VERSION "BodyCANhs"

NS_ :

BS_:

BU_: CCM CEM DDM ETC PAM PDM POT PSMD PSMP TRM VCM Y20CCMV526M1 Vector_XXX

BO_ 528 CEMBodyFr19: 8 CEM
 SG_ ActvnOfDoorLiGroup_UB : 6|1@0+ (1,0) [0|1] ""  DDM,PDM
 SG_ ActvnOfDoorLiGroupActvnOfDoorAmb : 1|2@0+ (1,0) [0|3] ""  DDM,PDM
 SG_ ActvnOfDoorLiGroupActvnOfHndlAnd : 4|1@0+ (1,0) [0|1] ""  DDM,PDM
 SG_ ActvnOfDoorLiGroupAmbLiInten : 3|2@0+ (1,0) [0|3] ""  DDM,PDM
 SG_ ActvnOfDoorLiGroupAmbLiRedn : 5|1@0+ (1,0) [0|1] ""  DDM,PDM
 SG_ ChrgrSt : 14|3@0+ (1,0) [0|7] ""  VCM
 SG_ ChrgrSt_UB : 15|1@0+ (1,0) [0|1] ""  VCM
 SG_ DrvrSeatDispSpplFct : 50|3@0+ (1,0) [0|7] ""  PSMD
 SG_ DrvrSeatDispSpplFct_UB : 51|1@0+ (1,0) [0|1] ""  PSMD
 SG_ DstToEmpty : 26|11@0+ (1,0) [0|2000] ""  Vector_XXX
 SG_ DstToEmptyIndcd_UB : 28|1@0+ (1,0) [0|1] ""  Vector_XXX
 SG_ DstUnit : 27|1@0+ (1,0) [0|1] ""  Vector_XXX
 SG_ EngCooltInhbFlow : 10|1@0+ (1,0) [0|1] ""  CCM
 SG_ EngCooltInhbFlow_UB : 11|1@0+ (1,0) [0|1] ""  CCM
 SG_ EngOilPWarn : 29|1@0+ (1,0) [0|1] ""  VCM
 SG_ EngOilPWarn_UB : 30|1@0+ (1,0) [0|1] ""  VCM
 SG_ EngT : 23|8@0+ (1,-50) [-50|200] "degC"  CCM,VCM
 SG_ EngTGrp_UB : 7|1@0+ (1,0) [0|1] ""  CCM,VCM
 SG_ EngTQf : 9|2@0+ (1,0) [0|3] ""  CCM,VCM
 SG_ HvBattHeatgReq : 57|2@0+ (1,0) [0|3] ""  CCM
 SG_ HvBattHeatgReq_UB : 31|1@0+ (1,0) [0|1] ""  CCM
 SG_ HvBattHeatrVlvPosn : 53|1@0+ (1,0) [0|1] ""  CCM
 SG_ HvBattHeatrVlvPosn_UB : 52|1@0+ (1,0) [0|1] ""  CCM
 SG_ HvPwrEgyPrio : 42|3@0+ (1,0) [0|7] ""  CCM
 SG_ HvPwrEgyPrio_UB : 43|1@0+ (1,0) [0|1] ""  CCM
 SG_ OnBdChrgrHndlSts : 46|3@0+ (1,0) [0|7] ""  CCM,VCM
 SG_ OnBdChrgrHndlSts_UB : 47|1@0+ (1,0) [0|1] ""  CCM,VCM
 SG_ PassSeatSts : 55|2@0+ (1,0) [0|3] ""  CCM,PSMP
 SG_ PassSeatSts_UB : 63|1@0+ (1,0) [0|1] ""  CCM,PSMP
 SG_ SeatDispBtnPsd_UB : 62|1@0+ (1,0) [0|1] ""  PSMD,PSMP
 SG_ SeatDispBtnPsdDrvrSeatDispBtnPsd : 61|1@0+ (1,0) [0|1] ""  PSMD,PSMP
 SG_ SeatDispBtnPsdPassSeatDispBtnPsd : 60|1@0+ (1,0) [0|1] ""  PSMD,PSMP
 SG_ SteerWhlHeatgDurgClimaEnad : 58|1@0+ (1,0) [0|1] ""  CCM
 SG_ SteerWhlHeatgDurgClimaEnad_UB : 59|1@0+ (1,0) [0|1] ""  CCM

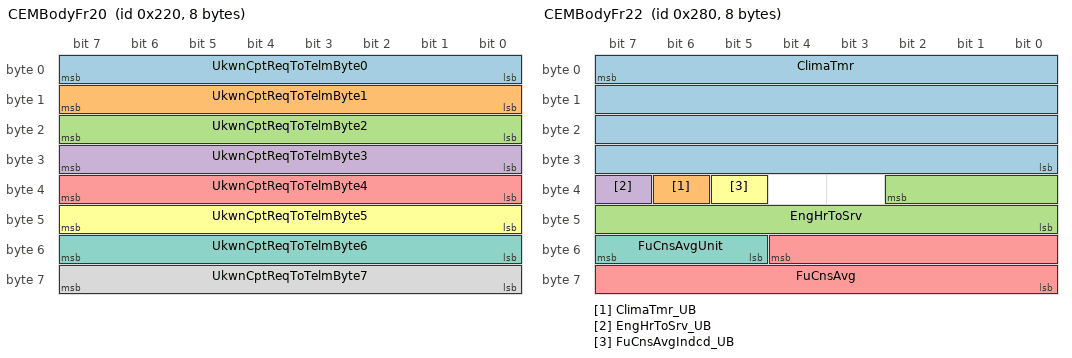
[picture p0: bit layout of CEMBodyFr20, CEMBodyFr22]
BO_ 544 CEMBodyFr20: 8 CEM
 SG_ UkwnCptReqToTelmByte0 : 7|8@0+ (1,0) [0|255] ""  VCM
 SG_ UkwnCptReqToTelmByte1 : 15|8@0+ (1,0) [0|255] ""  VCM
 SG_ UkwnCptReqToTelmByte2 : 23|8@0+ (1,0) [0|255] ""  VCM
 SG_ UkwnCptReqToTelmByte3 : 31|8@0+ (1,0) [0|255] ""  VCM
 SG_ UkwnCptReqToTelmByte4 : 39|8@0+ (1,0) [0|255] ""  VCM
 SG_ UkwnCptReqToTelmByte5 : 47|8@0+ (1,0) [0|255] ""  VCM
 SG_ UkwnCptReqToTelmByte6 : 55|8@0+ (1,0) [0|255] ""  VCM
 SG_ UkwnCptReqToTelmByte7 : 63|8@0+ (1,0) [0|255] ""  VCM

BO_ 608 CEMBodyFr21: 8 CEM
 SG_ ClimaTmrStsRqrd : 56|1@0+ (1,0) [0|1] ""  CCM
 SG_ ClimaTmrStsRqrd_UB : 57|1@0+ (1,0) [0|1] ""  CCM
 SG_ DayToSrv : 41|10@0+ (1,0) [0|750] "Days"  Vector_XXX
 SG_ DayToSrv_UB : 30|1@0+ (1,0) [0|1] ""  Vector_XXX
 SG_ DstTrvld1 : 0|17@0+ (0.1,0) [0|9999.9] "km"  VCM
 SG_ DstTrvld1_UB : 1|1@0+ (1,0) [0|1] ""  VCM
 SG_ EgySave : 31|1@0+ (1,0) [0|1] ""  CCM
 SG_ EgySave_UB : 44|1@0+ (1,0) [0|1] ""  CCM
 SG_ FuCnsIndcd_UB : 29|1@0+ (1,0) [0|1] ""  VCM
 SG_ FuCnsIndcdUnit : 28|3@0+ (1,0) [0|7] ""  VCM
 SG_ FuCnsIndcdVal : 25|13@0+ (0.1,0) [0|819.1] ""  VCM
 SG_ FuLvlLoIndcn : 42|1@0+ (1,0) [0|1] ""  VCM
 SG_ FuLvlLoIndcn_UB : 43|1@0+ (1,0) [0|1] ""  VCM
 SG_ MassgFctActv_UB : 4|1@0+ (1,0) [0|1] ""  PSMD,PSMP
 SG_ MassgFctActvDrvrMassgFctActv : 3|1@0+ (1,0) [0|1] ""  PSMD,PSMP
 SG_ MassgFctActvPassMassgFctActv : 2|1@0+ (1,0) [0|1] ""  PSMD,PSMP
 SG_ SeatHeatDurgClimaEnad : 6|2@0+ (1,0) [0|3] ""  CCM
 SG_ SeatHeatDurgClimaEnad_UB : 7|1@0+ (1,0) [0|1] ""  CCM
 SG_ SrvTrig : 61|4@0+ (1,0) [0|15] ""  Vector_XXX
 SG_ SrvTrig_UB : 62|1@0+ (1,0) [0|1] ""  Vector_XXX

BO_ 640 CEMBodyFr22: 8 CEM
 SG_ ClimaTmr : 7|32@0+ (0.1,0) [0|429496729.5] "s"  CCM
 SG_ ClimaTmr_UB : 38|1@0+ (1,0) [0|1] ""  CCM
 SG_ EngHrToSrv : 34|11@0+ (1,0) [0|2000] "hours"  Vector_XXX
 SG_ EngHrToSrv_UB : 39|1@0+ (1,0) [0|1] ""  Vector_XXX
 SG_ FuCnsAvg : 52|13@0+ (0.1,0) [0|819.1] ""  Vector_XXX
 SG_ FuCnsAvgIndcd_UB : 37|1@0+ (1,0) [0|1] ""  Vector_XXX
 SG_ FuCnsAvgUnit : 55|3@0+ (1,0) [0|7] ""  Vector_XXX

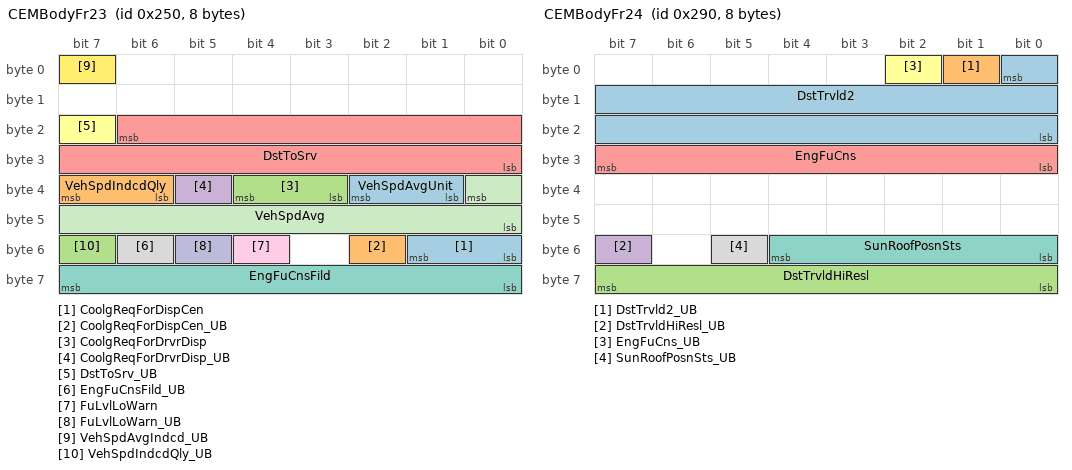
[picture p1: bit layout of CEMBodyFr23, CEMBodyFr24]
BO_ 592 CEMBodyFr23: 8 CEM
 SG_ CoolgReqForDispCen : 49|2@0+ (1,0) [0|3] ""  CCM
 SG_ CoolgReqForDispCen_UB : 50|1@0+ (1,0) [0|1] ""  CCM
 SG_ CoolgReqForDrvrDisp : 36|2@0+ (1,0) [0|3] ""  CCM
 SG_ CoolgReqForDrvrDisp_UB : 37|1@0+ (1,0) [0|1] ""  CCM
 SG_ DstToSrv : 22|15@0+ (1,0) [0|32000] "km"  Vector_XXX
 SG_ DstToSrv_UB : 23|1@0+ (1,0) [0|1] ""  Vector_XXX
 SG_ EngFuCnsFild : 63|8@0+ (200,0) [0|51000] "MicroL"  VCM
 SG_ EngFuCnsFild_UB : 54|1@0+ (1,0) [0|1] ""  VCM
 SG_ FuLvlLoWarn : 52|1@0+ (1,0) [0|1] ""  VCM
 SG_ FuLvlLoWarn_UB : 53|1@0+ (1,0) [0|1] ""  VCM
 SG_ VehSpdAvg : 32|9@0+ (1,0) [0|511] ""  VCM
 SG_ VehSpdAvgIndcd_UB : 7|1@0+ (1,0) [0|1] ""  VCM
 SG_ VehSpdAvgUnit : 34|2@0+ (1,0) [0|3] ""  VCM
 SG_ VehSpdIndcdQly : 39|2@0+ (1,0) [0|3] ""  VCM
 SG_ VehSpdIndcdQly_UB : 55|1@0+ (1,0) [0|1] ""  VCM

BO_ 656 CEMBodyFr24: 8 CEM
 SG_ DstTrvld2 : 0|17@0+ (0.1,0) [0|9999.9] "km"  VCM
 SG_ DstTrvld2_UB : 1|1@0+ (1,0) [0|1] ""  VCM
 SG_ DstTrvldHiResl : 63|8@0+ (1,0) [0|255] "m"  Vector_XXX
 SG_ DstTrvldHiResl_UB : 55|1@0+ (1,0) [0|1] ""  Vector_XXX
 SG_ EngFuCns : 31|8@0+ (200,0) [0|51000] "MicroL"  VCM
 SG_ EngFuCns_UB : 2|1@0+ (1,0) [0|1] ""  VCM
 SG_ SunRoofPosnSts : 52|5@0+ (1,0) [0|31] ""  CCM,VCM
 SG_ SunRoofPosnSts_UB : 53|1@0+ (1,0) [0|1] ""  CCM,VCM

BO_ 624 CEMBodyFr25: 8 CEM
 SG_ AbsWarnIndcnReq : 5|2@0+ (1,0) [0|3] ""  VCM
 SG_ BrkAndAbsWarnIndcnReqChks : 15|8@0+ (1,0) [0|255] ""  VCM
 SG_ BrkAndAbsWarnIndcnReqCntr : 3|4@0+ (1,0) [0|15] ""  VCM
 SG_ BrkAndAbsWarnIndcnReqGroup_UB : 7|1@0+ (1,0) [0|1] ""  VCM
 SG_ BrkWarnIndcnReq : 6|1@0+ (1,0) [0|1] ""  VCM
 SG_ EngSt1WdSts : 47|4@0+ (1,0) [0|15] ""  CCM
 SG_ EngSt1WdSts_UB : 63|1@0+ (1,0) [0|1] ""  CCM
 SG_ FuLvlIndcd_UB : 23|1@0+ (1,0) [0|1] ""  VCM
 SG_ FuLvlIndcdQly : 43|2@0+ (1,0) [0|3] ""  VCM
 SG_ FuLvlIndcdVal : 41|10@0+ (0.2,0) [0|204.6] "Litre"  VCM
 SG_ NetHdActvt_UB : 38|1@0+ (1,0) [0|1] ""  Vector_XXX
 SG_ NetHdActvtPrio : 16|1@0+ (1,0) [0|1] ""  Vector_XXX
 SG_ NetHdActvtResourceGroup : 31|8@0+ (1,0) [0|255] ""  Vector_XXX
 SG_ NotifForEmgyCall : 37|1@0+ (1,0) [0|1] ""  VCM
 SG_ NotifForEmgyCall_UB : 36|1@0+ (1,0) [0|1] ""  VCM
 SG_ PassSeatDispSpplFct : 35|3@0+ (1,0) [0|7] ""  PSMP
 SG_ PassSeatDispSpplFct_UB : 32|1@0+ (1,0) [0|1] ""  PSMP
 SG_ SteerWhlHeatgOnReq : 61|2@0+ (1,0) [0|3] ""  CCM
 SG_ SteerWhlHeatgOnReq_UB : 62|1@0+ (1,0) [0|1] ""  CCM

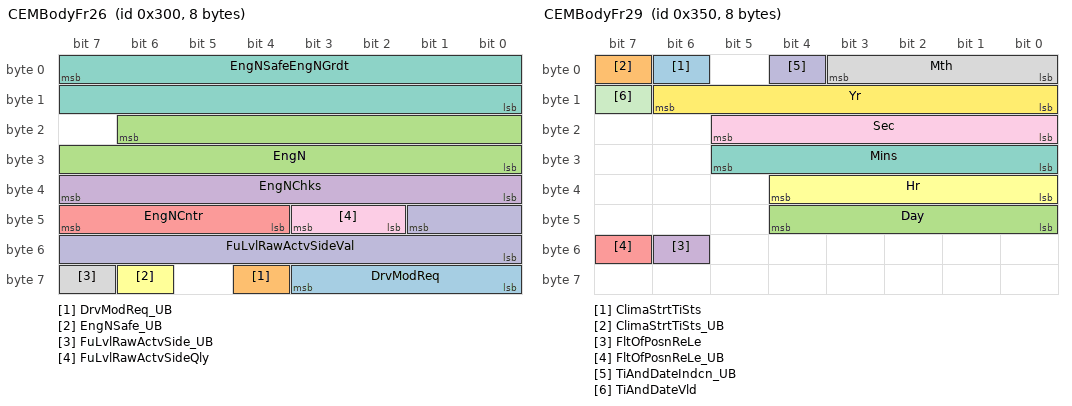
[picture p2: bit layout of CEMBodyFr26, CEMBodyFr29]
BO_ 768 CEMBodyFr26: 8 CEM
 SG_ DrvModReq : 59|4@0+ (1,0) [0|15] ""  CCM
 SG_ DrvModReq_UB : 60|1@0+ (1,0) [0|1] ""  CCM
 SG_ EngN : 22|15@0+ (0.5,0) [0|16383.5] "rpm"  CCM
 SG_ EngNChks : 39|8@0+ (1,0) [0|255] ""  CCM
 SG_ EngNCntr : 47|4@0+ (1,0) [0|15] ""  CCM
 SG_ EngNSafe_UB : 62|1@0+ (1,0) [0|1] ""  CCM
 SG_ EngNSafeEngNGrdt : 7|16@0- (1,0) [-30000|32767] "RpmPerSec"  CCM
 SG_ FuLvlRawActvSide_UB : 63|1@0+ (1,0) [0|1] ""  CCM
 SG_ FuLvlRawActvSideQly : 43|2@0+ (1,0) [0|3] ""  CCM
 SG_ FuLvlRawActvSideVal : 41|10@0+ (0.2,0) [0|204.6] "Litre"  CCM

BO_ 784 CEMBodyFr27: 8 CEM
 SG_ BkpOfDstTrvld : 4|21@0+ (1,0) [0|2000000] "km"  CCM,DDM,PDM,POT,PSMD,PSMP,TRM
 SG_ BkpOfDstTrvld_UB : 5|1@0+ (1,0) [0|1] ""  CCM,DDM,PDM,POT,PSMD,PSMP,TRM
 SG_ ClkFmt : 47|2@0+ (1,0) [0|3] ""  Vector_XXX
 SG_ DstLong : 45|2@0+ (1,0) [0|3] ""  Vector_XXX
 SG_ DstSho : 43|2@0+ (1,0) [0|3] ""  Vector_XXX
 SG_ FltIndcrTurnRiFrnt : 28|1@0+ (1,0) [0|1] ""  VCM
 SG_ FltIndcrTurnRiFrnt_UB : 29|1@0+ (1,0) [0|1] ""  VCM
 SG_ FltIndcrTurnRiRe : 30|1@0+ (1,0) [0|1] ""  VCM
 SG_ FltIndcrTurnRiRe_UB : 31|1@0+ (1,0) [0|1] ""  VCM
 SG_ FuCnsUnit : 55|3@0+ (1,0) [0|7] ""  Vector_XXX
 SG_ IdPenForUnits : 63|4@0+ (1,0) [0|15] ""  Vector_XXX
 SG_ IndcnUnit_UB : 7|1@0+ (1,0) [0|1] ""  Vector_XXX
 SG_ IndcnUnitDateFmt : 41|2@0+ (1,0) [0|3] ""  Vector_XXX
 SG_ PUnit : 52|3@0+ (1,0) [0|7] ""  Vector_XXX
 SG_ SpdUnit : 49|2@0+ (1,0) [0|3] ""  Vector_XXX
 SG_ TUnit : 59|2@0+ (1,0) [0|3] ""  Vector_XXX
 SG_ VolUnit : 57|2@0+ (1,0) [0|3] ""  Vector_XXX

BO_ 464 CEMBodyFr28: 8 CEM
 SG_ AmbTIndcd : 3|12@0+ (0.1,-100) [-100|309.5] ""  Vector_XXX
 SG_ AmbTIndcdQf : 5|2@0+ (1,0) [0|3] ""  Vector_XXX
 SG_ AmbTIndcdUnit : 7|2@0+ (1,0) [0|3] ""  Vector_XXX
 SG_ AmbTIndcdWithUnit_UB : 23|1@0+ (1,0) [0|1] ""  Vector_XXX
 SG_ AmbTRaw_UB : 20|1@0+ (1,0) [0|1] ""  CCM,DDM,PDM
 SG_ AmbTRawQly : 52|2@0+ (1,0) [0|3] ""  CCM,DDM,PDM
 SG_ AmbTRawVal : 50|11@0+ (0.1,-70) [-70|134.7] "degC"  CCM,DDM,PDM
 SG_ FltOfBeamLoLe : 38|1@0+ (1,0) [0|1] ""  VCM
 SG_ FltOfBeamLoLe_UB : 39|1@0+ (1,0) [0|1] ""  VCM
 SG_ FltOfBrkLiHiMntd : 44|1@0+ (1,0) [0|1] ""  VCM
 SG_ FltOfBrkLiHiMntd_UB : 45|1@0+ (1,0) [0|1] ""  VCM
 SG_ FltOfPlateNr : 46|1@0+ (1,0) [0|1] ""  VCM
 SG_ FltOfPlateNr_UB : 47|1@0+ (1,0) [0|1] ""  VCM
 SG_ FltOfPosnReRi : 54|1@0+ (1,0) [0|1] ""  VCM
 SG_ FltOfPosnReRi_UB : 55|1@0+ (1,0) [0|1] ""  VCM
 SG_ RlyPwrDistbnCmd1WdPreBattSaveCmd : 21|1@0+ (1,0) [0|1] ""  PSMD,PSMP
 SG_ RlyPwrDistbnCmd1WdPreBattSa_0000 : 22|1@0+ (1,0) [0|1] ""  PSMD,PSMP
 SG_ VehSpdIndcd_UB : 19|1@0+ (1,0) [0|1] ""  VCM
 SG_ VehSpdIndcdUnit : 18|2@0+ (1,0) [0|3] ""  VCM
 SG_ VehSpdIndcdVal : 16|9@0+ (1,0) [0|511] ""  VCM
 SG_ WipgInfo_UB : 37|1@0+ (1,0) [0|1] ""  CCM
 SG_ WipgInfoWipgSpdInfo : 34|3@0+ (1,0) [0|7] ""  CCM
 SG_ WipgInfoWiprActv : 35|1@0+ (1,0) [0|1] ""  CCM
 SG_ WipgInfoWiprInWipgAr : 36|1@0+ (1,0) [0|1] ""  CCM

BO_ 848 CEMBodyFr29: 8 CEM
 SG_ ClimaStrtTiSts : 6|1@0+ (1,0) [0|1] ""  CCM
 SG_ ClimaStrtTiSts_UB : 7|1@0+ (1,0) [0|1] ""  CCM
 SG_ Day : 44|5@0+ (1,0) [1|31] "Days"  VCM
 SG_ FltOfPosnReLe : 54|1@0+ (1,0) [0|1] ""  VCM
 SG_ FltOfPosnReLe_UB : 55|1@0+ (1,0) [0|1] ""  VCM
 SG_ Hr : 36|5@0+ (1,0) [0|23] "hours"  VCM
 SG_ Mins : 29|6@0+ (1,0) [0|59] "Mins"  VCM
 SG_ Mth : 3|4@0+ (1,0) [1|12] "Month"  VCM
 SG_ Sec : 21|6@0+ (1,0) [0|59] "s"  VCM
 SG_ TiAndDateIndcn_UB : 4|1@0+ (1,0) [0|1] ""  VCM
 SG_ TiAndDateVld : 15|1@0+ (1,0) [0|1] ""  VCM
 SG_ Yr : 14|7@0+ (1,0) [0|99] "Year"  VCM

BO_ 880 CEMBodyFr30: 8 CEM
 SG_ CarTiGlb : 39|32@0+ (0.1,0) [0|429496729.5] "s"  CCM,DDM,PDM,POT,PSMD,PSMP,TRM
 SG_ CarTiGlb_UB : 13|1@0+ (1,0) [0|1] ""  CCM,DDM,PDM,POT,PSMD,PSMP,TRM
 SG_ ClimaCmd : 14|1@0+ (1,0) [0|1] ""  CCM
 SG_ ClimaCmd_UB : 15|1@0+ (1,0) [0|1] ""  CCM
 SG_ EgyCnsAllwdForClima : 6|7@0+ (1,0) [0|127] "Wh"  CCM
 SG_ EgyCnsAllwdForClima_UB : 7|1@0+ (1,0) [0|1] ""  CCM
 SG_ FltFogLiRe : 16|1@0+ (1,0) [0|1] ""  VCM
 SG_ FltFogLiRe_UB : 17|1@0+ (1,0) [0|1] ""  VCM
 SG_ FltIndcrTurnLeFrnt : 18|1@0+ (1,0) [0|1] ""  VCM
 SG_ FltIndcrTurnLeFrnt_UB : 19|1@0+ (1,0) [0|1] ""  VCM
 SG_ FltLiSideMkrFrnt : 20|1@0+ (1,0) [0|1] ""  VCM
 SG_ FltLiSideMkrFrnt_UB : 21|1@0+ (1,0) [0|1] ""  VCM
 SG_ FltOfBeamHiLe : 22|1@0+ (1,0) [0|1] ""  VCM
 SG_ FltOfBeamHiLe_UB : 23|1@0+ (1,0) [0|1] ""  VCM
 SG_ FltOfBeamHiRi : 24|1@0+ (1,0) [0|1] ""  VCM
 SG_ FltOfBeamHiRi_UB : 25|1@0+ (1,0) [0|1] ""  VCM
 SG_ FltOfBeamLoRi : 30|1@0+ (1,0) [0|1] ""  VCM
 SG_ FltOfBeamLoRi_UB : 31|1@0+ (1,0) [0|1] ""  VCM
 SG_ FltOfLiPosnFrntLe : 26|1@0+ (1,0) [0|1] ""  VCM
 SG_ FltOfLiPosnFrntLe_UB : 27|1@0+ (1,0) [0|1] ""  VCM
 SG_ PwrSplyErrSts : 11|4@0+ (1,0) [0|15] ""  VCM
 SG_ PwrSplyErrSts_UB : 12|1@0+ (1,0) [0|1] ""  VCM
 SG_ WshrFldSts : 28|1@0+ (1,0) [0|1] ""  VCM
 SG_ WshrFldSts_UB : 29|1@0+ (1,0) [0|1] ""  VCM

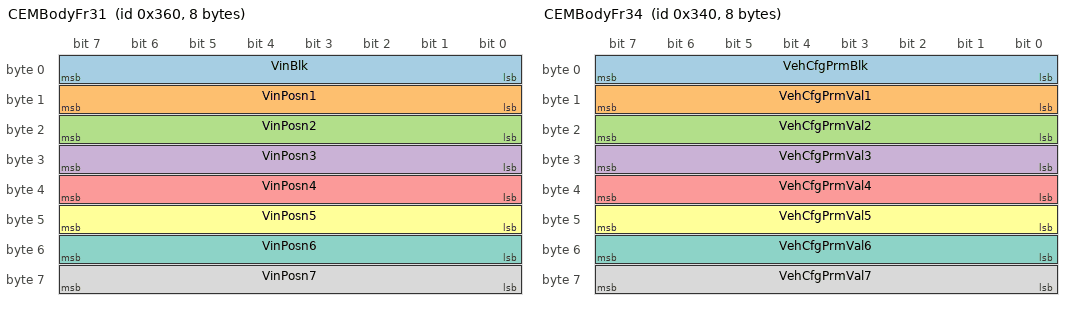
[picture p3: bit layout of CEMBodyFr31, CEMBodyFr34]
BO_ 864 CEMBodyFr31: 8 CEM
 SG_ VinBlk : 7|8@0+ (1,0) [0|255] ""  ETC
 SG_ VinPosn1 : 15|8@0+ (1,0) [0|255] ""  ETC
 SG_ VinPosn2 : 23|8@0+ (1,0) [0|255] ""  ETC
 SG_ VinPosn3 : 31|8@0+ (1,0) [0|255] ""  ETC
 SG_ VinPosn4 : 39|8@0+ (1,0) [0|255] ""  ETC
 SG_ VinPosn5 : 47|8@0+ (1,0) [0|255] ""  ETC
 SG_ VinPosn6 : 55|8@0+ (1,0) [0|255] ""  ETC
 SG_ VinPosn7 : 63|8@0+ (1,0) [0|255] ""  ETC

BO_ 896 CEMBodyFr32: 8 CEM
 SG_ AntithftActvnNotif : 36|1@0+ (1,0) [0|1] ""  VCM
 SG_ AntithftActvnNotif_UB : 37|1@0+ (1,0) [0|1] ""  VCM
 SG_ ClimaPwrAllwd : 34|11@0+ (1,0) [0|2047] "W"  CCM
 SG_ ClimaPwrAllwd_UB : 35|1@0+ (1,0) [0|1] ""  CCM
 SG_ CurtReDirCmd : 51|2@0+ (1,0) [0|3] ""  POT
 SG_ CurtReDirCmd_UB : 38|1@0+ (1,0) [0|1] ""  POT
 SG_ FltLiDaytiRunngLe : 48|1@0+ (1,0) [0|1] ""  VCM
 SG_ FltLiDaytiRunngLe_UB : 49|1@0+ (1,0) [0|1] ""  VCM
 SG_ FltOfBrkLiLe : 52|1@0+ (1,0) [0|1] ""  VCM
 SG_ FltOfBrkLiLe_UB : 53|1@0+ (1,0) [0|1] ""  VCM
 SG_ FltOfLiDaytiRunngRi : 54|1@0+ (1,0) [0|1] ""  VCM
 SG_ FltOfLiDaytiRunngRi_UB : 55|1@0+ (1,0) [0|1] ""  VCM
 SG_ FltOfLiPosnFrntRi : 62|1@0+ (1,0) [0|1] ""  VCM
 SG_ FltOfLiPosnFrntRi_UB : 63|1@0+ (1,0) [0|1] ""  VCM
 SG_ IndcrPatCmd1WdCmd_UB : 39|1@0+ (1,0) [0|1] ""  DDM,PDM,TRM
 SG_ IndcrPatCmd1WdTiOff : 7|16@0+ (0.001,0) [0|65.535] "s"  DDM,PDM,TRM
 SG_ IndcrPatCmd1WdTiOn : 23|16@0+ (0.001,0) [0|65.535] "s"  DDM,PDM,TRM
 SG_ StrtRemSts1WdStrtRemSts : 57|2@0+ (1,0) [0|3] ""  CCM
 SG_ StrtRemSts1WdStrtRemSts_UB : 58|1@0+ (1,0) [0|1] ""  CCM
 SG_ TrLockSts : 61|2@0+ (1,0) [0|3] ""  VCM
 SG_ TrLockSts_UB : 59|1@0+ (1,0) [0|1] ""  VCM

BO_ 816 CEMBodyFr33: 8 CEM
 SG_ FltIndcrTurnLeRe : 24|1@0+ (1,0) [0|1] ""  VCM
 SG_ FltIndcrTurnLeRe_UB : 25|1@0+ (1,0) [0|1] ""  VCM
 SG_ FltOfBrkLiRi : 26|1@0+ (1,0) [0|1] ""  VCM
 SG_ FltOfBrkLiRi_UB : 27|1@0+ (1,0) [0|1] ""  VCM
 SG_ FltOfFogLiFrnt : 28|1@0+ (1,0) [0|1] ""  VCM
 SG_ FltOfFogLiFrnt_UB : 29|1@0+ (1,0) [0|1] ""  VCM
 SG_ ProfPenSts1 : 23|4@0+ (1,0) [0|15] ""  DDM
 SG_ ProfPenSts1_UB : 7|1@0+ (1,0) [0|1] ""  DDM
 SG_ TirePFrntLe : 15|2@0+ (1,0) [0|3] ""  VCM
 SG_ TirePFrntRi : 13|2@0+ (1,0) [0|3] ""  VCM
 SG_ TirePMonData_UB : 6|1@0+ (1,0) [0|1] ""  VCM
 SG_ TirePMonSts : 3|4@0+ (1,0) [0|15] ""  VCM
 SG_ TirePReLe : 5|2@0+ (1,0) [0|3] ""  VCM
 SG_ TirePReRi : 9|2@0+ (1,0) [0|3] ""  VCM
 SG_ VehBattUGroup_UB : 45|1@0+ (1,0) [0|1] ""  CCM,DDM,PDM,POT,PSMD,PSMP,TRM
 SG_ VehBattUSysU : 39|8@0+ (0.1,0) [0|25] "Volt"  CCM,DDM,PDM,POT,PSMD,PSMP,TRM
 SG_ VehBattUSysUQf : 47|2@0+ (1,0) [0|3] ""  CCM,DDM,PDM,POT,PSMD,PSMP,TRM

BO_ 832 CEMBodyFr34: 8 CEM
 SG_ VehCfgPrmBlk : 7|8@0+ (1,0) [0|255] ""  CCM,DDM,PDM,POT,PSMD,PSMP,TRM
 SG_ VehCfgPrmVal1 : 15|8@0+ (1,0) [0|255] ""  CCM,DDM,PDM,POT,PSMD,PSMP,TRM
 SG_ VehCfgPrmVal2 : 23|8@0+ (1,0) [0|255] ""  CCM,DDM,PDM,POT,PSMD,PSMP,TRM
 SG_ VehCfgPrmVal3 : 31|8@0+ (1,0) [0|255] ""  CCM,DDM,PDM,POT,PSMD,PSMP,TRM
 SG_ VehCfgPrmVal4 : 39|8@0+ (1,0) [0|255] ""  CCM,DDM,PDM,POT,PSMD,PSMP,TRM
 SG_ VehCfgPrmVal5 : 47|8@0+ (1,0) [0|255] ""  CCM,DDM,PDM,POT,PSMD,PSMP,TRM
 SG_ VehCfgPrmVal6 : 55|8@0+ (1,0) [0|255] ""  CCM,DDM,PDM,POT,PSMD,PSMP,TRM
 SG_ VehCfgPrmVal7 : 63|8@0+ (1,0) [0|255] ""  CCM,DDM,PDM,POT,PSMD,PSMP,TRM

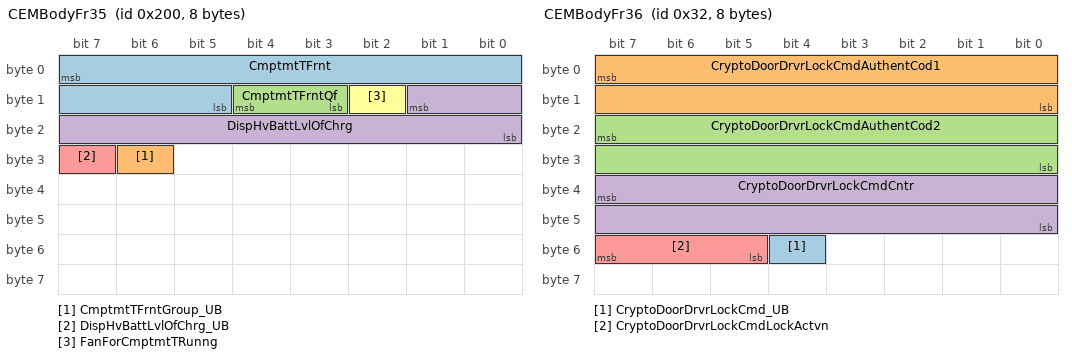
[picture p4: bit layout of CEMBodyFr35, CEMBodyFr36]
BO_ 512 CEMBodyFr35: 8 CEM
 SG_ CmptmtTFrnt : 7|11@0+ (0.1,-60) [-60|125] "degC"  VCM
 SG_ CmptmtTFrntGroup_UB : 30|1@0+ (1,0) [0|1] ""  VCM
 SG_ CmptmtTFrntQf : 12|2@0+ (1,0) [0|3] ""  VCM
 SG_ DispHvBattLvlOfChrg : 9|10@0+ (0.1,0) [0|102.3] "%"  VCM
 SG_ DispHvBattLvlOfChrg_UB : 31|1@0+ (1,0) [0|1] ""  VCM
 SG_ FanForCmptmtTRunng : 10|1@0+ (1,0) [0|1] ""  VCM

BO_ 50 CEMBodyFr36: 8 CEM
 SG_ CryptoDoorDrvrLockCmd_UB : 52|1@0+ (1,0) [0|1] ""  DDM
 SG_ CryptoDoorDrvrLockCmdAuthentCod1 : 7|16@0+ (1,0) [0|65535] ""  DDM
 SG_ CryptoDoorDrvrLockCmdAuthentCod2 : 23|16@0+ (1,0) [0|65535] ""  DDM
 SG_ CryptoDoorDrvrLockCmdCntr : 39|16@0+ (1,0) [0|65535] ""  DDM
 SG_ CryptoDoorDrvrLockCmdLockActvn : 55|3@0+ (1,0) [0|7] ""  DDM

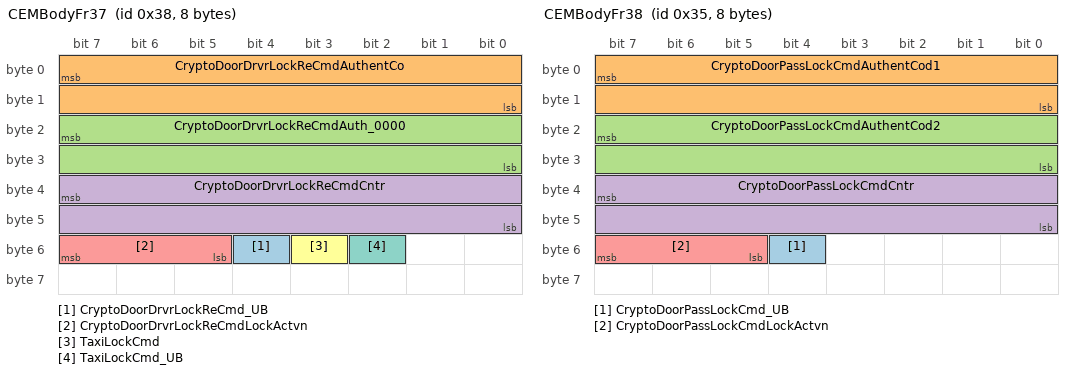
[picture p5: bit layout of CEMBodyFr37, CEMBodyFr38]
BO_ 56 CEMBodyFr37: 8 CEM
 SG_ CryptoDoorDrvrLockReCmd_UB : 52|1@0+ (1,0) [0|1] ""  DDM
 SG_ CryptoDoorDrvrLockReCmdAuthentCo : 7|16@0+ (1,0) [0|65535] ""  DDM
 SG_ CryptoDoorDrvrLockReCmdAuth_0000 : 23|16@0+ (1,0) [0|65535] ""  DDM
 SG_ CryptoDoorDrvrLockReCmdCntr : 39|16@0+ (1,0) [0|65535] ""  DDM
 SG_ CryptoDoorDrvrLockReCmdLockActvn : 55|3@0+ (1,0) [0|7] ""  DDM
 SG_ TaxiLockCmd : 51|1@0+ (1,0) [0|1] ""  DDM,PDM
 SG_ TaxiLockCmd_UB : 50|1@0+ (1,0) [0|1] ""  DDM,PDM

BO_ 53 CEMBodyFr38: 8 CEM
 SG_ CryptoDoorPassLockCmd_UB : 52|1@0+ (1,0) [0|1] ""  PDM
 SG_ CryptoDoorPassLockCmdAuthentCod1 : 7|16@0+ (1,0) [0|65535] ""  PDM
 SG_ CryptoDoorPassLockCmdAuthentCod2 : 23|16@0+ (1,0) [0|65535] ""  PDM
 SG_ CryptoDoorPassLockCmdCntr : 39|16@0+ (1,0) [0|65535] ""  PDM
 SG_ CryptoDoorPassLockCmdLockActvn : 55|3@0+ (1,0) [0|7] ""  PDM

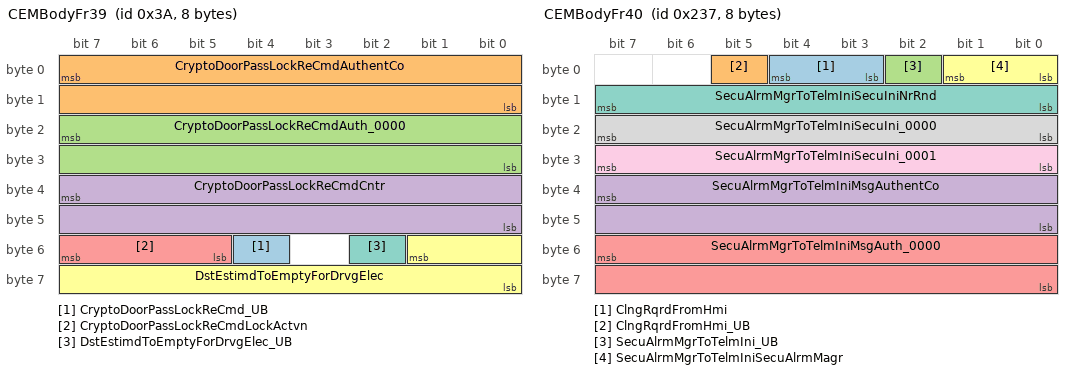
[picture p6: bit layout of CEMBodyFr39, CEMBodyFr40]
BO_ 58 CEMBodyFr39: 8 CEM
 SG_ CryptoDoorPassLockReCmd_UB : 52|1@0+ (1,0) [0|1] ""  PDM
 SG_ CryptoDoorPassLockReCmdAuthentCo : 7|16@0+ (1,0) [0|65535] ""  PDM
 SG_ CryptoDoorPassLockReCmdAuth_0000 : 23|16@0+ (1,0) [0|65535] ""  PDM
 SG_ CryptoDoorPassLockReCmdCntr : 39|16@0+ (1,0) [0|65535] ""  PDM
 SG_ CryptoDoorPassLockReCmdLockActvn : 55|3@0+ (1,0) [0|7] ""  PDM
 SG_ DstEstimdToEmptyForDrvgElec : 49|10@0+ (1,0) [0|1023] "KiloMtr"  VCM
 SG_ DstEstimdToEmptyForDrvgElec_UB : 50|1@0+ (1,0) [0|1] ""  VCM

BO_ 567 CEMBodyFr40: 8 CEM
 SG_ ClngRqrdFromHmi : 4|2@0+ (1,0) [0|3] ""  CCM
 SG_ ClngRqrdFromHmi_UB : 5|1@0+ (1,0) [0|1] ""  CCM
 SG_ SecuAlrmMgrToTelmIni_UB : 2|1@0+ (1,0) [0|1] ""  VCM
 SG_ SecuAlrmMgrToTelmIniMsgAuthentCo : 39|16@0+ (1,0) [0|65535] ""  VCM
 SG_ SecuAlrmMgrToTelmIniMsgAuth_0000 : 55|16@0+ (1,0) [0|65535] ""  VCM
 SG_ SecuAlrmMgrToTelmIniSecuAlrmMagr : 1|2@0+ (1,0) [0|3] ""  VCM
 SG_ SecuAlrmMgrToTelmIniSecuIniNrRnd : 15|8@0+ (1,0) [0|255] ""  VCM
 SG_ SecuAlrmMgrToTelmIniSecuIni_0000 : 23|8@0+ (1,0) [0|255] ""  VCM
 SG_ SecuAlrmMgrToTelmIniSecuIni_0001 : 31|8@0+ (1,0) [0|255] ""  VCM

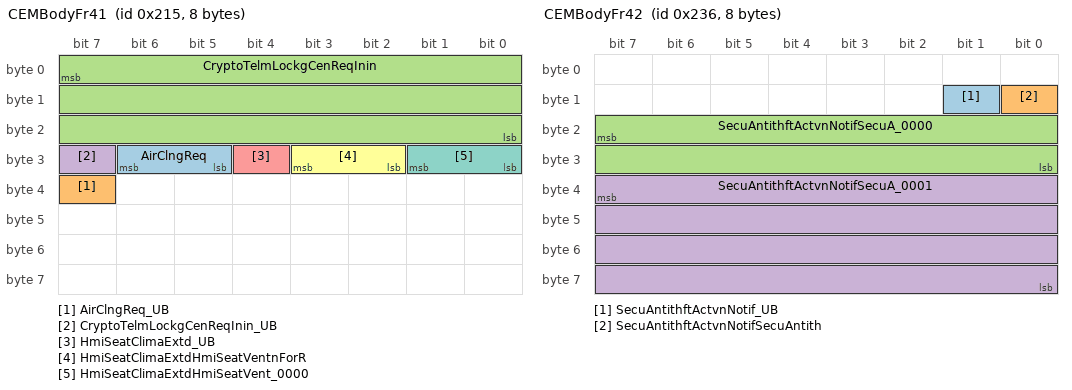
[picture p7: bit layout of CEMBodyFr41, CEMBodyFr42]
BO_ 533 CEMBodyFr41: 8 CEM
 SG_ AirClngReq : 30|2@0+ (1,0) [0|3] ""  CCM
 SG_ AirClngReq_UB : 39|1@0+ (1,0) [0|1] ""  CCM
 SG_ CryptoTelmLockgCenReqInin : 7|24@0+ (1,0) [0|16777215] ""  VCM
 SG_ CryptoTelmLockgCenReqInin_UB : 31|1@0+ (1,0) [0|1] ""  VCM
 SG_ HmiSeatClimaExtd_UB : 28|1@0+ (1,0) [0|1] ""  CCM
 SG_ HmiSeatClimaExtdHmiSeatVentnForR : 27|2@0+ (1,0) [0|3] ""  CCM
 SG_ HmiSeatClimaExtdHmiSeatVent_0000 : 25|2@0+ (1,0) [0|3] ""  CCM

BO_ 566 CEMBodyFr42: 8 CEM
 SG_ SecuAntithftActvnNotif_UB : 9|1@0+ (1,0) [0|1] ""  VCM
 SG_ SecuAntithftActvnNotifSecuAntith : 8|1@0+ (1,0) [0|1] ""  VCM
 SG_ SecuAntithftActvnNotifSecuA_0000 : 23|16@0+ (1,0) [0|65535] ""  VCM
 SG_ SecuAntithftActvnNotifSecuA_0001 : 39|32@0+ (1,0) [0|4294967295] ""  VCM

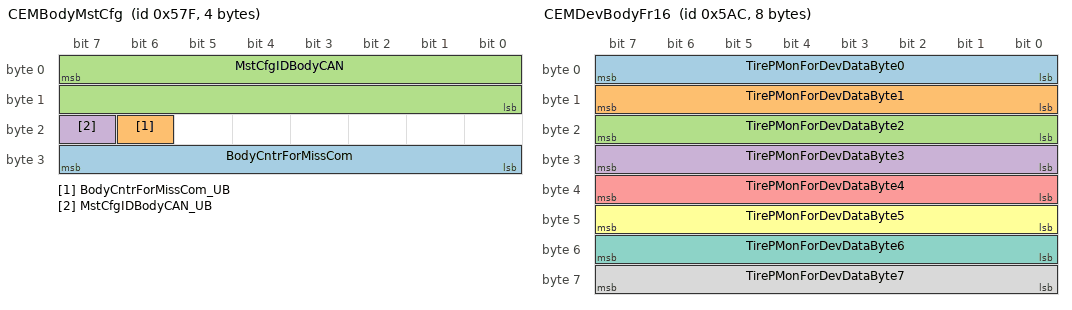
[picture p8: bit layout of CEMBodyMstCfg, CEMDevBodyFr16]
BO_ 1407 CEMBodyMstCfg: 4 CEM
 SG_ BodyCntrForMissCom : 31|8@0+ (1,0) [0|255] ""  CCM,DDM,PDM,POT,PSMD,PSMP,TRM,VCM
 SG_ BodyCntrForMissCom_UB : 22|1@0+ (1,0) [0|1] ""  CCM,DDM,PDM,POT,PSMD,PSMP,TRM,VCM
 SG_ MstCfgIDBodyCAN : 7|16@0+ (1,0) [0|65535] ""  CCM,DDM,PDM,POT,PSMD,PSMP,TRM,VCM
 SG_ MstCfgIDBodyCAN_UB : 23|1@0+ (1,0) [0|1] ""  CCM,DDM,PDM,POT,PSMD,PSMP,TRM,VCM

BO_ 1281 CemBodyNMFr: 8 CEM
 SG_ PNC23_Spare1_CEM : 39|1@0+ (1,0) [0|0] ""  ETC
 SG_ PNC22_Spare2_CEM : 38|1@0+ (1,0) [0|0] ""  ETC
 SG_ PNC21_Spare3_CEM : 37|1@0+ (1,0) [0|0] ""  ETC
 SG_ PNC20_Spare4_CEM : 36|1@0+ (1,0) [0|0] ""  ETC
 SG_ PNC19_Spare5_CEM : 35|1@0+ (1,0) [0|0] ""  ETC
 SG_ PNC18_Spare6_CEM : 34|1@0+ (1,0) [0|0] ""  ETC
 SG_ PNC17_Spare7_CEM : 33|1@0+ (1,0) [0|0] ""  ETC
 SG_ PNC16_Diesel_CEM : 32|1@0+ (1,0) [0|0] ""  ETC
 SG_ PNC15_DriverInfoPoll_CEM : 31|1@0+ (1,0) [0|0] ""  ETC
 SG_ PNC14_GSD_CEM : 30|1@0+ (1,0) [0|0] ""  ETC
 SG_ PNC13_Global_CEM : 29|1@0+ (1,0) [0|0] ""  ETC
 SG_ PNC12_TrailerCaravan_CEM : 28|1@0+ (1,0) [0|0] ""  ETC
 SG_ PNC11_Driving_CEM : 27|1@0+ (1,0) [0|0] ""  ETC
 SG_ PNC10_PreClimatization_CEM : 26|1@0+ (1,0) [0|0] ""  ETC
 SG_ PNC9_Charging_CEM : 25|1@0+ (1,0) [0|0] ""  ETC
 SG_ PNC8_Start_CEM : 24|1@0+ (1,0) [0|0] ""  ETC
 SG_ PNC7_Entrance_CEM : 23|1@0+ (1,0) [0|0] ""  ETC
 SG_ PNC6_InfotainmentHMI_CEM : 22|1@0+ (1,0) [0|0] ""  ETC
 SG_ PNC5_Body_CEM : 21|1@0+ (1,0) [0|0] ""  ETC
 SG_ PNC4_Visibility_CEM : 20|1@0+ (1,0) [0|0] ""  ETC
 SG_ PNC3_WarningSounds_CEM : 19|1@0+ (1,0) [0|0] ""  ETC
 SG_ PNC2_Hazard_CEM : 18|1@0+ (1,0) [0|0] ""  ETC
 SG_ PNC1_Locking_CEM : 17|1@0+ (1,0) [0|0] ""  ETC
 SG_ PNC0_DriverInfo_CEM : 16|1@0+ (1,0) [0|0] ""  ETC
 SG_ NM_AW_CEM : 12|1@0+ (1,0) [0|0] ""  ETC
 SG_ NM_CS_CEM : 11|1@0+ (1,0) [0|0] ""  ETC
 SG_ NM_RMR_CEM : 8|1@0+ (1,0) [0|0] ""  ETC
 SG_ NM_PNI_CEM : 14|1@0+ (1,0) [0|0] ""  ETC
 SG_ NM_NodeID_CEM : 7|8@0+ (1,0) [0|0] ""  ETC

BO_ 1452 CEMDevBodyFr16: 8 CEM
 SG_ TirePMonForDevDataByte0 : 7|8@0+ (1,0) [0|255] ""  ETC
 SG_ TirePMonForDevDataByte1 : 15|8@0+ (1,0) [0|255] ""  ETC
 SG_ TirePMonForDevDataByte2 : 23|8@0+ (1,0) [0|255] ""  ETC
 SG_ TirePMonForDevDataByte3 : 31|8@0+ (1,0) [0|255] ""  ETC
 SG_ TirePMonForDevDataByte4 : 39|8@0+ (1,0) [0|255] ""  ETC
 SG_ TirePMonForDevDataByte5 : 47|8@0+ (1,0) [0|255] ""  ETC
 SG_ TirePMonForDevDataByte6 : 55|8@0+ (1,0) [0|255] ""  ETC
 SG_ TirePMonForDevDataByte7 : 63|8@0+ (1,0) [0|255] ""  ETC

BO_ 2047 CemToAllFuncBodyDiagReqFrame: 8 CEM

BO_ 1809 CemToCcmBodyDiagReqFrame: 8 CEM

BO_ 1810 CemToDdmBodyDiagReqFrame: 8 CEM

BO_ 1413 CEMtoETCXCPFr01: 8 CEM

BO_ 1414 CEMtoETCXCPFr02: 8 CEM

BO_ 1415 CEMtoETCXCPFr03: 8 CEM

BO_ 1416 CEMtoETCXCPFr04: 8 CEM

BO_ 1811 CemToPdmBodyDiagReqFrame: 8 CEM

BO_ 1813 CemToPotBodyDiagReqFrame: 8 CEM

BO_ 1812 CemToPsmdBodyDiagReqFrame: 8 CEM

BO_ 1818 CemToPsmpBodyDiagReqFrame: 8 CEM

BO_ 1815 CemToTrmBodyDiagReqFrame: 8 CEM

BO_ 48 DDMBodyFr01: 8 DDM
 SG_ ChdLockgProtnFailrStsToHmi : 9|2@0+ (1,0) [0|3] ""  CEM
 SG_ ChdLockgProtnFailrStsToHmi_UB : 7|1@0+ (1,0) [0|1] ""  CEM
 SG_ ChdLockgProtnStsToHmi : 23|2@0+ (1,0) [0|3] ""  CEM
 SG_ ChdLockgProtnStsToHmi_UB : 6|1@0+ (1,0) [0|1] ""  CEM
 SG_ ChdProtnCmd : 45|1@0+ (1,0) [0|1] ""  PDM
 SG_ ChdProtnCmd_UB : 44|1@0+ (1,0) [0|1] ""  PDM
 SG_ CrashUnlckFailrStsAtDrvrRe : 43|2@0+ (1,0) [0|3] ""  CEM
 SG_ CrashUnlckFailrStsAtDrvrRe_UB : 15|1@0+ (1,0) [0|1] ""  CEM
 SG_ DoorBtnPsdAtDrvr : 31|1@0+ (1,0) [0|1] ""  CEM
 SG_ DoorBtnPsdAtDrvr_UB : 4|1@0+ (1,0) [0|1] ""  CEM
 SG_ DoorDrvrLockReSts : 21|2@0+ (1,0) [0|3] ""  CEM,VCM
 SG_ DoorDrvrLockReSts_UB : 5|1@0+ (1,0) [0|1] ""  CEM,VCM
 SG_ DoorDrvrLockSts : 19|2@0+ (1,0) [0|3] ""  CEM,VCM
 SG_ DoorDrvrLockSts_UB : 3|1@0+ (1,0) [0|1] ""  CEM,VCM
 SG_ DoorDrvrSwtIntrLockgReq : 17|2@0+ (1,0) [0|3] ""  CEM
 SG_ DoorDrvrSwtIntrLockgReq_UB : 2|1@0+ (1,0) [0|1] ""  CEM
 SG_ DoorDrvrSwtLockgReSts : 49|1@0+ (1,0) [0|1] ""  CEM
 SG_ DoorDrvrSwtLockgReSts_UB : 48|1@0+ (1,0) [0|1] ""  CEM
 SG_ LcmaLedStsDrvrSide : 29|1@0+ (1,0) [0|1] ""  CEM
 SG_ LcmaLedStsDrvrSide_UB : 0|1@0+ (1,0) [0|1] ""  CEM
 SG_ MemBtn1 : 14|1@0+ (1,0) [0|1] ""  CEM
 SG_ MemBtn2 : 13|1@0+ (1,0) [0|1] ""  CEM
 SG_ MemBtn3 : 12|1@0+ (1,0) [0|1] ""  CEM
 SG_ MemBtnM : 11|1@0+ (1,0) [0|1] ""  CEM
 SG_ MemBtnPsd_UB : 28|1@0+ (1,0) [0|1] ""  CEM
 SG_ MirrAtDrvrInMovmt : 27|1@0+ (1,0) [0|1] ""  CEM
 SG_ MirrAtDrvrInMovmt_UB : 47|1@0+ (1,0) [0|1] ""  CEM
 SG_ MirrBtnPsdAtDrvr : 26|1@0+ (1,0) [0|1] ""  CEM
 SG_ MirrBtnPsdAtDrvr_UB : 46|1@0+ (1,0) [0|1] ""  CEM
 SG_ MirrCmdAtPassAdj : 39|3@0+ (1,0) [0|7] ""  PDM
 SG_ MirrCmdAtPassDwn : 36|2@0+ (1,0) [0|3] ""  PDM
 SG_ MirrCmdAtPassFold : 34|2@0+ (1,0) [0|3] ""  PDM
 SG_ MirrCmdAtPassGroup_UB : 32|1@0+ (1,0) [0|1] ""  PDM
 SG_ MirrFoldStsAtDrvr : 55|3@0+ (1,0) [0|7] ""  CEM
 SG_ MirrFoldStsAtDrvr_UB : 25|1@0+ (1,0) [0|1] ""  CEM
 SG_ WinPosnStsAtDrvrRe : 63|5@0+ (1,0) [0|31] ""  CCM,CEM,VCM
 SG_ WinPosnStsAtDrvrRe_UB : 1|1@0+ (1,0) [0|1] ""  CCM,CEM,VCM
 SG_ WinSwtReqToPass : 58|3@0+ (1,0) [0|7] ""  PDM
 SG_ WinSwtReqToPass_UB : 30|1@0+ (1,0) [0|1] ""  PDM
 SG_ WinSwtReqToPassRe : 52|3@0+ (1,0) [0|7] ""  PDM
 SG_ WinSwtReqToPassRe_UB : 24|1@0+ (1,0) [0|1] ""  PDM

BO_ 480 DDMBodyFr02: 8 DDM
 SG_ ActvnOfDoorSwtIllmn : 16|1@0+ (1,0) [0|1] ""  PDM
 SG_ ActvnOfDoorSwtIllmn_UB : 35|1@0+ (1,0) [0|1] ""  PDM
 SG_ AmbTQlyAtDrvrSide : 12|2@0+ (1,0) [0|3] ""  CEM
 SG_ AmbTRawAtDrvrSide_UB : 10|1@0+ (1,0) [0|1] ""  CEM
 SG_ AmbTValAtDrvrSide : 7|11@0+ (0.1,-70) [-70|134.7] "degC"  CEM
 SG_ ChdWinProtnStsAtDrvrRe : 37|1@0+ (1,0) [0|1] ""  CEM
 SG_ ChdWinProtnStsAtDrvrRe_UB : 36|1@0+ (1,0) [0|1] ""  CEM
 SG_ CrashUnlckFailrStsAtDrvr : 31|2@0+ (1,0) [0|3] ""  CEM
 SG_ CrashUnlckFailrStsAtDrvr_UB : 17|1@0+ (1,0) [0|1] ""  CEM
 SG_ FltOfPuddleLiDrvr : 9|1@0+ (1,0) [0|1] ""  CEM
 SG_ FltOfPuddleLiDrvr_UB : 8|1@0+ (1,0) [0|1] ""  CEM
 SG_ LiDrvrFltIndcrTurn : 20|1@0+ (1,0) [0|1] ""  CEM
 SG_ LiDrvrFltIndcrTurn_UB : 19|1@0+ (1,0) [0|1] ""  CEM
 SG_ MirrDefrstAtDrvSts : 39|1@0+ (1,0) [0|1] ""  CEM
 SG_ MirrDefrstAtDrvSts_UB : 38|1@0+ (1,0) [0|1] ""  CEM
 SG_ MirrDwnStsAtDrvr : 23|3@0+ (1,0) [0|7] ""  CEM
 SG_ MirrDwnStsAtDrvr_UB : 18|1@0+ (1,0) [0|1] ""  CEM
 SG_ WinPosnStsDrv : 28|5@0+ (1,0) [0|31] ""  CCM,CEM,VCM
 SG_ WinPosnStsDrv_UB : 29|1@0+ (1,0) [0|1] ""  CCM,CEM,VCM

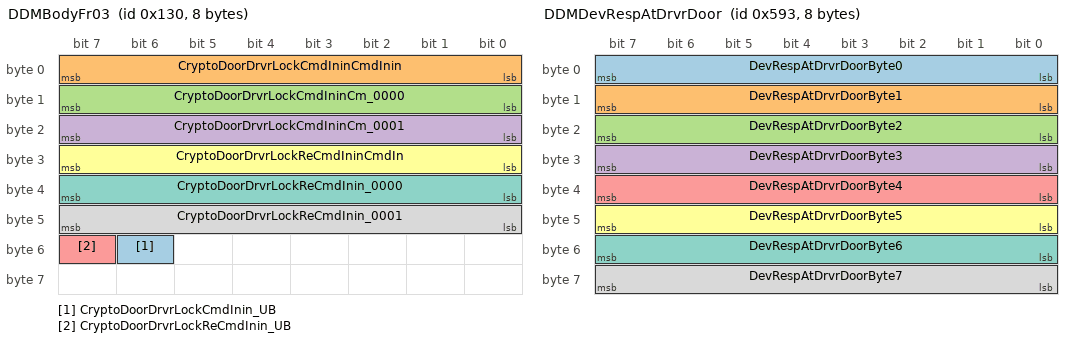
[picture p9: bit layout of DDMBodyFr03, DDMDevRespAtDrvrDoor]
BO_ 304 DDMBodyFr03: 8 DDM
 SG_ CryptoDoorDrvrLockCmdInin_UB : 54|1@0+ (1,0) [0|1] ""  CEM
 SG_ CryptoDoorDrvrLockCmdIninCmdInin : 7|8@0+ (1,0) [0|255] ""  CEM
 SG_ CryptoDoorDrvrLockCmdIninCm_0000 : 15|8@0+ (1,0) [0|255] ""  CEM
 SG_ CryptoDoorDrvrLockCmdIninCm_0001 : 23|8@0+ (1,0) [0|255] ""  CEM
 SG_ CryptoDoorDrvrLockReCmdInin_UB : 55|1@0+ (1,0) [0|1] ""  CEM
 SG_ CryptoDoorDrvrLockReCmdIninCmdIn : 31|8@0+ (1,0) [0|255] ""  CEM
 SG_ CryptoDoorDrvrLockReCmdInin_0000 : 39|8@0+ (1,0) [0|255] ""  CEM
 SG_ CryptoDoorDrvrLockReCmdInin_0001 : 47|8@0+ (1,0) [0|255] ""  CEM

BO_ 1283 DdmBodyNMFr: 8 DDM
 SG_ PNC23_Spare1_DDM : 39|1@0+ (1,0) [0|0] ""  ETC
 SG_ PNC22_Spare2_DDM : 38|1@0+ (1,0) [0|0] ""  ETC
 SG_ PNC21_Spare3_DDM : 37|1@0+ (1,0) [0|0] ""  ETC
 SG_ PNC20_Spare4_DDM : 36|1@0+ (1,0) [0|0] ""  ETC
 SG_ PNC19_Spare5_DDM : 35|1@0+ (1,0) [0|0] ""  ETC
 SG_ PNC18_Spare6_DDM : 34|1@0+ (1,0) [0|0] ""  ETC
 SG_ PNC17_Spare7_DDM : 33|1@0+ (1,0) [0|0] ""  ETC
 SG_ PNC16_Diesel_DDM : 32|1@0+ (1,0) [0|0] ""  ETC
 SG_ PNC15_DriverInfoPoll_DDM : 31|1@0+ (1,0) [0|0] ""  ETC
 SG_ PNC14_GSD_DDM : 30|1@0+ (1,0) [0|0] ""  ETC
 SG_ PNC13_Global_DDM : 29|1@0+ (1,0) [0|0] ""  ETC
 SG_ PNC12_TrailerCaravan_DDM : 28|1@0+ (1,0) [0|0] ""  ETC
 SG_ PNC11_Driving_DDM : 27|1@0+ (1,0) [0|0] ""  ETC
 SG_ PNC10_PreClimatization_DDM : 26|1@0+ (1,0) [0|0] ""  ETC
 SG_ PNC9_Charging_DDM : 25|1@0+ (1,0) [0|0] ""  ETC
 SG_ PNC8_Start_DDM : 24|1@0+ (1,0) [0|0] ""  ETC
 SG_ PNC7_Entrance_DDM : 23|1@0+ (1,0) [0|0] ""  ETC
 SG_ PNC6_InfotainmentHMI_DDM : 22|1@0+ (1,0) [0|0] ""  ETC
 SG_ PNC5_Body_DDM : 21|1@0+ (1,0) [0|0] ""  ETC
 SG_ PNC4_Visibility_DDM : 20|1@0+ (1,0) [0|0] ""  ETC
 SG_ PNC3_WarningSounds_DDM : 19|1@0+ (1,0) [0|0] ""  ETC
 SG_ PNC2_Hazard_DDM : 18|1@0+ (1,0) [0|0] ""  ETC
 SG_ PNC1_Locking_DDM : 17|1@0+ (1,0) [0|0] ""  ETC
 SG_ PNC0_DriverInfo_DDM : 16|1@0+ (1,0) [0|0] ""  ETC
 SG_ NM_AW_DDM : 12|1@0+ (1,0) [0|0] ""  ETC
 SG_ NM_CS_DDM : 11|1@0+ (1,0) [0|0] ""  ETC
 SG_ NM_RMR_DDM : 8|1@0+ (1,0) [0|0] ""  ETC
 SG_ NM_PNI_DDM : 14|1@0+ (1,0) [0|0] ""  ETC
 SG_ NM_NodeID_DDM : 7|8@0+ (1,0) [0|0] ""  ETC

BO_ 1427 DDMDevRespAtDrvrDoor: 8 DDM
 SG_ DevRespAtDrvrDoorByte0 : 7|8@0+ (1,0) [0|255] ""  ETC
 SG_ DevRespAtDrvrDoorByte1 : 15|8@0+ (1,0) [0|255] ""  ETC
 SG_ DevRespAtDrvrDoorByte2 : 23|8@0+ (1,0) [0|255] ""  ETC
 SG_ DevRespAtDrvrDoorByte3 : 31|8@0+ (1,0) [0|255] ""  ETC
 SG_ DevRespAtDrvrDoorByte4 : 39|8@0+ (1,0) [0|255] ""  ETC
 SG_ DevRespAtDrvrDoorByte5 : 47|8@0+ (1,0) [0|255] ""  ETC
 SG_ DevRespAtDrvrDoorByte6 : 55|8@0+ (1,0) [0|255] ""  ETC
 SG_ DevRespAtDrvrDoorByte7 : 63|8@0+ (1,0) [0|255] ""  ETC

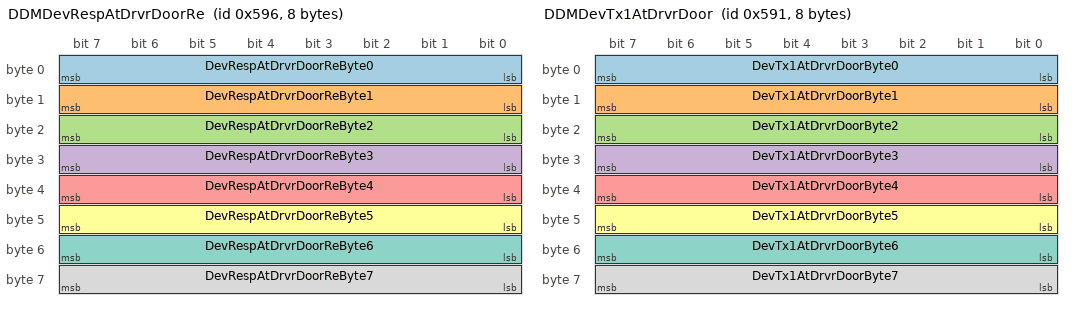
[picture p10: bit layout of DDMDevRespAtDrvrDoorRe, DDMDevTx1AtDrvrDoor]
BO_ 1430 DDMDevRespAtDrvrDoorRe: 8 DDM
 SG_ DevRespAtDrvrDoorReByte0 : 7|8@0+ (1,0) [0|255] ""  ETC
 SG_ DevRespAtDrvrDoorReByte1 : 15|8@0+ (1,0) [0|255] ""  ETC
 SG_ DevRespAtDrvrDoorReByte2 : 23|8@0+ (1,0) [0|255] ""  ETC
 SG_ DevRespAtDrvrDoorReByte3 : 31|8@0+ (1,0) [0|255] ""  ETC
 SG_ DevRespAtDrvrDoorReByte4 : 39|8@0+ (1,0) [0|255] ""  ETC
 SG_ DevRespAtDrvrDoorReByte5 : 47|8@0+ (1,0) [0|255] ""  ETC
 SG_ DevRespAtDrvrDoorReByte6 : 55|8@0+ (1,0) [0|255] ""  ETC
 SG_ DevRespAtDrvrDoorReByte7 : 63|8@0+ (1,0) [0|255] ""  ETC

BO_ 1425 DDMDevTx1AtDrvrDoor: 8 DDM
 SG_ DevTx1AtDrvrDoorByte0 : 7|8@0+ (1,0) [0|255] ""  ETC
 SG_ DevTx1AtDrvrDoorByte1 : 15|8@0+ (1,0) [0|255] ""  ETC
 SG_ DevTx1AtDrvrDoorByte2 : 23|8@0+ (1,0) [0|255] ""  ETC
 SG_ DevTx1AtDrvrDoorByte3 : 31|8@0+ (1,0) [0|255] ""  ETC
 SG_ DevTx1AtDrvrDoorByte4 : 39|8@0+ (1,0) [0|255] ""  ETC
 SG_ DevTx1AtDrvrDoorByte5 : 47|8@0+ (1,0) [0|255] ""  ETC
 SG_ DevTx1AtDrvrDoorByte6 : 55|8@0+ (1,0) [0|255] ""  ETC
 SG_ DevTx1AtDrvrDoorByte7 : 63|8@0+ (1,0) [0|255] ""  ETC

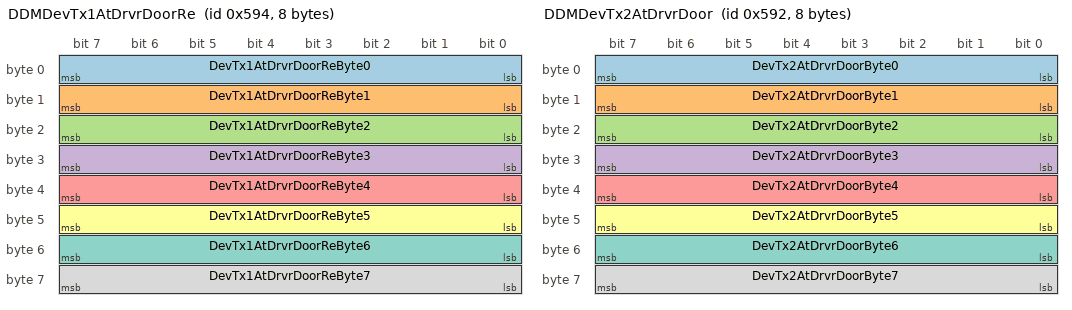
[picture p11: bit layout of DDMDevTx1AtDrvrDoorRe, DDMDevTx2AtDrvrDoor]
BO_ 1428 DDMDevTx1AtDrvrDoorRe: 8 DDM
 SG_ DevTx1AtDrvrDoorReByte0 : 7|8@0+ (1,0) [0|255] ""  ETC
 SG_ DevTx1AtDrvrDoorReByte1 : 15|8@0+ (1,0) [0|255] ""  ETC
 SG_ DevTx1AtDrvrDoorReByte2 : 23|8@0+ (1,0) [0|255] ""  ETC
 SG_ DevTx1AtDrvrDoorReByte3 : 31|8@0+ (1,0) [0|255] ""  ETC
 SG_ DevTx1AtDrvrDoorReByte4 : 39|8@0+ (1,0) [0|255] ""  ETC
 SG_ DevTx1AtDrvrDoorReByte5 : 47|8@0+ (1,0) [0|255] ""  ETC
 SG_ DevTx1AtDrvrDoorReByte6 : 55|8@0+ (1,0) [0|255] ""  ETC
 SG_ DevTx1AtDrvrDoorReByte7 : 63|8@0+ (1,0) [0|255] ""  ETC

BO_ 1426 DDMDevTx2AtDrvrDoor: 8 DDM
 SG_ DevTx2AtDrvrDoorByte0 : 7|8@0+ (1,0) [0|255] ""  ETC
 SG_ DevTx2AtDrvrDoorByte1 : 15|8@0+ (1,0) [0|255] ""  ETC
 SG_ DevTx2AtDrvrDoorByte2 : 23|8@0+ (1,0) [0|255] ""  ETC
 SG_ DevTx2AtDrvrDoorByte3 : 31|8@0+ (1,0) [0|255] ""  ETC
 SG_ DevTx2AtDrvrDoorByte4 : 39|8@0+ (1,0) [0|255] ""  ETC
 SG_ DevTx2AtDrvrDoorByte5 : 47|8@0+ (1,0) [0|255] ""  ETC
 SG_ DevTx2AtDrvrDoorByte6 : 55|8@0+ (1,0) [0|255] ""  ETC
 SG_ DevTx2AtDrvrDoorByte7 : 63|8@0+ (1,0) [0|255] ""  ETC

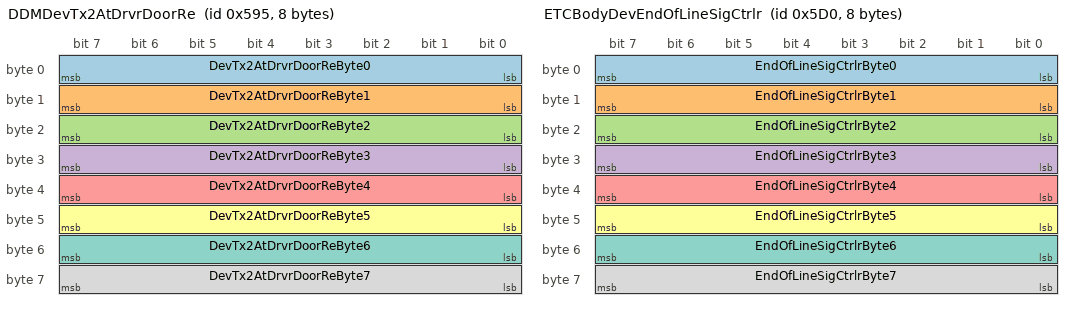
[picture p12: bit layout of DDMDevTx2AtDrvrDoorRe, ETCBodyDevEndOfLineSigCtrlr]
BO_ 1429 DDMDevTx2AtDrvrDoorRe: 8 DDM
 SG_ DevTx2AtDrvrDoorReByte0 : 7|8@0+ (1,0) [0|255] ""  ETC
 SG_ DevTx2AtDrvrDoorReByte1 : 15|8@0+ (1,0) [0|255] ""  ETC
 SG_ DevTx2AtDrvrDoorReByte2 : 23|8@0+ (1,0) [0|255] ""  ETC
 SG_ DevTx2AtDrvrDoorReByte3 : 31|8@0+ (1,0) [0|255] ""  ETC
 SG_ DevTx2AtDrvrDoorReByte4 : 39|8@0+ (1,0) [0|255] ""  ETC
 SG_ DevTx2AtDrvrDoorReByte5 : 47|8@0+ (1,0) [0|255] ""  ETC
 SG_ DevTx2AtDrvrDoorReByte6 : 55|8@0+ (1,0) [0|255] ""  ETC
 SG_ DevTx2AtDrvrDoorReByte7 : 63|8@0+ (1,0) [0|255] ""  ETC

BO_ 1554 DdmToCemBodyDiagResFrame: 8 DDM

BO_ 1417 DDMtoETCXCPFr01: 8 DDM

BO_ 1488 ETCBodyDevEndOfLineSigCtrlr: 8 ETC
 SG_ EndOfLineSigCtrlrByte0 : 7|8@0+ (1,0) [0|255] ""  CEM
 SG_ EndOfLineSigCtrlrByte1 : 15|8@0+ (1,0) [0|255] ""  CEM
 SG_ EndOfLineSigCtrlrByte2 : 23|8@0+ (1,0) [0|255] ""  CEM
 SG_ EndOfLineSigCtrlrByte3 : 31|8@0+ (1,0) [0|255] ""  CEM
 SG_ EndOfLineSigCtrlrByte4 : 39|8@0+ (1,0) [0|255] ""  CEM
 SG_ EndOfLineSigCtrlrByte5 : 47|8@0+ (1,0) [0|255] ""  CEM
 SG_ EndOfLineSigCtrlrByte6 : 55|8@0+ (1,0) [0|255] ""  CEM
 SG_ EndOfLineSigCtrlrByte7 : 63|8@0+ (1,0) [0|255] ""  CEM

BO_ 1489 ETCBodyDevEndOfLineSigCtrlrInp: 8 ETC
 SG_ EndOfLineSigCtrlrInp : 7|32@0+ (1,0) [0|4294967295] ""  CCM
 SG_ EndOfLineSigCtrlrInp1 : 39|32@0+ (1,0) [0|4294967295] ""  CCM

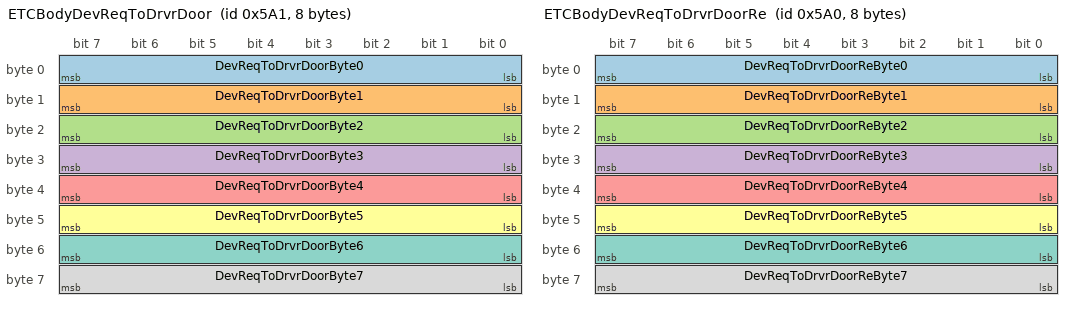
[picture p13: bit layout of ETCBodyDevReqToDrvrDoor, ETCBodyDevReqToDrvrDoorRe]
BO_ 1441 ETCBodyDevReqToDrvrDoor: 8 ETC
 SG_ DevReqToDrvrDoorByte0 : 7|8@0+ (1,0) [0|255] ""  DDM
 SG_ DevReqToDrvrDoorByte1 : 15|8@0+ (1,0) [0|255] ""  DDM
 SG_ DevReqToDrvrDoorByte2 : 23|8@0+ (1,0) [0|255] ""  DDM
 SG_ DevReqToDrvrDoorByte3 : 31|8@0+ (1,0) [0|255] ""  DDM
 SG_ DevReqToDrvrDoorByte4 : 39|8@0+ (1,0) [0|255] ""  DDM
 SG_ DevReqToDrvrDoorByte5 : 47|8@0+ (1,0) [0|255] ""  DDM
 SG_ DevReqToDrvrDoorByte6 : 55|8@0+ (1,0) [0|255] ""  DDM
 SG_ DevReqToDrvrDoorByte7 : 63|8@0+ (1,0) [0|255] ""  DDM

BO_ 1440 ETCBodyDevReqToDrvrDoorRe: 8 ETC
 SG_ DevReqToDrvrDoorReByte0 : 7|8@0+ (1,0) [0|255] ""  DDM
 SG_ DevReqToDrvrDoorReByte1 : 15|8@0+ (1,0) [0|255] ""  DDM
 SG_ DevReqToDrvrDoorReByte2 : 23|8@0+ (1,0) [0|255] ""  DDM
 SG_ DevReqToDrvrDoorReByte3 : 31|8@0+ (1,0) [0|255] ""  DDM
 SG_ DevReqToDrvrDoorReByte4 : 39|8@0+ (1,0) [0|255] ""  DDM
 SG_ DevReqToDrvrDoorReByte5 : 47|8@0+ (1,0) [0|255] ""  DDM
 SG_ DevReqToDrvrDoorReByte6 : 55|8@0+ (1,0) [0|255] ""  DDM
 SG_ DevReqToDrvrDoorReByte7 : 63|8@0+ (1,0) [0|255] ""  DDM

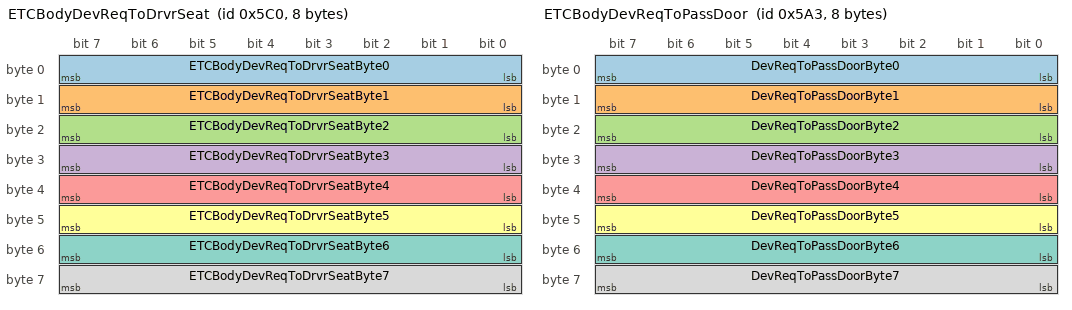
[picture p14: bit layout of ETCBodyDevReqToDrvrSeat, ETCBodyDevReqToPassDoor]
BO_ 1472 ETCBodyDevReqToDrvrSeat: 8 ETC
 SG_ ETCBodyDevReqToDrvrSeatByte0 : 7|8@0+ (1,0) [0|255] ""  PSMD
 SG_ ETCBodyDevReqToDrvrSeatByte1 : 15|8@0+ (1,0) [0|255] ""  PSMD
 SG_ ETCBodyDevReqToDrvrSeatByte2 : 23|8@0+ (1,0) [0|255] ""  PSMD
 SG_ ETCBodyDevReqToDrvrSeatByte3 : 31|8@0+ (1,0) [0|255] ""  PSMD
 SG_ ETCBodyDevReqToDrvrSeatByte4 : 39|8@0+ (1,0) [0|255] ""  PSMD
 SG_ ETCBodyDevReqToDrvrSeatByte5 : 47|8@0+ (1,0) [0|255] ""  PSMD
 SG_ ETCBodyDevReqToDrvrSeatByte6 : 55|8@0+ (1,0) [0|255] ""  PSMD
 SG_ ETCBodyDevReqToDrvrSeatByte7 : 63|8@0+ (1,0) [0|255] ""  PSMD

BO_ 1443 ETCBodyDevReqToPassDoor: 8 ETC
 SG_ DevReqToPassDoorByte0 : 7|8@0+ (1,0) [0|255] ""  PDM
 SG_ DevReqToPassDoorByte1 : 15|8@0+ (1,0) [0|255] ""  PDM
 SG_ DevReqToPassDoorByte2 : 23|8@0+ (1,0) [0|255] ""  PDM
 SG_ DevReqToPassDoorByte3 : 31|8@0+ (1,0) [0|255] ""  PDM
 SG_ DevReqToPassDoorByte4 : 39|8@0+ (1,0) [0|255] ""  PDM
 SG_ DevReqToPassDoorByte5 : 47|8@0+ (1,0) [0|255] ""  PDM
 SG_ DevReqToPassDoorByte6 : 55|8@0+ (1,0) [0|255] ""  PDM
 SG_ DevReqToPassDoorByte7 : 63|8@0+ (1,0) [0|255] ""  PDM

CM_ SG_ 528 ActvnOfDoorLiGroup_UB "Update bit for signal group ActvnOfDoorLiGroup; ActvnOfDoorLiGroupActvnOfDoorAmbLi ActvnOfDoorLiGroupActvnOfHndlAndStorgLi ActvnOfDoorLiGroupAmbLiInten ActvnOfDoorLiGroupAmbLiRedn ";
CM_ SG_ 528 ActvnOfDoorLiGroupActvnOfDoorAmb "Contains signals sent from CEM to DCUs to control the door lighting.";
CM_ SG_ 528 ActvnOfDoorLiGroupActvnOfHndlAnd "Contains signals sent from CEM to DCUs to control the door lighting.";
CM_ SG_ 528 ActvnOfDoorLiGroupAmbLiInten "Contains signals sent from CEM to DCUs to control the door lighting.";
CM_ SG_ 528 ActvnOfDoorLiGroupAmbLiRedn "Contains signals sent from CEM to DCUs to control the door lighting.";
CM_ SG_ 528 ChrgrSt "The state of the charger. ";
CM_ SG_ 528 ChrgrSt_UB "Update bit for signal ChrgrSt";
CM_ SG_ 528 DrvrSeatDispSpplFct "Handles the two way communication for driver multi seat control.
";
CM_ SG_ 528 DrvrSeatDispSpplFct_UB "Update bit for signal DrvrSeatDispSpplFct";
CM_ SG_ 528 DstToEmpty "Indicated distance to Empty (D.T.E.) with indicated unit Distance To Empty";
CM_ SG_ 528 DstToEmptyIndcd_UB "Update bit for signal group DstToEmptyIndcd; DstToEmpty DstUnit ";
CM_ SG_ 528 DstUnit "Indicated distance to Empty (D.T.E.) with indicated unit Indicated distance to empty unit";
CM_ SG_ 528 EngCooltInhbFlow "Inhibitation of non-crucial coolant flow requests. Sent out to inform that the eninge is in heat up phase and that all additional coolant flow will postphone the time when the engine has reached normal operating temperature.";
CM_ SG_ 528 EngCooltInhbFlow_UB "Update bit for signal EngCooltInhbFlow";
CM_ SG_ 528 EngOilPWarn "Request to set low engine oil pressure warning to driver";
CM_ SG_ 528 EngOilPWarn_UB "Update bit for signal EngOilPWarn";
CM_ SG_ 528 EngT "Engine coolant temperature signal group. Includes:
- Engine coolant temperature. Resolution 1 degC.
- Engine coolant temperature quality factor. Engine coolant temperature";
CM_ SG_ 528 EngTGrp_UB "Update bit for signal group EngTGrp; EngT EngTQf ";
CM_ SG_ 528 EngTQf "Engine coolant temperature signal group. Includes:
- Engine coolant temperature. Resolution 1 degC.
- Engine coolant temperature quality factor. Engine coolant temperature Qf flag";
CM_ SG_ 528 HvBattHeatgReq_UB "Update bit for signal HvBattHeatgReq";
CM_ SG_ 528 HvBattHeatrVlvPosn_UB "Update bit for signal HvBattHeatrVlvPosn";
CM_ SG_ 528 HvPwrEgyPrio "Information about which session is prioritized (charging, cooling, climatization etc).";
CM_ SG_ 528 HvPwrEgyPrio_UB "Update bit for signal HvPwrEgyPrio";
CM_ SG_ 528 OnBdChrgrHndlSts "Status of the Onboard Charger connection to the grid. ";
CM_ SG_ 528 OnBdChrgrHndlSts_UB "Update bit for signal OnBdChrgrHndlSts";
CM_ SG_ 528 PassSeatSts "Occupation status of the front passenger seat.";
CM_ SG_ 528 PassSeatSts_UB "Update bit for signal PassSeatSts";
CM_ SG_ 528 SeatDispBtnPsd_UB "Update bit for signal group SeatDispBtnPsd; SeatDispBtnPsdDrvrSeatDispBtnPsd SeatDispBtnPsdPassSeatDispBtnPsd ";
CM_ SG_ 528 SeatDispBtnPsdDrvrSeatDispBtnPsd "Distribution of when the multi function menue is accesed on the IHU.
 Indicate usage of CSD buttons for Driver Seat Multifunction";
CM_ SG_ 528 SeatDispBtnPsdPassSeatDispBtnPsd "Distribution of when the multi function menue is accesed on the IHU.
 Indicate usage of CSD buttons for Passenger Seat Multifunction";
CM_ SG_ 528 SteerWhlHeatgDurgClimaEnad "Enable signal for steering wheel heating during pre-conditioning.";
CM_ SG_ 528 SteerWhlHeatgDurgClimaEnad_UB "Update bit for signal SteerWhlHeatgDurgClimaEnad";
CM_ SG_ 544 UkwnCptReqToTelmByte0 "Encryption request to FCD slave ECU. Scrambled and indiscernable outside ECU. Byte0";
CM_ SG_ 544 UkwnCptReqToTelmByte1 "Encryption request to FCD slave ECU. Scrambled and indiscernable outside ECU. Byte1";
CM_ SG_ 544 UkwnCptReqToTelmByte2 "Encryption request to FCD slave ECU. Scrambled and indiscernable outside ECU. Byte2";
CM_ SG_ 544 UkwnCptReqToTelmByte3 "Encryption request to FCD slave ECU. Scrambled and indiscernable outside ECU. Byte3";
CM_ SG_ 544 UkwnCptReqToTelmByte4 "Encryption request to FCD slave ECU. Scrambled and indiscernable outside ECU. Byte4";
CM_ SG_ 544 UkwnCptReqToTelmByte5 "Encryption request to FCD slave ECU. Scrambled and indiscernable outside ECU. Byte5";
CM_ SG_ 544 UkwnCptReqToTelmByte6 "Encryption request to FCD slave ECU. Scrambled and indiscernable outside ECU. Byte6";
CM_ SG_ 544 UkwnCptReqToTelmByte7 "Encryption request to FCD slave ECU. Scrambled and indiscernable outside ECU. Byte7";
CM_ SG_ 608 ClimaTmrStsRqrd "request to wake up at time sent in 'ClimaTmr'-signal.";
CM_ SG_ 608 ClimaTmrStsRqrd_UB "Update bit for signal ClimaTmrStsRqrd";
CM_ SG_ 608 DayToSrv "Days left before service shall be done";
CM_ SG_ 608 DayToSrv_UB "Update bit for signal DayToSrv";
CM_ SG_ 608 DstTrvld1 "Value of the indicated Trip meter 1.";
CM_ SG_ 608 DstTrvld1_UB "Update bit for signal DstTrvld1";
CM_ SG_ 608 EgySave "Energy save selected by user during Drive Mode individual";
CM_ SG_ 608 EgySave_UB "Update bit for signal EgySave";
CM_ SG_ 608 FuCnsIndcd_UB "Update bit for signal group FuCnsIndcd; FuCnsIndcdUnit FuCnsIndcdVal ";
CM_ SG_ 608 FuCnsIndcdUnit "Instantaneous Fuel Consumption (IFC) with indicated unit IFC unit";
CM_ SG_ 608 FuCnsIndcdVal "Instantaneous Fuel Consumption (IFC) with indicated unit IFC value";
CM_ SG_ 608 FuLvlLoIndcn "Signal that indicated if the yellow low fuel tell tale is lit";
CM_ SG_ 608 FuLvlLoIndcn_UB "Update bit for signal FuLvlLoIndcn";
CM_ SG_ 608 MassgFctActv_UB "Update bit for signal group MassgFctActv; MassgFctActvDrvrMassgFctActv MassgFctActvPassMassgFctActv ";
CM_ SG_ 608 MassgFctActvDrvrMassgFctActv "Distributing that the massage menu view is activated.
 Indicate driver massage menu active";
CM_ SG_ 608 MassgFctActvPassMassgFctActv "Distributing that the massage menu view is activated.
 Indicate Passenger massage menu active";
CM_ SG_ 608 SeatHeatDurgClimaEnad "Signal for deciding wether seatclimatisation shall be enabled during pre-conditioning (in hybrids).";
CM_ SG_ 608 SeatHeatDurgClimaEnad_UB "Update bit for signal SeatHeatDurgClimaEnad";
CM_ SG_ 608 SrvTrig "Information that a service reminder message is shown in the instrument cluster. Gives information of which parameter that trigged the message and which service reminder message that is shown.";
CM_ SG_ 608 SrvTrig_UB "Update bit for signal SrvTrig";
CM_ SG_ 640 ClimaTmr "Time that the car shall be finished with pre-condition.";
CM_ SG_ 640 ClimaTmr_UB "Update bit for signal ClimaTmr";
CM_ SG_ 640 EngHrToSrv "Engine hours left before a service shall be done";
CM_ SG_ 640 EngHrToSrv_UB "Update bit for signal EngHrToSrv";
CM_ SG_ 640 FuCnsAvg "Average Fuel Consumption (AFC) with indicated unit
There are two versions of the trip computer function AFC, where version 1 is a mean value that can be resetted by the driver and version 2 is a mean value which is automatically resetted by the system if the vehicle hasn't been used for 4 h (or more).
So the data container signal (FuCnsAvgIndcd.FuCnsAvg) will flip it's MSB to be able to send both version 1 and version 2 of the data. So when bit 12 = 0 then AFC value for version 1 is transmitted and when bit 12 = 1 then AFC value for version 2 is transmitted. IFC value";
CM_ SG_ 640 FuCnsAvgIndcd_UB "Update bit for signal group FuCnsAvgIndcd; FuCnsAvg FuCnsAvgUnit ";
CM_ SG_ 640 FuCnsAvgUnit "Average Fuel Consumption (AFC) with indicated unit
There are two versions of the trip computer function AFC, where version 1 is a mean value that can be resetted by the driver and version 2 is a mean value which is automatically resetted by the system if the vehicle hasn't been used for 4 h (or more).
So the data container signal (FuCnsAvgIndcd.FuCnsAvg) will flip it's MSB to be able to send both version 1 and version 2 of the data. So when bit 12 = 0 then AFC value for version 1 is transmitted and when bit 12 = 1 then AFC value for version 2 is transmitted. IFC unit";
CM_ SG_ 592 CoolgReqForDispCen "Distribution of forced cooling request of center display components to Climate  ";
CM_ SG_ 592 CoolgReqForDispCen_UB "Update bit for signal CoolgReqForDispCen";
CM_ SG_ 592 CoolgReqForDrvrDisp_UB "Update bit for signal CoolgReqForDrvrDisp";
CM_ SG_ 592 DstToSrv "Distance (km) left before service shall be done";
CM_ SG_ 592 DstToSrv_UB "Update bit for signal DstToSrv";
CM_ SG_ 592 EngFuCnsFild "The econometer data signal for used for driver display have the following requirement for Econometer equalization: 

Deviations from normal data (at e.g. regeneration) shall be taken care of by the ECM (Engine Control Module) fuel consumption algorithm.

Extra fuel consumption during these events shall be stored locally in the ECM, to be transmitted as a distributed small added extra consumption data. This extra value shall be so designed such that there is no to the customer visible significant jumps in the transmitted ECON signal (that is related to the extra fuel consumed during the specific event). The total transmitted fuel consumption as indicated by the ECON signal, shall over time equal true consumption.
";
CM_ SG_ 592 EngFuCnsFild_UB "Update bit for signal EngFuCnsFild";
CM_ SG_ 592 FuLvlLoWarn "Signal that indicated if the RED low fuel warning LED is lit";
CM_ SG_ 592 FuLvlLoWarn_UB "Update bit for signal FuLvlLoWarn";
CM_ SG_ 592 VehSpdAvg "Indicated Average Speed (trip computer function AVS) with current unit.
There are two versions of the trip computer function AFS, where version 1 is a mean value that can be resetted by the driver and version 2 is a mean value which is automatically resetted by the system if the vehicle hasn't been used for less then 4 h.
So the data container signal (VehSpdAvgIndcd.VehSpdAvg) will flip it's MSB to be able to send both version 1 and version 2 of the data. So when bit 8 = 0 then AFS value for version 1 is transmitted and when bit 8 = 1 then AFS value for version 2 is transmitted. Vehicle speed";
CM_ SG_ 592 VehSpdAvgIndcd_UB "Update bit for signal group VehSpdAvgIndcd; VehSpdAvg VehSpdAvgUnit ";
CM_ SG_ 592 VehSpdAvgUnit "Indicated Average Speed (trip computer function AVS) with current unit.
There are two versions of the trip computer function AFS, where version 1 is a mean value that can be resetted by the driver and version 2 is a mean value which is automatically resetted by the system if the vehicle hasn't been used for less then 4 h.
So the data container signal (VehSpdAvgIndcd.VehSpdAvg) will flip it's MSB to be able to send both version 1 and version 2 of the data. So when bit 8 = 0 then AFS value for version 1 is transmitted and when bit 8 = 1 then AFS value for version 2 is transmitted. Unit for vehicle speed";
CM_ SG_ 592 VehSpdIndcdQly "Indicated vehicle speed QF info.";
CM_ SG_ 592 VehSpdIndcdQly_UB "Update bit for signal VehSpdIndcdQly";
CM_ SG_ 656 DstTrvld2 "Value of the indicated Trip meter 2.";
CM_ SG_ 656 DstTrvld2_UB "Update bit for signal DstTrvld2";
CM_ SG_ 656 DstTrvldHiResl "High resolution trip meter value, resolution of 1m with a modulus 256 counter (counts 0 -> 255 -> 0 etc).";
CM_ SG_ 656 DstTrvldHiResl_UB "Update bit for signal DstTrvldHiResl";
CM_ SG_ 656 EngFuCns "The transmitted econometer data for used for calculations in DIM shall be unfiltered and without any offset. Thus, this econometer data shall be as close to the true current fuel consumption by engine as possible, at all times.
";
CM_ SG_ 656 EngFuCns_UB "Update bit for signal EngFuCns";
CM_ SG_ 656 SunRoofPosnSts "The position of the sun roof panel";
CM_ SG_ 656 SunRoofPosnSts_UB "Update bit for signal SunRoofPosnSts";
CM_ SG_ 624 AbsWarnIndcnReq "Request for warning indication to driver in case of brake failure (red warning) or ABS failure (yellow warning) ABS warning indication request";
CM_ SG_ 624 BrkAndAbsWarnIndcnReqChks "Request for warning indication to driver in case of brake failure (red warning) or ABS failure (yellow warning) Checksum for Brake and ABS warning indication request";
CM_ SG_ 624 BrkAndAbsWarnIndcnReqCntr "Request for warning indication to driver in case of brake failure (red warning) or ABS failure (yellow warning) Counter for Brake and ABS warning indication request";
CM_ SG_ 624 BrkAndAbsWarnIndcnReqGroup_UB "Update bit for signal group BrkAndAbsWarnIndcnReqGroup; AbsWarnIndcnReq BrkAndAbsWarnIndcnReqChks BrkAndAbsWarnIndcnReqCntr BrkWarnIndcnReq ";
CM_ SG_ 624 BrkWarnIndcnReq "Request for warning indication to driver in case of brake failure (red warning) or ABS failure (yellow warning) Brake warning indication request";
CM_ SG_ 624 EngSt1WdSts "Signaling the state of the powerpack.";
CM_ SG_ 624 EngSt1WdSts_UB "Update bit for signal EngSt1WdSts";
CM_ SG_ 624 FuLvlIndcd_UB "Update bit for signal group FuLvlIndcd; FuLvlIndcdQly FuLvlIndcdVal ";
CM_ SG_ 624 FuLvlIndcdQly "Indicated fuel level in Liter, the value is damped and can differ from the real raw fuel level values. Quality Flag";
CM_ SG_ 624 FuLvlIndcdVal "Indicated fuel level in Liter, the value is damped and can differ from the real raw fuel level values. Fuel level value converted from fuel table";
CM_ SG_ 624 NetHdActvt_UB "Update bit for signal group NetHdActvt; NetHdActvtPrio NetHdActvtResourceGroup ";
CM_ SG_ 624 NetHdActvtPrio "Network Head Activate:
Wakeup signal from the Inftotainment HEAD Unit (IHU), with the purpose of waking up other infotainment nodes when a function on that node is requested.
Bit 1: Prio high/normal
Bit 2-5: Requested function number (Function no 0-15) Prority of resource request";
CM_ SG_ 624 NetHdActvtResourceGroup "Network Head Activate:
Wakeup signal from the Inftotainment HEAD Unit (IHU), with the purpose of waking up other infotainment nodes when a function on that node is requested.
Bit 1: Prio high/normal
Bit 2-5: Requested function number (Function no 0-15) Resource group member";
CM_ SG_ 624 NotifForEmgyCall "Binary information if there is a need for the vehicle to perform an emergency call.";
CM_ SG_ 624 NotifForEmgyCall_UB "Update bit for signal NotifForEmgyCall";
CM_ SG_ 624 PassSeatDispSpplFct "Handles the two way communication for passenger multi seat control.
";
CM_ SG_ 624 PassSeatDispSpplFct_UB "Update bit for signal PassSeatDispSpplFct";
CM_ SG_ 624 SteerWhlHeatgOnReq "Request to start the steering wheel heating at a certain heat level";
CM_ SG_ 624 SteerWhlHeatgOnReq_UB "Update bit for signal SteerWhlHeatgOnReq";
CM_ SG_ 768 DrvModReq "Distributes the desired Drive Mode chosen by the user to all nodes which determine the charactaristics of the vehicle
";
CM_ SG_ 768 DrvModReq_UB "Update bit for signal DrvModReq";
CM_ SG_ 768 EngN "Engine Speed [rpm]
Engine Speed derivative [rpm/s]";
CM_ SG_ 768 EngNChks "Engine Speed [rpm]
Engine Speed derivative [rpm/s]";
CM_ SG_ 768 EngNCntr "Engine Speed [rpm]
Engine Speed derivative [rpm/s]";
CM_ SG_ 768 EngNSafe_UB "Update bit for signal group EngNSafe; EngN EngNChks EngNCntr EngNSafeEngNGrdt ";
CM_ SG_ 768 EngNSafeEngNGrdt "Engine Speed [rpm]
Engine Speed derivative [rpm/s]";
CM_ SG_ 768 FuLvlRawActvSide_UB "Update bit for signal group FuLvlRawActvSide; FuLvlRawActvSideQly FuLvlRawActvSideVal ";
CM_ SG_ 768 FuLvlRawActvSideQly "Raw value from fuel level sensor at the active side (if saddle tank) converted via fuel table to Liter. Quality Flag";
CM_ SG_ 768 FuLvlRawActvSideVal "Raw value from fuel level sensor at the active side (if saddle tank) converted via fuel table to Liter. Fuel level value converted from fuel table";
CM_ SG_ 784 BkpOfDstTrvld "Indicated odometer (total driven distance) value in km.";
CM_ SG_ 784 BkpOfDstTrvld_UB "Update bit for signal BkpOfDstTrvld";
CM_ SG_ 784 ClkFmt "Settings for units and formats that shall be used for indication in the vehicle Clock Format";
CM_ SG_ 784 DstLong "Settings for units and formats that shall be used for indication in the vehicle Long Distance Units";
CM_ SG_ 784 DstSho "Settings for units and formats that shall be used for indication in the vehicle Short Distance Units";
CM_ SG_ 784 FltIndcrTurnRiFrnt "Light source failure (open load or short circuit) indication to driver, right front direction indicator.";
CM_ SG_ 784 FltIndcrTurnRiFrnt_UB "Update bit for signal FltIndcrTurnRiFrnt";
CM_ SG_ 784 FltIndcrTurnRiRe "Light source failure (open load or short circuit) indication to driver, right rear direction indicator.";
CM_ SG_ 784 FltIndcrTurnRiRe_UB "Update bit for signal FltIndcrTurnRiRe";
CM_ SG_ 784 FuCnsUnit "Settings for units and formats that shall be used for indication in the vehicle Fuel Consumption Units";
CM_ SG_ 784 IdPenForUnits "Settings for units and formats that shall be used for indication in the vehicle Personal Settings";
CM_ SG_ 784 IndcnUnit_UB "Update bit for signal group IndcnUnit; ClkFmt DstLong DstSho FuCnsUnit IdPenForUnits IndcnUnitDateFmt PUnit SpdUnit TUnit VolUnit ";
CM_ SG_ 784 IndcnUnitDateFmt "Settings for units and formats that shall be used for indication in the vehicle DateFormat";
CM_ SG_ 784 PUnit "Settings for units and formats that shall be used for indication in the vehicle Pressure Unit";
CM_ SG_ 784 SpdUnit "Settings for units and formats that shall be used for indication in the vehicle Speed Units";
CM_ SG_ 784 TUnit "Settings for units and formats that shall be used for indication in the vehicle Temperature Unit";
CM_ SG_ 784 VolUnit "Settings for units and formats that shall be used for indication in the vehicle Volume Units";
CM_ SG_ 464 AmbTIndcd "Indicated (damped) ambient temp data from the instrument cluster. Indicated ambient temperature";
CM_ SG_ 464 AmbTIndcdQf "Indicated (damped) ambient temp data from the instrument cluster. QF";
CM_ SG_ 464 AmbTIndcdUnit "Indicated (damped) ambient temp data from the instrument cluster. Unit of the indicated temperature";
CM_ SG_ 464 AmbTIndcdWithUnit_UB "Update bit for signal group AmbTIndcdWithUnit; AmbTIndcd AmbTIndcdQf AmbTIndcdUnit ";
CM_ SG_ 464 AmbTRaw_UB "Update bit for signal group AmbTRaw; AmbTRawQly AmbTRawVal ";
CM_ SG_ 464 AmbTRawQly "Unfiltered ambient temp raw data in deg C. Quality Factor of the ambient temp";
CM_ SG_ 464 AmbTRawVal "Unfiltered ambient temp raw data in deg C. Ambient temp value";
CM_ SG_ 464 FltOfBeamLoLe "Light source failure (open load or short circuit) indication to driver, left low beam.";
CM_ SG_ 464 FltOfBeamLoLe_UB "Update bit for signal FltOfBeamLoLe";
CM_ SG_ 464 FltOfBrkLiHiMntd "Light source failure (open load or short circuit) indication to driver, CHMSL.";
CM_ SG_ 464 FltOfBrkLiHiMntd_UB "Update bit for signal FltOfBrkLiHiMntd";
CM_ SG_ 464 FltOfPlateNr "Light source failure (open load or short circuit) indication to driver, reg plate light.";
CM_ SG_ 464 FltOfPlateNr_UB "Update bit for signal FltOfPlateNr";
CM_ SG_ 464 FltOfPosnReRi "Light source failure (open load or short circuit) indication to driver, right rear position light.";
CM_ SG_ 464 FltOfPosnReRi_UB "Update bit for signal FltOfPosnReRi";
CM_ SG_ 464 RlyPwrDistbnCmd1WdPreBattSaveCmd "Prewarning that BatterySaver relay will be shut off. Normally '0' but when warning alerts, the value changes to '1', 30 sec prior the shut off. ";
CM_ SG_ 464 RlyPwrDistbnCmd1WdPreBattSa_0000 "Update bit for signal RlyPwrDistbnCmd1WdPreBattSaveCmd";
CM_ SG_ 464 VehSpdIndcd_UB "Update bit for signal group VehSpdIndcd; VehSpdIndcdUnit VehSpdIndcdVal ";
CM_ SG_ 464 VehSpdIndcdUnit "Indicated (filtered) vehicle speed value with the current vehicle speed unit. Unit for vehicle speed";
CM_ SG_ 464 VehSpdIndcdVal "Indicated (filtered) vehicle speed value with the current vehicle speed unit. Vehicle speed";
CM_ SG_ 464 WipgInfo_UB "Update bit for signal group WipgInfo; WipgInfoWipgSpdInfo WipgInfoWiprActv WipgInfoWiprInWipgAr ";
CM_ SG_ 464 WipgInfoWipgSpdInfo " Information regarding how the wipers are run";
CM_ SG_ 464 WipgInfoWiprActv " 0=No wiping, 1=Wiping";
CM_ SG_ 464 WipgInfoWiprInWipgAr " 0=Wiper in lower reversing area or parked, 1=Wiper in wiping area";
CM_ SG_ 848 ClimaStrtTiSts "Informs if wake up of climate control will be done.";
CM_ SG_ 848 ClimaStrtTiSts_UB "Update bit for signal ClimaStrtTiSts";
CM_ SG_ 848 Day "Current time (Hr, Min and Sec) and date (Year, Months and days) data for indication. See requirement for more information about the signals. Day";
CM_ SG_ 848 FltOfPosnReLe "Light source failure (open load or short circuit) indication to driver, left rear position light.";
CM_ SG_ 848 FltOfPosnReLe_UB "Update bit for signal FltOfPosnReLe";
CM_ SG_ 848 Hr "Current time (Hr, Min and Sec) and date (Year, Months and days) data for indication. See requirement for more information about the signals. Hour";
CM_ SG_ 848 Mins "Current time (Hr, Min and Sec) and date (Year, Months and days) data for indication. See requirement for more information about the signals. Minutes";
CM_ SG_ 848 Mth "Current time (Hr, Min and Sec) and date (Year, Months and days) data for indication. See requirement for more information about the signals. Month, 1-12";
CM_ SG_ 848 Sec "Current time (Hr, Min and Sec) and date (Year, Months and days) data for indication. See requirement for more information about the signals. Seconds";
CM_ SG_ 848 TiAndDateIndcn_UB "Update bit for signal group TiAndDateIndcn; Day Hr Mins Mth Sec TiAndDateVld Yr ";
CM_ SG_ 848 TiAndDateVld "Current time (Hr, Min and Sec) and date (Year, Months and days) data for indication. See requirement for more information about the signals. Signal qualifier, No means values should be ignored.";
CM_ SG_ 848 Yr "Current time (Hr, Min and Sec) and date (Year, Months and days) data for indication. See requirement for more information about the signals. Year, 0-99";
CM_ SG_ 880 CarTiGlb "Presents a tiime value that shall be used by all ECUs to time-stamp diagnsotic trouble codes (DTC) according to the requirements for Global DTC snapshot data.";
CM_ SG_ 880 CarTiGlb_UB "Update bit for signal CarTiGlb";
CM_ SG_ 880 ClimaCmd "Indicates whether the climate sub-system is allowed by Central Load Control to start a requested operation.
";
CM_ SG_ 880 ClimaCmd_UB "Update bit for signal ClimaCmd";
CM_ SG_ 880 EgyCnsAllwdForClima "Energy consumption allowed for climate.
";
CM_ SG_ 880 EgyCnsAllwdForClima_UB "Update bit for signal EgyCnsAllwdForClima";
CM_ SG_ 880 FltFogLiRe "Light source failure (open load or short circuit) indication to driver, fog light rear.";
CM_ SG_ 880 FltFogLiRe_UB "Update bit for signal FltFogLiRe";
CM_ SG_ 880 FltIndcrTurnLeFrnt "Light source failure (open load or short circuit) indication to driver, left front direction indicator.";
CM_ SG_ 880 FltIndcrTurnLeFrnt_UB "Update bit for signal FltIndcrTurnLeFrnt";
CM_ SG_ 880 FltLiSideMkrFrnt "Light source failure (open load or short circuit) indication to driver, front side marker light.";
CM_ SG_ 880 FltLiSideMkrFrnt_UB "Update bit for signal FltLiSideMkrFrnt";
CM_ SG_ 880 FltOfBeamHiLe "Light source failure (open load or short circuit) indication to driver, left high beam.";
CM_ SG_ 880 FltOfBeamHiLe_UB "Update bit for signal FltOfBeamHiLe";
CM_ SG_ 880 FltOfBeamHiRi "Light source failure (open load or short circuit) indication to driver, right high beam.";
CM_ SG_ 880 FltOfBeamHiRi_UB "Update bit for signal FltOfBeamHiRi";
CM_ SG_ 880 FltOfBeamLoRi "Light source failure (open load or short circuit) indication to driver, right low beam.";
CM_ SG_ 880 FltOfBeamLoRi_UB "Update bit for signal FltOfBeamLoRi";
CM_ SG_ 880 FltOfLiPosnFrntLe "Light source failure (open load or short circuit) indication to driver, left front position light.";
CM_ SG_ 880 FltOfLiPosnFrntLe_UB "Update bit for signal FltOfLiPosnFrntLe";
CM_ SG_ 880 PwrSplyErrSts "Status of Power supply system
0: No fault
1; Alternator mechanical fault
2: Alternator electrical fault
3: Alternator temperature fault
4: Alternator communication fault
5: Over voltage during driving
6: Battery switch communication fault
7: Battery switch HW fault
8: Low voltage during driving
9: Battery sensor communication fault
10: Battery sensor HW fault
11: Support battery charging fault
12: DcDc communication fault
13: DcDc electrical fault
14: DcDc temperature fault

";
CM_ SG_ 880 PwrSplyErrSts_UB "Update bit for signal PwrSplyErrSts";
CM_ SG_ 880 WshrFldSts "Information regarding if the washer fluid level is low. 
On = Washer Fluid Level Low
Off = Washer Fluid Level Not Low. ";
CM_ SG_ 880 WshrFldSts_UB "Update bit for signal WshrFldSts";
CM_ SG_ 864 VinBlk "VehicleIdentificationNumber: The Vin signal data is divided into 3 separate blocks that are transmitted in a sequential loop, 
using an 8-byte record: Block counter (MSB) + 7 character/ASCII byte positions.
When transmitted, block 1 will contain current VIN characters #1 - #7, block 2 -> #8 - #14, block 3 -> #15 - #17.
Any fault is indicated using 255. Block number identifying VIN characters: 0x01: VIN1-7, 0x02: VIN8-14 or 0x03 VIN15-17.";
CM_ SG_ 864 VinPosn1 "VehicleIdentificationNumber: The Vin signal data is divided into 3 separate blocks that are transmitted in a sequential loop, 
using an 8-byte record: Block counter (MSB) + 7 character/ASCII byte positions.
When transmitted, block 1 will contain current VIN characters #1 - #7, block 2 -> #8 - #14, block 3 -> #15 - #17.
Any fault is indicated using 255. Block number dependant - VIN char identifier (ASCII-coded)";
CM_ SG_ 864 VinPosn2 "VehicleIdentificationNumber: The Vin signal data is divided into 3 separate blocks that are transmitted in a sequential loop, 
using an 8-byte record: Block counter (MSB) + 7 character/ASCII byte positions.
When transmitted, block 1 will contain current VIN characters #1 - #7, block 2 -> #8 - #14, block 3 -> #15 - #17.
Any fault is indicated using 255. Block number dependant - VIN char identifier (ASCII-coded)";
CM_ SG_ 864 VinPosn3 "VehicleIdentificationNumber: The Vin signal data is divided into 3 separate blocks that are transmitted in a sequential loop, 
using an 8-byte record: Block counter (MSB) + 7 character/ASCII byte positions.
When transmitted, block 1 will contain current VIN characters #1 - #7, block 2 -> #8 - #14, block 3 -> #15 - #17.
Any fault is indicated using 255. Block number dependant - VIN char identifier (ASCII-coded)";
CM_ SG_ 864 VinPosn4 "VehicleIdentificationNumber: The Vin signal data is divided into 3 separate blocks that are transmitted in a sequential loop, 
using an 8-byte record: Block counter (MSB) + 7 character/ASCII byte positions.
When transmitted, block 1 will contain current VIN characters #1 - #7, block 2 -> #8 - #14, block 3 -> #15 - #17.
Any fault is indicated using 255. Block number dependant - VIN char identifier (ASCII-coded)";
CM_ SG_ 864 VinPosn5 "VehicleIdentificationNumber: The Vin signal data is divided into 3 separate blocks that are transmitted in a sequential loop, 
using an 8-byte record: Block counter (MSB) + 7 character/ASCII byte positions.
When transmitted, block 1 will contain current VIN characters #1 - #7, block 2 -> #8 - #14, block 3 -> #15 - #17.
Any fault is indicated using 255. Block number dependant - VIN char identifier (ASCII-coded)";
CM_ SG_ 864 VinPosn6 "VehicleIdentificationNumber: The Vin signal data is divided into 3 separate blocks that are transmitted in a sequential loop, 
using an 8-byte record: Block counter (MSB) + 7 character/ASCII byte positions.
When transmitted, block 1 will contain current VIN characters #1 - #7, block 2 -> #8 - #14, block 3 -> #15 - #17.
Any fault is indicated using 255. Block number dependant - VIN char identifier (ASCII-coded)";
CM_ SG_ 864 VinPosn7 "VehicleIdentificationNumber: The Vin signal data is divided into 3 separate blocks that are transmitted in a sequential loop, 
using an 8-byte record: Block counter (MSB) + 7 character/ASCII byte positions.
When transmitted, block 1 will contain current VIN characters #1 - #7, block 2 -> #8 - #14, block 3 -> #15 - #17.
Any fault is indicated using 255. Block number dependant - VIN char identifier (ASCII-coded)";
CM_ SG_ 896 AntithftActvnNotif "Request to telematics module to send a theft notification.";
CM_ SG_ 896 AntithftActvnNotif_UB "Update bit for signal AntithftActvnNotif";
CM_ SG_ 896 ClimaPwrAllwd "Tells how much power the climate system is allowed to consume as decided by dynamic load control.
";
CM_ SG_ 896 ClimaPwrAllwd_UB "Update bit for signal ClimaPwrAllwd";
CM_ SG_ 896 CurtReDirCmd_UB "Update bit for signal CurtReDirCmd";
CM_ SG_ 896 FltLiDaytiRunngLe "Light source failure (open load or short circuit) indication to driver, left DRL.";
CM_ SG_ 896 FltLiDaytiRunngLe_UB "Update bit for signal FltLiDaytiRunngLe";
CM_ SG_ 896 FltOfBrkLiLe "Light source failure (open load or short circuit) indication to driver, brake light left.";
CM_ SG_ 896 FltOfBrkLiLe_UB "Update bit for signal FltOfBrkLiLe";
CM_ SG_ 896 FltOfLiDaytiRunngRi "Light source failure (open load or short circuit) indication to driver, right DRL.";
CM_ SG_ 896 FltOfLiDaytiRunngRi_UB "Update bit for signal FltOfLiDaytiRunngRi";
CM_ SG_ 896 FltOfLiPosnFrntRi "Light source failure (open load or short circuit) indication to driver, right front position light.";
CM_ SG_ 896 FltOfLiPosnFrntRi_UB "Update bit for signal FltOfLiPosnFrntRi";
CM_ SG_ 896 IndcrPatCmd1WdCmd_UB "Update bit for signal group IndcrPatCmd1WdCmd; IndcrPatCmd1WdTiOff IndcrPatCmd1WdTiOn ";
CM_ SG_ 896 IndcrPatCmd1WdTiOff "Used for Hazard Sleep (subfunction to Hazard Warning Light).

This signal holds the pattern of the flashing to use when buses are asleep and TRM/DCUs shall flash synchronized by themselves.

Holds both on and off timing in two separate record items. HWL Off time";
CM_ SG_ 896 IndcrPatCmd1WdTiOn "Used for Hazard Sleep (subfunction to Hazard Warning Light).

This signal holds the pattern of the flashing to use when buses are asleep and TRM/DCUs shall flash synchronized by themselves.

Holds both on and off timing in two separate record items. HWL On time";
CM_ SG_ 896 StrtRemSts1WdStrtRemSts "Status signal for EngineRemoteStart send to climate for control of climatization.";
CM_ SG_ 896 StrtRemSts1WdStrtRemSts_UB "Update bit for signal StrtRemSts1WdStrtRemSts";
CM_ SG_ 896 TrLockSts "TrLockSts - Tailgate or bootlid lock status

When tailgate/bootlid is locked, it is not possible to open the tailgate/bootlid by the outer door handle soft touch button.

LockStsUkwn (Lock Status Unknown) - Lock status of tailgate/bootlid Unknown
Unlckd - Tailgate/Bootlid is unlocked
Lockd - Tailgate/Bootlid is locked
SafeLockd - Not used for Tailgate/Bootlid
";
CM_ SG_ 896 TrLockSts_UB "Update bit for signal TrLockSts";
CM_ SG_ 816 FltIndcrTurnLeRe "Light source failure (open load or short circuit) indication to driver, left rear direction indicator.";
CM_ SG_ 816 FltIndcrTurnLeRe_UB "Update bit for signal FltIndcrTurnLeRe";
CM_ SG_ 816 FltOfBrkLiRi "Light source failure (open load or short circuit) indication to driver, brake light right.";
CM_ SG_ 816 FltOfBrkLiRi_UB "Update bit for signal FltOfBrkLiRi";
CM_ SG_ 816 FltOfFogLiFrnt "Light source failure (open load or short circuit) indication to driver, fog light front.";
CM_ SG_ 816 FltOfFogLiFrnt_UB "Update bit for signal FltOfFogLiFrnt";
CM_ SG_ 816 ProfPenSts1 "Signal communicates which profile that is active in the car (Personal settings).";
CM_ SG_ 816 ProfPenSts1_UB "Update bit for signal ProfPenSts1";
CM_ SG_ 816 TirePFrntLe "Data about Tire pressure ";
CM_ SG_ 816 TirePFrntRi "Data about Tire pressure ";
CM_ SG_ 816 TirePMonData_UB "Update bit for signal group TirePMonData; TirePFrntLe TirePFrntRi TirePMonSts TirePReLe TirePReRi ";
CM_ SG_ 816 TirePMonSts "Data about Tire pressure ";
CM_ SG_ 816 TirePReLe "Data about Tire pressure ";
CM_ SG_ 816 TirePReRi "Data about Tire pressure ";
CM_ SG_ 816 VehBattUGroup_UB "Update bit for signal group VehBattUGroup; VehBattUSysU VehBattUSysUQf ";
CM_ SG_ 816 VehBattUSysU "Present vehicle voltage measured by CEM with QF.

QF values:
3: Value Reliable
2: Value from back up sensor
1: Init
0: Value not reliable System Voltage";
CM_ SG_ 816 VehBattUSysUQf "Present vehicle voltage measured by CEM with QF.

QF values:
3: Value Reliable
2: Value from back up sensor
1: Init
0: Value not reliable System voltaeg quality factor";
CM_ SG_ 832 VehCfgPrmBlk "VehicleConfigurationParameters: Car Config container signal. 
Values of Car Config parameters #1 - #504 are mapped into 72 blocks. 
Each block is published in this signal using an 8-byte record: Block counter (MSB) + 7 parameter value byte positions.
Block counter runs through all 72 blocks in a sequential loop (normal operation). 
When transmitted, block 1 will contain current values on Car Config parameters #1 - #7, block 2 -> #8 - #14 ... block 72 -> #498 - #504.
Any faulty parameter value is indicated using 255. Block ID for specific Car Configuration parameter sequence";
CM_ SG_ 832 VehCfgPrmVal1 "VehicleConfigurationParameters: Car Config container signal. 
Values of Car Config parameters #1 - #504 are mapped into 72 blocks. 
Each block is published in this signal using an 8-byte record: Block counter (MSB) + 7 parameter value byte positions.
Block counter runs through all 72 blocks in a sequential loop (normal operation). 
When transmitted, block 1 will contain current values on Car Config parameters #1 - #7, block 2 -> #8 - #14 ... block 72 -> #498 - #504.
Any faulty parameter value is indicated using 255. 1st position in specific CCP number sequence - Block ID dependant";
CM_ SG_ 832 VehCfgPrmVal2 "VehicleConfigurationParameters: Car Config container signal. 
Values of Car Config parameters #1 - #504 are mapped into 72 blocks. 
Each block is published in this signal using an 8-byte record: Block counter (MSB) + 7 parameter value byte positions.
Block counter runs through all 72 blocks in a sequential loop (normal operation). 
When transmitted, block 1 will contain current values on Car Config parameters #1 - #7, block 2 -> #8 - #14 ... block 72 -> #498 - #504.
Any faulty parameter value is indicated using 255. 2nd position in specific CCP number sequence - Block ID dependant";
CM_ SG_ 832 VehCfgPrmVal3 "VehicleConfigurationParameters: Car Config container signal. 
Values of Car Config parameters #1 - #504 are mapped into 72 blocks. 
Each block is published in this signal using an 8-byte record: Block counter (MSB) + 7 parameter value byte positions.
Block counter runs through all 72 blocks in a sequential loop (normal operation). 
When transmitted, block 1 will contain current values on Car Config parameters #1 - #7, block 2 -> #8 - #14 ... block 72 -> #498 - #504.
Any faulty parameter value is indicated using 255. 3rd position in specific CCP number sequence - Block ID dependant";
CM_ SG_ 832 VehCfgPrmVal4 "VehicleConfigurationParameters: Car Config container signal. 
Values of Car Config parameters #1 - #504 are mapped into 72 blocks. 
Each block is published in this signal using an 8-byte record: Block counter (MSB) + 7 parameter value byte positions.
Block counter runs through all 72 blocks in a sequential loop (normal operation). 
When transmitted, block 1 will contain current values on Car Config parameters #1 - #7, block 2 -> #8 - #14 ... block 72 -> #498 - #504.
Any faulty parameter value is indicated using 255. 4th position in specific CCP number sequence - Block ID dependant";
CM_ SG_ 832 VehCfgPrmVal5 "VehicleConfigurationParameters: Car Config container signal. 
Values of Car Config parameters #1 - #504 are mapped into 72 blocks. 
Each block is published in this signal using an 8-byte record: Block counter (MSB) + 7 parameter value byte positions.
Block counter runs through all 72 blocks in a sequential loop (normal operation). 
When transmitted, block 1 will contain current values on Car Config parameters #1 - #7, block 2 -> #8 - #14 ... block 72 -> #498 - #504.
Any faulty parameter value is indicated using 255. 5th position in specific CCP number sequence - Block ID dependant";
CM_ SG_ 832 VehCfgPrmVal6 "VehicleConfigurationParameters: Car Config container signal. 
Values of Car Config parameters #1 - #504 are mapped into 72 blocks. 
Each block is published in this signal using an 8-byte record: Block counter (MSB) + 7 parameter value byte positions.
Block counter runs through all 72 blocks in a sequential loop (normal operation). 
When transmitted, block 1 will contain current values on Car Config parameters #1 - #7, block 2 -> #8 - #14 ... block 72 -> #498 - #504.
Any faulty parameter value is indicated using 255. 6th position in specific CCP number sequence - Block ID dependant";
CM_ SG_ 832 VehCfgPrmVal7 "VehicleConfigurationParameters: Car Config container signal. 
Values of Car Config parameters #1 - #504 are mapped into 72 blocks. 
Each block is published in this signal using an 8-byte record: Block counter (MSB) + 7 parameter value byte positions.
Block counter runs through all 72 blocks in a sequential loop (normal operation). 
When transmitted, block 1 will contain current values on Car Config parameters #1 - #7, block 2 -> #8 - #14 ... block 72 -> #498 - #504.
Any faulty parameter value is indicated using 255. 7th position in specific CCP number sequence - Block ID dependant";
CM_ SG_ 512 CmptmtTFrnt "Measured temperature in compartment. Sensor has a small aspiration fan that sucks air pass temperature sensor. Component is located in the middle center console.  Temperature inside compartment";
CM_ SG_ 512 CmptmtTFrntGroup_UB "Update bit for signal group CmptmtTFrntGroup; CmptmtTFrnt CmptmtTFrntQf FanForCmptmtTRunng ";
CM_ SG_ 512 CmptmtTFrntQf "Measured temperature in compartment. Sensor has a small aspiration fan that sucks air pass temperature sensor. Component is located in the middle center console.  Quality factor of compartment temperature sensor";
CM_ SG_ 512 DispHvBattLvlOfChrg "HV battery State-Of-Charge (SOC) value for display to driver. Note: this value may differ from the actual battery SOC. ";
CM_ SG_ 512 DispHvBattLvlOfChrg_UB "Update bit for signal DispHvBattLvlOfChrg";
CM_ SG_ 512 FanForCmptmtTRunng "Measured temperature in compartment. Sensor has a small aspiration fan that sucks air pass temperature sensor. Component is located in the middle center console.  Aspiration fan for compartment incar sensor is running";
CM_ SG_ 50 CryptoDoorDrvrLockCmd_UB "Update bit for signal group CryptoDoorDrvrLockCmd; CryptoDoorDrvrLockCmdAuthentCod1 CryptoDoorDrvrLockCmdAuthentCod2 CryptoDoorDrvrLockCmdCntr CryptoDoorDrvrLockCmdLockActvn ";
CM_ SG_ 50 CryptoDoorDrvrLockCmdAuthentCod1 " MAC first 2 bytes";
CM_ SG_ 50 CryptoDoorDrvrLockCmdAuthentCod2 " MAC second 2 bytes";
CM_ SG_ 50 CryptoDoorDrvrLockCmdCntr " Counter";
CM_ SG_ 50 CryptoDoorDrvrLockCmdLockActvn " Lock and unlock activation";
CM_ SG_ 56 CryptoDoorDrvrLockReCmd_UB "Update bit for signal group CryptoDoorDrvrLockReCmd; CryptoDoorDrvrLockReCmdAuthentCod1 CryptoDoorDrvrLockReCmdAuthentCod2 CryptoDoorDrvrLockReCmdCntr CryptoDoorDrvrLockReCmdLockActvn ";
CM_ SG_ 56 CryptoDoorDrvrLockReCmdAuthentCo " MAC first 2 bytes";
CM_ SG_ 56 CryptoDoorDrvrLockReCmdAuth_0000 " MAC second 2 bytes";
CM_ SG_ 56 CryptoDoorDrvrLockReCmdCntr " Counter";
CM_ SG_ 56 CryptoDoorDrvrLockReCmdLockActvn " Lock and unlock activation";
CM_ SG_ 56 TaxiLockCmd_UB "Update bit for signal TaxiLockCmd";
CM_ SG_ 53 CryptoDoorPassLockCmd_UB "Update bit for signal group CryptoDoorPassLockCmd; CryptoDoorPassLockCmdAuthentCod1 CryptoDoorPassLockCmdAuthentCod2 CryptoDoorPassLockCmdCntr CryptoDoorPassLockCmdLockActvn ";
CM_ SG_ 53 CryptoDoorPassLockCmdAuthentCod1 " MAC first 2 bytes";
CM_ SG_ 53 CryptoDoorPassLockCmdAuthentCod2 " MAC second 2 bytes";
CM_ SG_ 53 CryptoDoorPassLockCmdCntr " Counter";
CM_ SG_ 53 CryptoDoorPassLockCmdLockActvn " Lock and unlock activation";
CM_ SG_ 58 CryptoDoorPassLockReCmd_UB "Update bit for signal group CryptoDoorPassLockReCmd; CryptoDoorPassLockReCmdAuthentCod1 CryptoDoorPassLockReCmdAuthentCod2 CryptoDoorPassLockReCmdCntr CryptoDoorPassLockReCmdLockActvn ";
CM_ SG_ 58 CryptoDoorPassLockReCmdAuthentCo " MAC first 2 bytes";
CM_ SG_ 58 CryptoDoorPassLockReCmdAuth_0000 " MAC second 2 bytes";
CM_ SG_ 58 CryptoDoorPassLockReCmdCntr " Counter";
CM_ SG_ 58 CryptoDoorPassLockReCmdLockActvn " Lock and unlock activation";
CM_ SG_ 58 DstEstimdToEmptyForDrvgElec "Estimated remaining driving range in electric only driving for current HV battery energy content.";
CM_ SG_ 58 DstEstimdToEmptyForDrvgElec_UB "Update bit for signal DstEstimdToEmptyForDrvgElec";
CM_ SG_ 567 ClngRqrdFromHmi_UB "Update bit for signal ClngRqrdFromHmi";
CM_ SG_ 567 SecuAlrmMgrToTelmIni_UB "Update bit for signal group SecuAlrmMgrToTelmIni; SecuAlrmMgrToTelmIniMsgAuthentCod1 SecuAlrmMgrToTelmIniMsgAuthentCod2 SecuAlrmMgrToTelmIniSecuAlrmMagrToTelmIniMsgAuthentCodMsgTyp SecuAlrmMgrToTelmIniSecuIniNrRnd1 SecuAlrmMgrToTelmIniSecuIniNrRnd2 SecuAlrmMgrToTelmIniSecuIniNrRnd3 ";
CM_ SG_ 567 SecuAlrmMgrToTelmIniSecuAlrmMagr " authentication type";
CM_ SG_ 533 AirClngReq "Ionizer request from HMI to CCM.
 ";
CM_ SG_ 533 AirClngReq_UB "Update bit for signal AirClngReq";
CM_ SG_ 533 CryptoTelmLockgCenReqInin "Request of an initialization of the secure communication for RDU / telamatic unlock ";
CM_ SG_ 533 CryptoTelmLockgCenReqInin_UB "Update bit for signal CryptoTelmLockgCenReqInin";
CM_ SG_ 533 HmiSeatClimaExtd_UB "Update bit for signal group HmiSeatClimaExtd; HmiSeatClimaExtdHmiSeatVentnForRowSecLe HmiSeatClimaExtdHmiSeatVentnForRowSecRi ";
CM_ SG_ 533 HmiSeatClimaExtdHmiSeatVentnForR "HMI/user requests for ventilation of second row. Ventilation level for seat second row left";
CM_ SG_ 533 HmiSeatClimaExtdHmiSeatVent_0000 "HMI/user requests for ventilation of second row. Ventilation level for seat second row right";
CM_ SG_ 566 SecuAntithftActvnNotif_UB "Update bit for signal group SecuAntithftActvnNotif; SecuAntithftActvnNotifSecuAntithftActvnNotif SecuAntithftActvnNotifSecuAntithftActvnNotifCntr SecuAntithftActvnNotifSecuAntithftActvnNotifMsgAuthentCod ";
CM_ SG_ 566 SecuAntithftActvnNotifSecuAntith " data message";
CM_ SG_ 566 SecuAntithftActvnNotifSecuA_0000 " counter in data message";
CM_ SG_ 566 SecuAntithftActvnNotifSecuA_0001 " MAC in data message";
CM_ SG_ 1407 BodyCntrForMissCom_UB "Update bit for signal BodyCntrForMissCom";
CM_ SG_ 1407 MstCfgIDBodyCAN_UB "Update bit for signal MstCfgIDBodyCAN";
CM_ SG_ 1281 NM_AW_CEM "Active Wakeup Bit, 0: Node has not woken up the network (passive wakeup), 1: Node has woken up the network (active Wakeup)";
CM_ SG_ 1281 NM_CS_CEM "NM Coordinator Sleep Bit, 0: Start of synchronized shutdown is not requested by main coordinator, 1: Start of synchronized shutdown is requested by main coordinator";
CM_ SG_ 1281 NM_RMR_CEM "Repeat Message Request Bit, 0: Repeat Message State not requested, 1: Repeat Message State requested";
CM_ SG_ 1281 NM_PNI_CEM "Partial Network Information Bit, 0: NM message contains no Partial Network request information, 1: NM message contains Partial Network request information";
CM_ SG_ 1281 NM_NodeID_CEM "Source Node Identifier";
CM_ SG_ 1452 TirePMonForDevDataByte0 "Tire Pressure monitoring data for Development  Byte0";
CM_ SG_ 1452 TirePMonForDevDataByte1 "Tire Pressure monitoring data for Development  Byte1";
CM_ SG_ 1452 TirePMonForDevDataByte2 "Tire Pressure monitoring data for Development  Byte2";
CM_ SG_ 1452 TirePMonForDevDataByte3 "Tire Pressure monitoring data for Development  Byte3";
CM_ SG_ 1452 TirePMonForDevDataByte4 "Tire Pressure monitoring data for Development  Byte4";
CM_ SG_ 1452 TirePMonForDevDataByte5 "Tire Pressure monitoring data for Development  Byte5";
CM_ SG_ 1452 TirePMonForDevDataByte6 "Tire Pressure monitoring data for Development  Byte6";
CM_ SG_ 1452 TirePMonForDevDataByte7 "Tire Pressure monitoring data for Development  Byte7";
CM_ SG_ 48 ChdLockgProtnFailrStsToHmi "'Signal sent from the Driver door module to the Driver information module to inform if there is a failure in the electric child lock funtionality
'
";
CM_ SG_ 48 ChdLockgProtnFailrStsToHmi_UB "Update bit for signal ChdLockgProtnFailrStsToHmi";
CM_ SG_ 48 ChdLockgProtnStsToHmi "'Signal sent from the Driver door module to the Driver information module to inform if the electric child lock  is ative or not
'
";
CM_ SG_ 48 ChdLockgProtnStsToHmi_UB "Update bit for signal ChdLockgProtnStsToHmi";
CM_ SG_ 48 ChdProtnCmd "'Signal sent from the Driver door module to the locking and window functionality in the rear Driver, and Passenger,  door modules. The signal contains information whether the power window disable function and the electric child lock function shall be enabled or disabled
'
";
CM_ SG_ 48 ChdProtnCmd_UB "Update bit for signal ChdProtnCmd";
CM_ SG_ 48 CrashUnlckFailrStsAtDrvrRe "CrashUnlckFailrStsAtDrvrRe - Driver Side Rear Door Crash Unlock Failure Status

This signal is set to On when a fault is detected that could lead to that driver side rear door is not correctly unlocked in case of impact. A warning shall be shown to the user via HMI.";
CM_ SG_ 48 CrashUnlckFailrStsAtDrvrRe_UB "Update bit for signal CrashUnlckFailrStsAtDrvrRe";
CM_ SG_ 48 DoorBtnPsdAtDrvr "Status if any of the driver door buttons is used.";
CM_ SG_ 48 DoorBtnPsdAtDrvr_UB "Update bit for signal DoorBtnPsdAtDrvr";
CM_ SG_ 48 DoorDrvrLockReSts "DoorDrvrLockReSts - Driver Side Rear Door Lock Status

Lock status:

LockStsUkwn - Lock Status Unknown
Unlckd - Unlocked
Lockd - Locked
SafeLockd - Safe Locked (Double Locked)";
CM_ SG_ 48 DoorDrvrLockReSts_UB "Update bit for signal DoorDrvrLockReSts";
CM_ SG_ 48 DoorDrvrLockSts "DoorDrvrLockSts - Driver Door Lock Status

Lock status:

LockStsUkwn - Lock Status Unknown
Unlckd - Unlocked
Lockd - Locked
SafeLockd - Safe Locked (Double Locked)";
CM_ SG_ 48 DoorDrvrLockSts_UB "Update bit for signal DoorDrvrLockSts";
CM_ SG_ 48 DoorDrvrSwtIntrLockgReq "DoorDrvrSwtIntrLockgReq - Driver Door Interior Locking Switch Request

Central locking/unlocking request from driver door interior central locking/unlocking switch

Idle - No Request
Unlck - Unlock request
Lock - Lock request";
CM_ SG_ 48 DoorDrvrSwtIntrLockgReq_UB "Update bit for signal DoorDrvrSwtIntrLockgReq";
CM_ SG_ 48 DoorDrvrSwtLockgReSts "DoorDrvrSwtLockgReSts - Driver Side Rear Door Locking Switch Status

Status of the driver side rear door interior locking switch:

Psd - Pressed
NotPsd - Not Pressed";
CM_ SG_ 48 DoorDrvrSwtLockgReSts_UB "Update bit for signal DoorDrvrSwtLockgReSts";
CM_ SG_ 48 LcmaLedStsDrvrSide "Signal which indicates if the LCMA LED HMI is broken or not.";
CM_ SG_ 48 LcmaLedStsDrvrSide_UB "Update bit for signal LcmaLedStsDrvrSide";
CM_ SG_ 48 MemBtn1 "Signals status of the driver memory buttons (true/false) Memory button 1";
CM_ SG_ 48 MemBtn2 "Signals status of the driver memory buttons (true/false) Memory Button 2";
CM_ SG_ 48 MemBtn3 "Signals status of the driver memory buttons (true/false) Memory Button 3";
CM_ SG_ 48 MemBtnM "Signals status of the driver memory buttons (true/false) Memory Button M";
CM_ SG_ 48 MemBtnPsd_UB "Update bit for signal group MemBtnPsd; MemBtn1 MemBtn2 MemBtn3 MemBtnM ";
CM_ SG_ 48 MirrAtDrvrInMovmt "Informs the Setting Management subsystem that the outer rear view mirrors are in movement. Driver side.";
CM_ SG_ 48 MirrAtDrvrInMovmt_UB "Update bit for signal MirrAtDrvrInMovmt";
CM_ SG_ 48 MirrBtnPsdAtDrvr "Tells if any mirror button has been pressed.";
CM_ SG_ 48 MirrBtnPsdAtDrvr_UB "Update bit for signal MirrBtnPsdAtDrvr";
CM_ SG_ 48 MirrCmdAtPassAdj "Signal group containing adjusment information for the outer rear view mirrors. Passanger side.
Joystick direction command, Fold command and Dip command. Mirror Position Adjust Command";
CM_ SG_ 48 MirrCmdAtPassDwn "Signal group containing adjusment information for the outer rear view mirrors. Passanger side.
Joystick direction command, Fold command and Dip command. Mirror down/dip command";
CM_ SG_ 48 MirrCmdAtPassFold "Signal group containing adjusment information for the outer rear view mirrors. Passanger side.
Joystick direction command, Fold command and Dip command. Mirror fold command";
CM_ SG_ 48 MirrCmdAtPassGroup_UB "Update bit for signal group MirrCmdAtPassGroup; MirrCmdAtPassAdj MirrCmdAtPassDwn MirrCmdAtPassFold ";
CM_ SG_ 48 MirrFoldStsAtDrvr "Reports the fold status of the outer rear view mirrors. Driver side.";
CM_ SG_ 48 MirrFoldStsAtDrvr_UB "Update bit for signal MirrFoldStsAtDrvr";
CM_ SG_ 48 WinPosnStsAtDrvrRe "'Signal sent to inform the rest of the car of the window position status for the rear driver side door. The value of the signal is either an approximated percentage of openness, of the window is moving or if the position is unkown.
'
";
CM_ SG_ 48 WinPosnStsAtDrvrRe_UB "Update bit for signal WinPosnStsAtDrvrRe";
CM_ SG_ 48 WinSwtReqToPass "'Signal sent from the Driver door module to the Passenger door module that represents the state of the window switch on the Driver door switchpack
'
";
CM_ SG_ 48 WinSwtReqToPass_UB "Update bit for signal WinSwtReqToPass";
CM_ SG_ 48 WinSwtReqToPassRe "'Signal sent from the Driver door module to the rear Passenger door module that represents the state of the window switch on the Driver door switchpack
'
";
CM_ SG_ 48 WinSwtReqToPassRe_UB "Update bit for signal WinSwtReqToPassRe";
CM_ SG_ 480 ActvnOfDoorSwtIllmn "Activates/deactivates the symbol illumination of the DDS. Dependent on VMM signals mostly.";
CM_ SG_ 480 ActvnOfDoorSwtIllmn_UB "Update bit for signal ActvnOfDoorSwtIllmn";
CM_ SG_ 480 AmbTQlyAtDrvrSide "Unfiltered ambient temp raw data in deg C from the driver door module, will only give valid values for right hand driven vehicles. Shall only be used by the amient temp manager at CEM, which will transmit the correct ambient temp raw value in the signal AmbTRaw.
 Quality Factor of the ambient temp";
CM_ SG_ 480 AmbTRawAtDrvrSide_UB "Update bit for signal group AmbTRawAtDrvrSide; AmbTQlyAtDrvrSide AmbTValAtDrvrSide ";
CM_ SG_ 480 AmbTValAtDrvrSide "Unfiltered ambient temp raw data in deg C from the driver door module, will only give valid values for right hand driven vehicles. Shall only be used by the amient temp manager at CEM, which will transmit the correct ambient temp raw value in the signal AmbTRaw.
 Ambient temp value";
CM_ SG_ 480 ChdWinProtnStsAtDrvrRe "'Signal sent from the rear driver door module to the Driver door module that informs of the local status of the power window disable functionality.
'
";
CM_ SG_ 480 ChdWinProtnStsAtDrvrRe_UB "Update bit for signal ChdWinProtnStsAtDrvrRe";
CM_ SG_ 480 CrashUnlckFailrStsAtDrvr "CrashUnlckFailrStsAtDrvr - Driver Door Crash Unlock Failure Status

This signal is set to On when a fault is detected that could lead to that driver door is not correctly unlocked in case of impact. A warning shall be shown to the user via HMI.";
CM_ SG_ 480 CrashUnlckFailrStsAtDrvr_UB "Update bit for signal CrashUnlckFailrStsAtDrvr";
CM_ SG_ 480 FltOfPuddleLiDrvr "Light source failure (open load or short circuit) indication to driver, puddle light driver side.";
CM_ SG_ 480 FltOfPuddleLiDrvr_UB "Update bit for signal FltOfPuddleLiDrvr";
CM_ SG_ 480 LiDrvrFltIndcrTurn "Light source failure (open load or short circuit) indication to driver, side direction indicator driver side.";
CM_ SG_ 480 LiDrvrFltIndcrTurn_UB "Update bit for signal LiDrvrFltIndcrTurn";
CM_ SG_ 480 MirrDefrstAtDrvSts "Status signal exterior rear view mirror electrical defroster driver side.";
CM_ SG_ 480 MirrDefrstAtDrvSts_UB "Update bit for signal MirrDefrstAtDrvSts";
CM_ SG_ 480 MirrDwnStsAtDrvr "Reports the status of the mirror dipping mode. Driver side.";
CM_ SG_ 480 MirrDwnStsAtDrvr_UB "Update bit for signal MirrDwnStsAtDrvr";
CM_ SG_ 480 WinPosnStsDrv "'Signal sent to inform the rest of the car of the window position status for the front driver side door. The value of the signal is either an approximated percentage of openness, of the window is moving or if the position is unkown.
'
";
CM_ SG_ 480 WinPosnStsDrv_UB "Update bit for signal WinPosnStsDrv";
CM_ SG_ 304 CryptoDoorDrvrLockCmdInin_UB "Update bit for signal group CryptoDoorDrvrLockCmdInin; CryptoDoorDrvrLockCmdIninCmdInin1 CryptoDoorDrvrLockCmdIninCmdInin2 CryptoDoorDrvrLockCmdIninCmdInin3 ";
CM_ SG_ 304 CryptoDoorDrvrLockCmdIninCmdInin "Request of an initialization of the secure communication for driver door unlock  Initialization request first byte";
CM_ SG_ 304 CryptoDoorDrvrLockCmdIninCm_0000 "Request of an initialization of the secure communication for driver door unlock  Initialization request second byte";
CM_ SG_ 304 CryptoDoorDrvrLockCmdIninCm_0001 "Request of an initialization of the secure communication for driver door unlock  Initialization request third byte";
CM_ SG_ 304 CryptoDoorDrvrLockReCmdInin_UB "Update bit for signal group CryptoDoorDrvrLockReCmdInin; CryptoDoorDrvrLockReCmdIninCmdInin1 CryptoDoorDrvrLockReCmdIninCmdInin2 CryptoDoorDrvrLockReCmdIninCmdInin3 ";
CM_ SG_ 304 CryptoDoorDrvrLockReCmdIninCmdIn "Request of an initialization of the secure communication for rear driver door unlock Initialization request first byte";
CM_ SG_ 304 CryptoDoorDrvrLockReCmdInin_0000 "Request of an initialization of the secure communication for rear driver door unlock Initialization request second byte";
CM_ SG_ 304 CryptoDoorDrvrLockReCmdInin_0001 "Request of an initialization of the secure communication for rear driver door unlock Initialization request third byte";
CM_ SG_ 1283 NM_AW_DDM "Active Wakeup Bit, 0: Node has not woken up the network (passive wakeup), 1: Node has woken up the network (active Wakeup)";
CM_ SG_ 1283 NM_CS_DDM "NM Coordinator Sleep Bit, 0: Start of synchronized shutdown is not requested by main coordinator, 1: Start of synchronized shutdown is requested by main coordinator";
CM_ SG_ 1283 NM_RMR_DDM "Repeat Message Request Bit, 0: Repeat Message State not requested, 1: Repeat Message State requested";
CM_ SG_ 1283 NM_PNI_DDM "Partial Network Information Bit, 0: NM message contains no Partial Network request information, 1: NM message contains Partial Network request information";
CM_ SG_ 1283 NM_NodeID_DDM "Source Node Identifier";
CM_ SG_ 1427 DevRespAtDrvrDoorByte0 "Development response from the Driver door module
 Byte0";
CM_ SG_ 1427 DevRespAtDrvrDoorByte1 "Development response from the Driver door module
 Byte1";
CM_ SG_ 1427 DevRespAtDrvrDoorByte2 "Development response from the Driver door module
 Byte2";
CM_ SG_ 1427 DevRespAtDrvrDoorByte3 "Development response from the Driver door module
 Byte3";
CM_ SG_ 1427 DevRespAtDrvrDoorByte4 "Development response from the Driver door module
 Byte4";
CM_ SG_ 1427 DevRespAtDrvrDoorByte5 "Development response from the Driver door module
 Byte5";
CM_ SG_ 1427 DevRespAtDrvrDoorByte6 "Development response from the Driver door module
 Byte6";
CM_ SG_ 1427 DevRespAtDrvrDoorByte7 "Development response from the Driver door module
 Byte7";
CM_ SG_ 1430 DevRespAtDrvrDoorReByte0 "Development response from the Rear Driver door module
 Byte0";
CM_ SG_ 1430 DevRespAtDrvrDoorReByte1 "Development response from the Rear Driver door module
 Byte1";
CM_ SG_ 1430 DevRespAtDrvrDoorReByte2 "Development response from the Rear Driver door module
 Byte2";
CM_ SG_ 1430 DevRespAtDrvrDoorReByte3 "Development response from the Rear Driver door module
 Byte3";
CM_ SG_ 1430 DevRespAtDrvrDoorReByte4 "Development response from the Rear Driver door module
 Byte4";
CM_ SG_ 1430 DevRespAtDrvrDoorReByte5 "Development response from the Rear Driver door module
 Byte5";
CM_ SG_ 1430 DevRespAtDrvrDoorReByte6 "Development response from the Rear Driver door module
 Byte6";
CM_ SG_ 1430 DevRespAtDrvrDoorReByte7 "Development response from the Rear Driver door module
 Byte7";
CM_ SG_ 1425 DevTx1AtDrvrDoorByte0 "Development transmission 1 from the Driver door module
 Byte0";
CM_ SG_ 1425 DevTx1AtDrvrDoorByte1 "Development transmission 1 from the Driver door module
 Byte1";
CM_ SG_ 1425 DevTx1AtDrvrDoorByte2 "Development transmission 1 from the Driver door module
 Byte2";
CM_ SG_ 1425 DevTx1AtDrvrDoorByte3 "Development transmission 1 from the Driver door module
 Byte3";
CM_ SG_ 1425 DevTx1AtDrvrDoorByte4 "Development transmission 1 from the Driver door module
 Byte4";
CM_ SG_ 1425 DevTx1AtDrvrDoorByte5 "Development transmission 1 from the Driver door module
 Byte5";
CM_ SG_ 1425 DevTx1AtDrvrDoorByte6 "Development transmission 1 from the Driver door module
 Byte6";
CM_ SG_ 1425 DevTx1AtDrvrDoorByte7 "Development transmission 1 from the Driver door module
 Byte7";
CM_ SG_ 1428 DevTx1AtDrvrDoorReByte0 "Development transmission 1 from the Rear Driver door module
 Byte0";
CM_ SG_ 1428 DevTx1AtDrvrDoorReByte1 "Development transmission 1 from the Rear Driver door module
 Byte1";
CM_ SG_ 1428 DevTx1AtDrvrDoorReByte2 "Development transmission 1 from the Rear Driver door module
 Byte2";
CM_ SG_ 1428 DevTx1AtDrvrDoorReByte3 "Development transmission 1 from the Rear Driver door module
 Byte3";
CM_ SG_ 1428 DevTx1AtDrvrDoorReByte4 "Development transmission 1 from the Rear Driver door module
 Byte4";
CM_ SG_ 1428 DevTx1AtDrvrDoorReByte5 "Development transmission 1 from the Rear Driver door module
 Byte5";
CM_ SG_ 1428 DevTx1AtDrvrDoorReByte6 "Development transmission 1 from the Rear Driver door module
 Byte6";
CM_ SG_ 1428 DevTx1AtDrvrDoorReByte7 "Development transmission 1 from the Rear Driver door module
 Byte7";
CM_ SG_ 1426 DevTx2AtDrvrDoorByte0 "Development transmission 2 from the Driver door module
 Byte0";
CM_ SG_ 1426 DevTx2AtDrvrDoorByte1 "Development transmission 2 from the Driver door module
 Byte1";
CM_ SG_ 1426 DevTx2AtDrvrDoorByte2 "Development transmission 2 from the Driver door module
 Byte2";
CM_ SG_ 1426 DevTx2AtDrvrDoorByte3 "Development transmission 2 from the Driver door module
 Byte3";
CM_ SG_ 1426 DevTx2AtDrvrDoorByte4 "Development transmission 2 from the Driver door module
 Byte4";
CM_ SG_ 1426 DevTx2AtDrvrDoorByte5 "Development transmission 2 from the Driver door module
 Byte5";
CM_ SG_ 1426 DevTx2AtDrvrDoorByte6 "Development transmission 2 from the Driver door module
 Byte6";
CM_ SG_ 1426 DevTx2AtDrvrDoorByte7 "Development transmission 2 from the Driver door module
 Byte7";
CM_ SG_ 1429 DevTx2AtDrvrDoorReByte0 "Development transmission 2 from the Rear Driver door module
 Byte0";
CM_ SG_ 1429 DevTx2AtDrvrDoorReByte1 "Development transmission 2 from the Rear Driver door module
 Byte1";
CM_ SG_ 1429 DevTx2AtDrvrDoorReByte2 "Development transmission 2 from the Rear Driver door module
 Byte2";
CM_ SG_ 1429 DevTx2AtDrvrDoorReByte3 "Development transmission 2 from the Rear Driver door module
 Byte3";
CM_ SG_ 1429 DevTx2AtDrvrDoorReByte4 "Development transmission 2 from the Rear Driver door module
 Byte4";
CM_ SG_ 1429 DevTx2AtDrvrDoorReByte5 "Development transmission 2 from the Rear Driver door module
 Byte5";
CM_ SG_ 1429 DevTx2AtDrvrDoorReByte6 "Development transmission 2 from the Rear Driver door module
 Byte6";
CM_ SG_ 1429 DevTx2AtDrvrDoorReByte7 "Development transmission 2 from the Rear Driver door module
 Byte7";
CM_ SG_ 1488 EndOfLineSigCtrlrByte0 " Byte0";
CM_ SG_ 1488 EndOfLineSigCtrlrByte1 " Byte1";
CM_ SG_ 1488 EndOfLineSigCtrlrByte2 " Byte2";
CM_ SG_ 1488 EndOfLineSigCtrlrByte3 " Byte3";
CM_ SG_ 1488 EndOfLineSigCtrlrByte4 " Byte4";
CM_ SG_ 1488 EndOfLineSigCtrlrByte5 " Byte5";
CM_ SG_ 1488 EndOfLineSigCtrlrByte6 " Byte6";
CM_ SG_ 1488 EndOfLineSigCtrlrByte7 " Byte7";
CM_ SG_ 1441 DevReqToDrvrDoorByte0 "Development request signal to the Driver door module
 Byte0";
CM_ SG_ 1441 DevReqToDrvrDoorByte1 "Development request signal to the Driver door module
 Byte1";
CM_ SG_ 1441 DevReqToDrvrDoorByte2 "Development request signal to the Driver door module
 Byte2";
CM_ SG_ 1441 DevReqToDrvrDoorByte3 "Development request signal to the Driver door module
 Byte3";
CM_ SG_ 1441 DevReqToDrvrDoorByte4 "Development request signal to the Driver door module
 Byte4";
CM_ SG_ 1441 DevReqToDrvrDoorByte5 "Development request signal to the Driver door module
 Byte5";
CM_ SG_ 1441 DevReqToDrvrDoorByte6 "Development request signal to the Driver door module
 Byte6";
CM_ SG_ 1441 DevReqToDrvrDoorByte7 "Development request signal to the Driver door module
 Byte7";
CM_ SG_ 1440 DevReqToDrvrDoorReByte0 "Development request signal to the Rear Driver door module Byte0";
CM_ SG_ 1440 DevReqToDrvrDoorReByte1 "Development request signal to the Rear Driver door module Byte1";
CM_ SG_ 1440 DevReqToDrvrDoorReByte2 "Development request signal to the Rear Driver door module Byte2";
CM_ SG_ 1440 DevReqToDrvrDoorReByte3 "Development request signal to the Rear Driver door module Byte3";
CM_ SG_ 1440 DevReqToDrvrDoorReByte4 "Development request signal to the Rear Driver door module Byte4";
CM_ SG_ 1440 DevReqToDrvrDoorReByte5 "Development request signal to the Rear Driver door module Byte5";
CM_ SG_ 1440 DevReqToDrvrDoorReByte6 "Development request signal to the Rear Driver door module Byte6";
CM_ SG_ 1440 DevReqToDrvrDoorReByte7 "Development request signal to the Rear Driver door module Byte7";
CM_ SG_ 1472 ETCBodyDevReqToDrvrSeatByte0 "KOSTIA request. Supplier specific signal used for their EOL test. Not transmitted in vehicle. Byte0";
CM_ SG_ 1472 ETCBodyDevReqToDrvrSeatByte1 "KOSTIA request. Supplier specific signal used for their EOL test. Not transmitted in vehicle. Byte1";
CM_ SG_ 1472 ETCBodyDevReqToDrvrSeatByte2 "KOSTIA request. Supplier specific signal used for their EOL test. Not transmitted in vehicle. Byte2";
CM_ SG_ 1472 ETCBodyDevReqToDrvrSeatByte3 "KOSTIA request. Supplier specific signal used for their EOL test. Not transmitted in vehicle. Byte3";
CM_ SG_ 1472 ETCBodyDevReqToDrvrSeatByte4 "KOSTIA request. Supplier specific signal used for their EOL test. Not transmitted in vehicle. Byte4";
CM_ SG_ 1472 ETCBodyDevReqToDrvrSeatByte5 "KOSTIA request. Supplier specific signal used for their EOL test. Not transmitted in vehicle. Byte5";
CM_ SG_ 1472 ETCBodyDevReqToDrvrSeatByte6 "KOSTIA request. Supplier specific signal used for their EOL test. Not transmitted in vehicle. Byte6";
CM_ SG_ 1472 ETCBodyDevReqToDrvrSeatByte7 "KOSTIA request. Supplier specific signal used for their EOL test. Not transmitted in vehicle. Byte7";
CM_ SG_ 1443 DevReqToPassDoorByte0 "Development request signal to the Passenger door module Byte0";
CM_ SG_ 1443 DevReqToPassDoorByte1 "Development request signal to the Passenger door module Byte1";
CM_ SG_ 1443 DevReqToPassDoorByte2 "Development request signal to the Passenger door module Byte2";
CM_ SG_ 1443 DevReqToPassDoorByte3 "Development request signal to the Passenger door module Byte3";
CM_ SG_ 1443 DevReqToPassDoorByte4 "Development request signal to the Passenger door module Byte4";
CM_ SG_ 1443 DevReqToPassDoorByte5 "Development request signal to the Passenger door module Byte5";
CM_ SG_ 1443 DevReqToPassDoorByte6 "Development request signal to the Passenger door module Byte6";
CM_ SG_ 1443 DevReqToPassDoorByte7 "Development request signal to the Passenger door module Byte7";
BA_DEF_ SG_  "GenSigDataID" STRING ;
BA_DEF_ SG_  "GenSigFuncType" ENUM  "NoFunction","not-used","not-used","not-used","not-used","not-used","not-used","not-used","not-used","not-used","not-used","not-used","not-used","not-used","not-used","CHK","CNTR";
BA_DEF_ SG_  "SigGroup" STRING ;
BA_DEF_ BO_  "GenMsgILSupport" ENUM  "No","Yes";
BA_DEF_ BO_  "GenMsgCycleTimeFast" INT 0 50000;
BA_DEF_ BO_  "GenMsgSendType" ENUM  "cyclic","spontaneous","cyclicIfActive","spontaneousWithDelay","cyclicAndSpontaneous","cyclicAndSpontaneousWithDelay","not_used","not_used","not_used","cyclicWithRepeatOnDemand";
BA_DEF_ BO_  "GenMsgCycleTime" FLOAT 0 300000;
BA_DEF_ BO_  "GenMsgStartDelayTime" FLOAT 0 300000;
BA_DEF_ BO_  "GenMsgDelayTime" FLOAT 0 300000;
BA_DEF_ SG_  "GenSigSendType" ENUM  "Cyclic","OnWrite","OnWriteWithRepetition","OnChange","OnChangeWithRepetition","IfActive","IfActiveWithRepetition","NoSigSendType";
BA_DEF_ SG_  "GenSigStartValue" FLOAT -1E+019 1E+019;
BA_DEF_ SG_  "SystemSignalLongSymbol" STRING ;
BA_DEF_DEF_  "GenSigDataID" "";
BA_DEF_DEF_  "GenSigFuncType" "NoFunction";
BA_DEF_DEF_  "SigGroup" "";
BA_DEF_DEF_  "GenMsgILSupport" "Yes";
BA_DEF_DEF_  "GenMsgCycleTimeFast" 2;
BA_DEF_DEF_  "GenMsgSendType" "spontaneous";
BA_DEF_DEF_  "GenMsgCycleTime" 0;
BA_DEF_DEF_  "GenMsgStartDelayTime" 0;
BA_DEF_DEF_  "GenMsgDelayTime" 0;
BA_DEF_DEF_  "GenSigSendType" "Cyclic";
BA_DEF_DEF_  "GenSigStartValue" 0;
BA_DEF_DEF_  "SystemSignalLongSymbol" "";
BA_ "GenMsgCycleTime" BO_ 528 500;
BA_ "GenMsgSendType" BO_ 528 0;
BA_ "GenMsgCycleTime" BO_ 544 500;
BA_ "GenMsgSendType" BO_ 544 0;
BA_ "GenMsgCycleTime" BO_ 608 1000;
BA_ "GenMsgSendType" BO_ 608 0;
BA_ "GenMsgCycleTime" BO_ 640 1000;
BA_ "GenMsgSendType" BO_ 640 0;
BA_ "GenMsgCycleTime" BO_ 592 1000;
BA_ "GenMsgSendType" BO_ 592 0;
BA_ "GenMsgCycleTime" BO_ 656 1000;
BA_ "GenMsgSendType" BO_ 656 0;
BA_ "GenMsgCycleTime" BO_ 624 1000;
BA_ "GenMsgSendType" BO_ 624 0;
BA_ "GenMsgCycleTime" BO_ 768 1000;
BA_ "GenMsgSendType" BO_ 768 0;
BA_ "GenMsgCycleTime" BO_ 784 1000;
BA_ "GenMsgSendType" BO_ 784 0;
BA_ "GenMsgCycleTime" BO_ 464 400;
BA_ "GenMsgSendType" BO_ 464 0;
BA_ "GenMsgCycleTime" BO_ 848 1000;
BA_ "GenMsgSendType" BO_ 848 0;
BA_ "GenMsgCycleTime" BO_ 880 1000;
BA_ "GenMsgSendType" BO_ 880 0;
BA_ "GenMsgCycleTime" BO_ 864 250;
BA_ "GenMsgCycleTime" BO_ 896 50;
BA_ "GenMsgSendType" BO_ 896 0;
BA_ "GenMsgCycleTime" BO_ 816 1000;
BA_ "GenMsgSendType" BO_ 816 0;
BA_ "GenMsgCycleTime" BO_ 832 125;
BA_ "GenMsgCycleTime" BO_ 512 500;
BA_ "GenMsgSendType" BO_ 512 0;
BA_ "GenMsgCycleTime" BO_ 50 10;
BA_ "GenMsgSendType" BO_ 50 0;
BA_ "GenMsgCycleTime" BO_ 56 10;
BA_ "GenMsgSendType" BO_ 56 0;
BA_ "GenMsgCycleTime" BO_ 53 10;
BA_ "GenMsgSendType" BO_ 53 0;
BA_ "GenMsgCycleTime" BO_ 58 10;
BA_ "GenMsgSendType" BO_ 58 0;
BA_ "GenMsgCycleTime" BO_ 567 600;
BA_ "GenMsgSendType" BO_ 567 0;
BA_ "GenMsgCycleTime" BO_ 533 500;
BA_ "GenMsgSendType" BO_ 533 0;
BA_ "GenMsgCycleTime" BO_ 566 600;
BA_ "GenMsgSendType" BO_ 566 0;
BA_ "GenMsgCycleTime" BO_ 1407 50;
BA_ "GenMsgSendType" BO_ 1407 0;
BA_ "GenMsgILSupport" BO_ 1281 0;
BA_ "GenMsgDelayTime" BO_ 1281 20;
BA_ "GenMsgDelayTime" BO_ 1452 10;
BA_ "GenMsgDelayTime" BO_ 2047 5;
BA_ "GenMsgDelayTime" BO_ 1809 5;
BA_ "GenMsgDelayTime" BO_ 1810 5;
BA_ "GenMsgDelayTime" BO_ 1413 5;
BA_ "GenMsgDelayTime" BO_ 1414 5;
BA_ "GenMsgDelayTime" BO_ 1415 5;
BA_ "GenMsgDelayTime" BO_ 1416 5;
BA_ "GenMsgDelayTime" BO_ 1811 5;
BA_ "GenMsgDelayTime" BO_ 1813 5;
BA_ "GenMsgDelayTime" BO_ 1812 5;
BA_ "GenMsgDelayTime" BO_ 1818 5;
BA_ "GenMsgDelayTime" BO_ 1815 5;
BA_ "GenMsgCycleTime" BO_ 48 10;
BA_ "GenMsgSendType" BO_ 48 0;
BA_ "GenMsgCycleTime" BO_ 480 400;
BA_ "GenMsgSendType" BO_ 480 0;
BA_ "GenMsgCycleTime" BO_ 304 150;
BA_ "GenMsgSendType" BO_ 304 0;
BA_ "GenMsgILSupport" BO_ 1283 0;
BA_ "GenMsgDelayTime" BO_ 1283 20;
BA_ "GenMsgDelayTime" BO_ 1427 10;
BA_ "GenMsgDelayTime" BO_ 1430 10;
BA_ "GenMsgDelayTime" BO_ 1425 10;
BA_ "GenMsgDelayTime" BO_ 1428 10;
BA_ "GenMsgDelayTime" BO_ 1426 10;
BA_ "GenMsgDelayTime" BO_ 1429 10;
BA_ "GenMsgDelayTime" BO_ 1554 5;
BA_ "GenMsgDelayTime" BO_ 1417 5;
BA_ "GenMsgDelayTime" BO_ 1488 1000;
BA_ "GenMsgDelayTime" BO_ 1489 1000;
BA_ "GenMsgDelayTime" BO_ 1441 10;
BA_ "GenMsgDelayTime" BO_ 1440 10;
BA_ "GenMsgDelayTime" BO_ 1472 1000;
BA_ "GenMsgDelayTime" BO_ 1443 10;
BA_ "GenSigStartValue" SG_ 528 ActvnOfDoorLiGroup_UB 1;
BA_ "SigGroup" SG_ 528 ActvnOfDoorLiGroupActvnOfDoorAmb "ActvnOfDoorLiGroup";
BA_ "SystemSignalLongSymbol" SG_ 528 ActvnOfDoorLiGroupActvnOfDoorAmb "ActvnOfDoorLiGroupActvnOfDoorAmbLi";
BA_ "SigGroup" SG_ 528 ActvnOfDoorLiGroupActvnOfHndlAnd "ActvnOfDoorLiGroup";
BA_ "SystemSignalLongSymbol" SG_ 528 ActvnOfDoorLiGroupActvnOfHndlAnd "ActvnOfDoorLiGroupActvnOfHndlAndStorgLi";
BA_ "SigGroup" SG_ 528 ActvnOfDoorLiGroupAmbLiInten "ActvnOfDoorLiGroup";
BA_ "GenSigStartValue" SG_ 528 ActvnOfDoorLiGroupAmbLiInten 2;
BA_ "SigGroup" SG_ 528 ActvnOfDoorLiGroupAmbLiRedn "ActvnOfDoorLiGroup";
BA_ "GenSigStartValue" SG_ 528 ChrgrSt_UB 1;
BA_ "GenSigStartValue" SG_ 528 DrvrSeatDispSpplFct_UB 1;
BA_ "SigGroup" SG_ 528 DstToEmpty "DstToEmptyIndcd";
BA_ "GenSigStartValue" SG_ 528 DstToEmptyIndcd_UB 1;
BA_ "SigGroup" SG_ 528 DstUnit "DstToEmptyIndcd";
BA_ "GenSigStartValue" SG_ 528 EngCooltInhbFlow_UB 1;
BA_ "GenSigStartValue" SG_ 528 EngOilPWarn_UB 1;
BA_ "SigGroup" SG_ 528 EngT "EngTGrp";
BA_ "GenSigStartValue" SG_ 528 EngT 50;
BA_ "GenSigStartValue" SG_ 528 EngTGrp_UB 1;
BA_ "SigGroup" SG_ 528 EngTQf "EngTGrp";
BA_ "GenSigStartValue" SG_ 528 EngTQf 3;
BA_ "GenSigStartValue" SG_ 528 HvBattHeatgReq_UB 1;
BA_ "GenSigStartValue" SG_ 528 HvBattHeatrVlvPosn_UB 1;
BA_ "GenSigStartValue" SG_ 528 HvPwrEgyPrio_UB 1;
BA_ "GenSigStartValue" SG_ 528 OnBdChrgrHndlSts_UB 1;
BA_ "GenSigStartValue" SG_ 528 PassSeatSts_UB 1;
BA_ "GenSigStartValue" SG_ 528 SeatDispBtnPsd_UB 1;
BA_ "SigGroup" SG_ 528 SeatDispBtnPsdDrvrSeatDispBtnPsd "SeatDispBtnPsd";
BA_ "SigGroup" SG_ 528 SeatDispBtnPsdPassSeatDispBtnPsd "SeatDispBtnPsd";
BA_ "GenSigStartValue" SG_ 528 SteerWhlHeatgDurgClimaEnad_UB 1;
BA_ "SigGroup" SG_ 544 UkwnCptReqToTelmByte0 "UkwnCptReqToTelm";
BA_ "SigGroup" SG_ 544 UkwnCptReqToTelmByte1 "UkwnCptReqToTelm";
BA_ "SigGroup" SG_ 544 UkwnCptReqToTelmByte2 "UkwnCptReqToTelm";
BA_ "SigGroup" SG_ 544 UkwnCptReqToTelmByte3 "UkwnCptReqToTelm";
BA_ "SigGroup" SG_ 544 UkwnCptReqToTelmByte4 "UkwnCptReqToTelm";
BA_ "SigGroup" SG_ 544 UkwnCptReqToTelmByte5 "UkwnCptReqToTelm";
BA_ "SigGroup" SG_ 544 UkwnCptReqToTelmByte6 "UkwnCptReqToTelm";
BA_ "SigGroup" SG_ 544 UkwnCptReqToTelmByte7 "UkwnCptReqToTelm";
BA_ "GenSigStartValue" SG_ 608 ClimaTmrStsRqrd_UB 1;
BA_ "GenSigStartValue" SG_ 608 DayToSrv_UB 1;
BA_ "GenSigStartValue" SG_ 608 DstTrvld1_UB 1;
BA_ "GenSigStartValue" SG_ 608 EgySave_UB 1;
BA_ "GenSigStartValue" SG_ 608 FuCnsIndcd_UB 1;
BA_ "SigGroup" SG_ 608 FuCnsIndcdUnit "FuCnsIndcd";
BA_ "SigGroup" SG_ 608 FuCnsIndcdVal "FuCnsIndcd";
BA_ "GenSigStartValue" SG_ 608 FuLvlLoIndcn_UB 1;
BA_ "GenSigStartValue" SG_ 608 MassgFctActv_UB 1;
BA_ "SigGroup" SG_ 608 MassgFctActvDrvrMassgFctActv "MassgFctActv";
BA_ "SigGroup" SG_ 608 MassgFctActvPassMassgFctActv "MassgFctActv";
BA_ "GenSigStartValue" SG_ 608 SeatHeatDurgClimaEnad_UB 1;
BA_ "GenSigStartValue" SG_ 608 SrvTrig_UB 1;
BA_ "GenSigStartValue" SG_ 640 ClimaTmr_UB 1;
BA_ "GenSigStartValue" SG_ 640 EngHrToSrv_UB 1;
BA_ "SigGroup" SG_ 640 FuCnsAvg "FuCnsAvgIndcd";
BA_ "GenSigStartValue" SG_ 640 FuCnsAvgIndcd_UB 1;
BA_ "SigGroup" SG_ 640 FuCnsAvgUnit "FuCnsAvgIndcd";
BA_ "GenSigStartValue" SG_ 640 FuCnsAvgUnit 4;
BA_ "GenSigStartValue" SG_ 592 CoolgReqForDispCen_UB 1;
BA_ "GenSigStartValue" SG_ 592 CoolgReqForDrvrDisp_UB 1;
BA_ "GenSigStartValue" SG_ 592 DstToSrv_UB 1;
BA_ "GenSigStartValue" SG_ 592 EngFuCnsFild_UB 1;
BA_ "GenSigStartValue" SG_ 592 FuLvlLoWarn_UB 1;
BA_ "SigGroup" SG_ 592 VehSpdAvg "VehSpdAvgIndcd";
BA_ "GenSigStartValue" SG_ 592 VehSpdAvgIndcd_UB 1;
BA_ "SigGroup" SG_ 592 VehSpdAvgUnit "VehSpdAvgIndcd";
BA_ "GenSigStartValue" SG_ 592 VehSpdAvgUnit 2;
BA_ "GenSigStartValue" SG_ 592 VehSpdIndcdQly_UB 1;
BA_ "GenSigStartValue" SG_ 656 DstTrvld2_UB 1;
BA_ "GenSigStartValue" SG_ 656 DstTrvldHiResl_UB 1;
BA_ "GenSigStartValue" SG_ 656 EngFuCns_UB 1;
BA_ "GenSigStartValue" SG_ 656 SunRoofPosnSts_UB 1;
BA_ "SigGroup" SG_ 624 AbsWarnIndcnReq "BrkAndAbsWarnIndcnReqGroup";
BA_ "GenSigStartValue" SG_ 624 AbsWarnIndcnReq 3;
BA_ "GenSigDataID" SG_ 624 BrkAndAbsWarnIndcnReqChks "0x65";
BA_ "GenSigFuncType" SG_ 624 BrkAndAbsWarnIndcnReqChks 15;
BA_ "SigGroup" SG_ 624 BrkAndAbsWarnIndcnReqChks "BrkAndAbsWarnIndcnReqGroup";
BA_ "GenSigFuncType" SG_ 624 BrkAndAbsWarnIndcnReqCntr 16;
BA_ "SigGroup" SG_ 624 BrkAndAbsWarnIndcnReqCntr "BrkAndAbsWarnIndcnReqGroup";
BA_ "GenSigStartValue" SG_ 624 BrkAndAbsWarnIndcnReqGroup_UB 1;
BA_ "SigGroup" SG_ 624 BrkWarnIndcnReq "BrkAndAbsWarnIndcnReqGroup";
BA_ "GenSigStartValue" SG_ 624 BrkWarnIndcnReq 1;
BA_ "GenSigStartValue" SG_ 624 EngSt1WdSts_UB 1;
BA_ "GenSigStartValue" SG_ 624 FuLvlIndcd_UB 1;
BA_ "SigGroup" SG_ 624 FuLvlIndcdQly "FuLvlIndcd";
BA_ "GenSigStartValue" SG_ 624 FuLvlIndcdQly 1;
BA_ "SigGroup" SG_ 624 FuLvlIndcdVal "FuLvlIndcd";
BA_ "GenSigStartValue" SG_ 624 NetHdActvt_UB 1;
BA_ "SigGroup" SG_ 624 NetHdActvtPrio "NetHdActvt";
BA_ "SigGroup" SG_ 624 NetHdActvtResourceGroup "NetHdActvt";
BA_ "GenSigStartValue" SG_ 624 NotifForEmgyCall_UB 1;
BA_ "GenSigStartValue" SG_ 624 PassSeatDispSpplFct_UB 1;
BA_ "GenSigStartValue" SG_ 624 SteerWhlHeatgOnReq_UB 1;
BA_ "GenSigStartValue" SG_ 768 DrvModReq_UB 1;
BA_ "SigGroup" SG_ 768 EngN "EngNSafe";
BA_ "GenSigDataID" SG_ 768 EngNChks "0x44";
BA_ "GenSigFuncType" SG_ 768 EngNChks 15;
BA_ "SigGroup" SG_ 768 EngNChks "EngNSafe";
BA_ "GenSigFuncType" SG_ 768 EngNCntr 16;
BA_ "SigGroup" SG_ 768 EngNCntr "EngNSafe";
BA_ "GenSigStartValue" SG_ 768 EngNSafe_UB 1;
BA_ "SigGroup" SG_ 768 EngNSafeEngNGrdt "EngNSafe";
BA_ "GenSigStartValue" SG_ 768 FuLvlRawActvSide_UB 1;
BA_ "SigGroup" SG_ 768 FuLvlRawActvSideQly "FuLvlRawActvSide";
BA_ "GenSigStartValue" SG_ 768 FuLvlRawActvSideQly 1;
BA_ "SigGroup" SG_ 768 FuLvlRawActvSideVal "FuLvlRawActvSide";
BA_ "GenSigStartValue" SG_ 784 BkpOfDstTrvld_UB 1;
BA_ "SigGroup" SG_ 784 ClkFmt "IndcnUnit";
BA_ "GenSigStartValue" SG_ 784 ClkFmt 2;
BA_ "SigGroup" SG_ 784 DstLong "IndcnUnit";
BA_ "GenSigStartValue" SG_ 784 DstLong 2;
BA_ "SigGroup" SG_ 784 DstSho "IndcnUnit";
BA_ "GenSigStartValue" SG_ 784 DstSho 3;
BA_ "GenSigStartValue" SG_ 784 FltIndcrTurnRiFrnt_UB 1;
BA_ "GenSigStartValue" SG_ 784 FltIndcrTurnRiRe_UB 1;
BA_ "SigGroup" SG_ 784 FuCnsUnit "IndcnUnit";
BA_ "GenSigStartValue" SG_ 784 FuCnsUnit 4;
BA_ "SigGroup" SG_ 784 IdPenForUnits "IndcnUnit";
BA_ "GenSigStartValue" SG_ 784 IndcnUnit_UB 1;
BA_ "SigGroup" SG_ 784 IndcnUnitDateFmt "IndcnUnit";
BA_ "GenSigStartValue" SG_ 784 IndcnUnitDateFmt 3;
BA_ "SigGroup" SG_ 784 PUnit "IndcnUnit";
BA_ "GenSigStartValue" SG_ 784 PUnit 4;
BA_ "SigGroup" SG_ 784 SpdUnit "IndcnUnit";
BA_ "GenSigStartValue" SG_ 784 SpdUnit 2;
BA_ "SigGroup" SG_ 784 TUnit "IndcnUnit";
BA_ "GenSigStartValue" SG_ 784 TUnit 2;
BA_ "SigGroup" SG_ 784 VolUnit "IndcnUnit";
BA_ "GenSigStartValue" SG_ 784 VolUnit 3;
BA_ "SigGroup" SG_ 464 AmbTIndcd "AmbTIndcdWithUnit";
BA_ "GenSigStartValue" SG_ 464 AmbTIndcd 1000;
BA_ "SigGroup" SG_ 464 AmbTIndcdQf "AmbTIndcdWithUnit";
BA_ "SigGroup" SG_ 464 AmbTIndcdUnit "AmbTIndcdWithUnit";
BA_ "GenSigStartValue" SG_ 464 AmbTIndcdWithUnit_UB 1;
BA_ "GenSigStartValue" SG_ 464 AmbTRaw_UB 1;
BA_ "SigGroup" SG_ 464 AmbTRawQly "AmbTRaw";
BA_ "SigGroup" SG_ 464 AmbTRawVal "AmbTRaw";
BA_ "GenSigStartValue" SG_ 464 AmbTRawVal 2047;
BA_ "GenSigStartValue" SG_ 464 FltOfBeamLoLe_UB 1;
BA_ "GenSigStartValue" SG_ 464 FltOfBrkLiHiMntd_UB 1;
BA_ "GenSigStartValue" SG_ 464 FltOfPlateNr_UB 1;
BA_ "GenSigStartValue" SG_ 464 FltOfPosnReRi_UB 1;
BA_ "GenSigStartValue" SG_ 464 RlyPwrDistbnCmd1WdPreBattSa_0000 1;
BA_ "SystemSignalLongSymbol" SG_ 464 RlyPwrDistbnCmd1WdPreBattSa_0000 "RlyPwrDistbnCmd1WdPreBattSaveCmd_UB";
BA_ "GenSigStartValue" SG_ 464 VehSpdIndcd_UB 1;
BA_ "SigGroup" SG_ 464 VehSpdIndcdUnit "VehSpdIndcd";
BA_ "SigGroup" SG_ 464 VehSpdIndcdVal "VehSpdIndcd";
BA_ "GenSigStartValue" SG_ 464 WipgInfo_UB 1;
BA_ "SigGroup" SG_ 464 WipgInfoWipgSpdInfo "WipgInfo";
BA_ "SigGroup" SG_ 464 WipgInfoWiprActv "WipgInfo";
BA_ "SigGroup" SG_ 464 WipgInfoWiprInWipgAr "WipgInfo";
BA_ "GenSigStartValue" SG_ 848 ClimaStrtTiSts_UB 1;
BA_ "SigGroup" SG_ 848 Day "TiAndDateIndcn";
BA_ "GenSigStartValue" SG_ 848 Day 1;
BA_ "GenSigStartValue" SG_ 848 FltOfPosnReLe_UB 1;
BA_ "SigGroup" SG_ 848 Hr "TiAndDateIndcn";
BA_ "SigGroup" SG_ 848 Mins "TiAndDateIndcn";
BA_ "SigGroup" SG_ 848 Mth "TiAndDateIndcn";
BA_ "GenSigStartValue" SG_ 848 Mth 1;
BA_ "SigGroup" SG_ 848 Sec "TiAndDateIndcn";
BA_ "GenSigStartValue" SG_ 848 TiAndDateIndcn_UB 1;
BA_ "SigGroup" SG_ 848 TiAndDateVld "TiAndDateIndcn";
BA_ "SigGroup" SG_ 848 Yr "TiAndDateIndcn";
BA_ "GenSigStartValue" SG_ 880 CarTiGlb_UB 1;
BA_ "GenSigStartValue" SG_ 880 ClimaCmd_UB 1;
BA_ "GenSigStartValue" SG_ 880 EgyCnsAllwdForClima_UB 1;
BA_ "GenSigStartValue" SG_ 880 FltFogLiRe_UB 1;
BA_ "GenSigStartValue" SG_ 880 FltIndcrTurnLeFrnt_UB 1;
BA_ "GenSigStartValue" SG_ 880 FltLiSideMkrFrnt_UB 1;
BA_ "GenSigStartValue" SG_ 880 FltOfBeamHiLe_UB 1;
BA_ "GenSigStartValue" SG_ 880 FltOfBeamHiRi_UB 1;
BA_ "GenSigStartValue" SG_ 880 FltOfBeamLoRi_UB 1;
BA_ "GenSigStartValue" SG_ 880 FltOfLiPosnFrntLe_UB 1;
BA_ "GenSigStartValue" SG_ 880 PwrSplyErrSts_UB 1;
BA_ "GenSigStartValue" SG_ 880 WshrFldSts_UB 1;
BA_ "GenSigSendType" SG_ 864 VinBlk 3;
BA_ "SigGroup" SG_ 864 VinBlk "Vin";
BA_ "GenSigSendType" SG_ 864 VinPosn1 3;
BA_ "SigGroup" SG_ 864 VinPosn1 "Vin";
BA_ "GenSigSendType" SG_ 864 VinPosn2 3;
BA_ "SigGroup" SG_ 864 VinPosn2 "Vin";
BA_ "GenSigSendType" SG_ 864 VinPosn3 3;
BA_ "SigGroup" SG_ 864 VinPosn3 "Vin";
BA_ "GenSigSendType" SG_ 864 VinPosn4 3;
BA_ "SigGroup" SG_ 864 VinPosn4 "Vin";
BA_ "GenSigSendType" SG_ 864 VinPosn5 3;
BA_ "SigGroup" SG_ 864 VinPosn5 "Vin";
BA_ "GenSigSendType" SG_ 864 VinPosn6 3;
BA_ "SigGroup" SG_ 864 VinPosn6 "Vin";
BA_ "GenSigSendType" SG_ 864 VinPosn7 3;
BA_ "SigGroup" SG_ 864 VinPosn7 "Vin";
BA_ "GenSigStartValue" SG_ 896 AntithftActvnNotif_UB 1;
BA_ "GenSigStartValue" SG_ 896 ClimaPwrAllwd_UB 1;
BA_ "GenSigStartValue" SG_ 896 CurtReDirCmd_UB 1;
BA_ "GenSigStartValue" SG_ 896 FltLiDaytiRunngLe_UB 1;
BA_ "GenSigStartValue" SG_ 896 FltOfBrkLiLe_UB 1;
BA_ "GenSigStartValue" SG_ 896 FltOfLiDaytiRunngRi_UB 1;
BA_ "GenSigStartValue" SG_ 896 FltOfLiPosnFrntRi_UB 1;
BA_ "GenSigStartValue" SG_ 896 IndcrPatCmd1WdCmd_UB 1;
BA_ "SigGroup" SG_ 896 IndcrPatCmd1WdTiOff "IndcrPatCmd1WdCmd";
BA_ "SigGroup" SG_ 896 IndcrPatCmd1WdTiOn "IndcrPatCmd1WdCmd";
BA_ "GenSigStartValue" SG_ 896 StrtRemSts1WdStrtRemSts_UB 1;
BA_ "GenSigStartValue" SG_ 896 TrLockSts_UB 1;
BA_ "GenSigStartValue" SG_ 816 FltIndcrTurnLeRe_UB 1;
BA_ "GenSigStartValue" SG_ 816 FltOfBrkLiRi_UB 1;
BA_ "GenSigStartValue" SG_ 816 FltOfFogLiFrnt_UB 1;
BA_ "GenSigStartValue" SG_ 816 ProfPenSts1_UB 1;
BA_ "SigGroup" SG_ 816 TirePFrntLe "TirePMonData";
BA_ "SigGroup" SG_ 816 TirePFrntRi "TirePMonData";
BA_ "GenSigStartValue" SG_ 816 TirePMonData_UB 1;
BA_ "SigGroup" SG_ 816 TirePMonSts "TirePMonData";
BA_ "SigGroup" SG_ 816 TirePReLe "TirePMonData";
BA_ "SigGroup" SG_ 816 TirePReRi "TirePMonData";
BA_ "GenSigStartValue" SG_ 816 VehBattUGroup_UB 1;
BA_ "SigGroup" SG_ 816 VehBattUSysU "VehBattUGroup";
BA_ "SigGroup" SG_ 816 VehBattUSysUQf "VehBattUGroup";
BA_ "SigGroup" SG_ 832 VehCfgPrmBlk "VehCfgPrm";
BA_ "GenSigSendType" SG_ 832 VehCfgPrmBlk 3;
BA_ "SigGroup" SG_ 832 VehCfgPrmVal1 "VehCfgPrm";
BA_ "GenSigSendType" SG_ 832 VehCfgPrmVal1 3;
BA_ "SigGroup" SG_ 832 VehCfgPrmVal2 "VehCfgPrm";
BA_ "GenSigSendType" SG_ 832 VehCfgPrmVal2 3;
BA_ "SigGroup" SG_ 832 VehCfgPrmVal3 "VehCfgPrm";
BA_ "GenSigSendType" SG_ 832 VehCfgPrmVal3 3;
BA_ "SigGroup" SG_ 832 VehCfgPrmVal4 "VehCfgPrm";
BA_ "GenSigSendType" SG_ 832 VehCfgPrmVal4 3;
BA_ "SigGroup" SG_ 832 VehCfgPrmVal5 "VehCfgPrm";
BA_ "GenSigSendType" SG_ 832 VehCfgPrmVal5 3;
BA_ "SigGroup" SG_ 832 VehCfgPrmVal6 "VehCfgPrm";
BA_ "GenSigSendType" SG_ 832 VehCfgPrmVal6 3;
BA_ "SigGroup" SG_ 832 VehCfgPrmVal7 "VehCfgPrm";
BA_ "GenSigSendType" SG_ 832 VehCfgPrmVal7 3;
BA_ "SigGroup" SG_ 512 CmptmtTFrnt "CmptmtTFrntGroup";
BA_ "GenSigStartValue" SG_ 512 CmptmtTFrnt 600;
BA_ "GenSigStartValue" SG_ 512 CmptmtTFrntGroup_UB 1;
BA_ "SigGroup" SG_ 512 CmptmtTFrntQf "CmptmtTFrntGroup";
BA_ "GenSigStartValue" SG_ 512 DispHvBattLvlOfChrg_UB 1;
BA_ "SigGroup" SG_ 512 FanForCmptmtTRunng "CmptmtTFrntGroup";
BA_ "GenSigStartValue" SG_ 50 CryptoDoorDrvrLockCmd_UB 1;
BA_ "SigGroup" SG_ 50 CryptoDoorDrvrLockCmdAuthentCod1 "CryptoDoorDrvrLockCmd";
BA_ "SigGroup" SG_ 50 CryptoDoorDrvrLockCmdAuthentCod2 "CryptoDoorDrvrLockCmd";
BA_ "SigGroup" SG_ 50 CryptoDoorDrvrLockCmdCntr "CryptoDoorDrvrLockCmd";
BA_ "SigGroup" SG_ 50 CryptoDoorDrvrLockCmdLockActvn "CryptoDoorDrvrLockCmd";
BA_ "GenSigStartValue" SG_ 56 CryptoDoorDrvrLockReCmd_UB 1;
BA_ "SigGroup" SG_ 56 CryptoDoorDrvrLockReCmdAuthentCo "CryptoDoorDrvrLockReCmd";
BA_ "SystemSignalLongSymbol" SG_ 56 CryptoDoorDrvrLockReCmdAuthentCo "CryptoDoorDrvrLockReCmdAuthentCod1";
BA_ "SigGroup" SG_ 56 CryptoDoorDrvrLockReCmdAuth_0000 "CryptoDoorDrvrLockReCmd";
BA_ "SystemSignalLongSymbol" SG_ 56 CryptoDoorDrvrLockReCmdAuth_0000 "CryptoDoorDrvrLockReCmdAuthentCod2";
BA_ "SigGroup" SG_ 56 CryptoDoorDrvrLockReCmdCntr "CryptoDoorDrvrLockReCmd";
BA_ "SigGroup" SG_ 56 CryptoDoorDrvrLockReCmdLockActvn "CryptoDoorDrvrLockReCmd";
BA_ "GenSigStartValue" SG_ 56 TaxiLockCmd_UB 1;
BA_ "GenSigStartValue" SG_ 53 CryptoDoorPassLockCmd_UB 1;
BA_ "SigGroup" SG_ 53 CryptoDoorPassLockCmdAuthentCod1 "CryptoDoorPassLockCmd";
BA_ "SigGroup" SG_ 53 CryptoDoorPassLockCmdAuthentCod2 "CryptoDoorPassLockCmd";
BA_ "SigGroup" SG_ 53 CryptoDoorPassLockCmdCntr "CryptoDoorPassLockCmd";
BA_ "SigGroup" SG_ 53 CryptoDoorPassLockCmdLockActvn "CryptoDoorPassLockCmd";
BA_ "GenSigStartValue" SG_ 58 CryptoDoorPassLockReCmd_UB 1;
BA_ "SigGroup" SG_ 58 CryptoDoorPassLockReCmdAuthentCo "CryptoDoorPassLockReCmd";
BA_ "SystemSignalLongSymbol" SG_ 58 CryptoDoorPassLockReCmdAuthentCo "CryptoDoorPassLockReCmdAuthentCod1";
BA_ "SigGroup" SG_ 58 CryptoDoorPassLockReCmdAuth_0000 "CryptoDoorPassLockReCmd";
BA_ "SystemSignalLongSymbol" SG_ 58 CryptoDoorPassLockReCmdAuth_0000 "CryptoDoorPassLockReCmdAuthentCod2";
BA_ "SigGroup" SG_ 58 CryptoDoorPassLockReCmdCntr "CryptoDoorPassLockReCmd";
BA_ "SigGroup" SG_ 58 CryptoDoorPassLockReCmdLockActvn "CryptoDoorPassLockReCmd";
BA_ "GenSigStartValue" SG_ 58 DstEstimdToEmptyForDrvgElec_UB 1;
BA_ "GenSigStartValue" SG_ 567 ClngRqrdFromHmi_UB 1;
BA_ "GenSigStartValue" SG_ 567 SecuAlrmMgrToTelmIni_UB 1;
BA_ "SigGroup" SG_ 567 SecuAlrmMgrToTelmIniMsgAuthentCo "SecuAlrmMgrToTelmIni";
BA_ "SystemSignalLongSymbol" SG_ 567 SecuAlrmMgrToTelmIniMsgAuthentCo "SecuAlrmMgrToTelmIniMsgAuthentCod1";
BA_ "SigGroup" SG_ 567 SecuAlrmMgrToTelmIniMsgAuth_0000 "SecuAlrmMgrToTelmIni";
BA_ "SystemSignalLongSymbol" SG_ 567 SecuAlrmMgrToTelmIniMsgAuth_0000 "SecuAlrmMgrToTelmIniMsgAuthentCod2";
BA_ "SigGroup" SG_ 567 SecuAlrmMgrToTelmIniSecuAlrmMagr "SecuAlrmMgrToTelmIni";
BA_ "SystemSignalLongSymbol" SG_ 567 SecuAlrmMgrToTelmIniSecuAlrmMagr "SecuAlrmMgrToTelmIniSecuAlrmMagrToTelmIniMsgAuthentCodMsgTyp";
BA_ "SigGroup" SG_ 567 SecuAlrmMgrToTelmIniSecuIniNrRnd "SecuAlrmMgrToTelmIni";
BA_ "SystemSignalLongSymbol" SG_ 567 SecuAlrmMgrToTelmIniSecuIniNrRnd "SecuAlrmMgrToTelmIniSecuIniNrRnd1";
BA_ "SigGroup" SG_ 567 SecuAlrmMgrToTelmIniSecuIni_0000 "SecuAlrmMgrToTelmIni";
BA_ "SystemSignalLongSymbol" SG_ 567 SecuAlrmMgrToTelmIniSecuIni_0000 "SecuAlrmMgrToTelmIniSecuIniNrRnd2";
BA_ "SigGroup" SG_ 567 SecuAlrmMgrToTelmIniSecuIni_0001 "SecuAlrmMgrToTelmIni";
BA_ "SystemSignalLongSymbol" SG_ 567 SecuAlrmMgrToTelmIniSecuIni_0001 "SecuAlrmMgrToTelmIniSecuIniNrRnd3";
BA_ "GenSigStartValue" SG_ 533 AirClngReq_UB 1;
BA_ "GenSigStartValue" SG_ 533 CryptoTelmLockgCenReqInin_UB 1;
BA_ "GenSigStartValue" SG_ 533 HmiSeatClimaExtd_UB 1;
BA_ "SigGroup" SG_ 533 HmiSeatClimaExtdHmiSeatVentnForR "HmiSeatClimaExtd";
BA_ "SystemSignalLongSymbol" SG_ 533 HmiSeatClimaExtdHmiSeatVentnForR "HmiSeatClimaExtdHmiSeatVentnForRowSecLe";
BA_ "SigGroup" SG_ 533 HmiSeatClimaExtdHmiSeatVent_0000 "HmiSeatClimaExtd";
BA_ "SystemSignalLongSymbol" SG_ 533 HmiSeatClimaExtdHmiSeatVent_0000 "HmiSeatClimaExtdHmiSeatVentnForRowSecRi";
BA_ "GenSigStartValue" SG_ 566 SecuAntithftActvnNotif_UB 1;
BA_ "SigGroup" SG_ 566 SecuAntithftActvnNotifSecuAntith "SecuAntithftActvnNotif";
BA_ "SystemSignalLongSymbol" SG_ 566 SecuAntithftActvnNotifSecuAntith "SecuAntithftActvnNotifSecuAntithftActvnNotif";
BA_ "SigGroup" SG_ 566 SecuAntithftActvnNotifSecuA_0000 "SecuAntithftActvnNotif";
BA_ "SystemSignalLongSymbol" SG_ 566 SecuAntithftActvnNotifSecuA_0000 "SecuAntithftActvnNotifSecuAntithftActvnNotifCntr";
BA_ "SigGroup" SG_ 566 SecuAntithftActvnNotifSecuA_0001 "SecuAntithftActvnNotif";
BA_ "SystemSignalLongSymbol" SG_ 566 SecuAntithftActvnNotifSecuA_0001 "SecuAntithftActvnNotifSecuAntithftActvnNotifMsgAuthentCod";
BA_ "GenSigStartValue" SG_ 1407 BodyCntrForMissCom_UB 1;
BA_ "GenSigStartValue" SG_ 1407 MstCfgIDBodyCAN 4105;
BA_ "GenSigStartValue" SG_ 1407 MstCfgIDBodyCAN_UB 1;
BA_ "SigGroup" SG_ 1452 TirePMonForDevDataByte0 "TirePMonForDevData";
BA_ "GenSigSendType" SG_ 1452 TirePMonForDevDataByte0 3;
BA_ "SigGroup" SG_ 1452 TirePMonForDevDataByte1 "TirePMonForDevData";
BA_ "GenSigSendType" SG_ 1452 TirePMonForDevDataByte1 3;
BA_ "SigGroup" SG_ 1452 TirePMonForDevDataByte2 "TirePMonForDevData";
BA_ "GenSigSendType" SG_ 1452 TirePMonForDevDataByte2 3;
BA_ "SigGroup" SG_ 1452 TirePMonForDevDataByte3 "TirePMonForDevData";
BA_ "GenSigSendType" SG_ 1452 TirePMonForDevDataByte3 3;
BA_ "SigGroup" SG_ 1452 TirePMonForDevDataByte4 "TirePMonForDevData";
BA_ "GenSigSendType" SG_ 1452 TirePMonForDevDataByte4 3;
BA_ "SigGroup" SG_ 1452 TirePMonForDevDataByte5 "TirePMonForDevData";
BA_ "GenSigSendType" SG_ 1452 TirePMonForDevDataByte5 3;
BA_ "SigGroup" SG_ 1452 TirePMonForDevDataByte6 "TirePMonForDevData";
BA_ "GenSigSendType" SG_ 1452 TirePMonForDevDataByte6 3;
BA_ "SigGroup" SG_ 1452 TirePMonForDevDataByte7 "TirePMonForDevData";
BA_ "GenSigSendType" SG_ 1452 TirePMonForDevDataByte7 3;
BA_ "GenSigStartValue" SG_ 48 ChdLockgProtnFailrStsToHmi 2;
BA_ "GenSigStartValue" SG_ 48 ChdLockgProtnFailrStsToHmi_UB 1;
BA_ "GenSigStartValue" SG_ 48 ChdLockgProtnStsToHmi_UB 1;
BA_ "GenSigStartValue" SG_ 48 ChdProtnCmd 1;
BA_ "GenSigStartValue" SG_ 48 ChdProtnCmd_UB 1;
BA_ "GenSigStartValue" SG_ 48 CrashUnlckFailrStsAtDrvrRe_UB 1;
BA_ "GenSigStartValue" SG_ 48 DoorBtnPsdAtDrvr_UB 1;
BA_ "GenSigStartValue" SG_ 48 DoorDrvrLockReSts_UB 1;
BA_ "GenSigStartValue" SG_ 48 DoorDrvrLockSts_UB 1;
BA_ "GenSigStartValue" SG_ 48 DoorDrvrSwtIntrLockgReq_UB 1;
BA_ "GenSigStartValue" SG_ 48 DoorDrvrSwtLockgReSts_UB 1;
BA_ "GenSigStartValue" SG_ 48 LcmaLedStsDrvrSide_UB 1;
BA_ "SigGroup" SG_ 48 MemBtn1 "MemBtnPsd";
BA_ "SigGroup" SG_ 48 MemBtn2 "MemBtnPsd";
BA_ "SigGroup" SG_ 48 MemBtn3 "MemBtnPsd";
BA_ "SigGroup" SG_ 48 MemBtnM "MemBtnPsd";
BA_ "GenSigStartValue" SG_ 48 MemBtnPsd_UB 1;
BA_ "GenSigStartValue" SG_ 48 MirrAtDrvrInMovmt_UB 1;
BA_ "GenSigStartValue" SG_ 48 MirrBtnPsdAtDrvr_UB 1;
BA_ "SigGroup" SG_ 48 MirrCmdAtPassAdj "MirrCmdAtPassGroup";
BA_ "SigGroup" SG_ 48 MirrCmdAtPassDwn "MirrCmdAtPassGroup";
BA_ "SigGroup" SG_ 48 MirrCmdAtPassFold "MirrCmdAtPassGroup";
BA_ "GenSigStartValue" SG_ 48 MirrCmdAtPassGroup_UB 1;
BA_ "GenSigStartValue" SG_ 48 MirrFoldStsAtDrvr_UB 1;
BA_ "GenSigStartValue" SG_ 48 WinPosnStsAtDrvrRe_UB 1;
BA_ "GenSigStartValue" SG_ 48 WinSwtReqToPass_UB 1;
BA_ "GenSigStartValue" SG_ 48 WinSwtReqToPassRe_UB 1;
BA_ "GenSigStartValue" SG_ 480 ActvnOfDoorSwtIllmn_UB 1;
BA_ "SigGroup" SG_ 480 AmbTQlyAtDrvrSide "AmbTRawAtDrvrSide";
BA_ "GenSigStartValue" SG_ 480 AmbTRawAtDrvrSide_UB 1;
BA_ "SigGroup" SG_ 480 AmbTValAtDrvrSide "AmbTRawAtDrvrSide";
BA_ "GenSigStartValue" SG_ 480 AmbTValAtDrvrSide 700;
BA_ "GenSigStartValue" SG_ 480 ChdWinProtnStsAtDrvrRe_UB 1;
BA_ "GenSigStartValue" SG_ 480 CrashUnlckFailrStsAtDrvr_UB 1;
BA_ "GenSigStartValue" SG_ 480 FltOfPuddleLiDrvr_UB 1;
BA_ "GenSigStartValue" SG_ 480 LiDrvrFltIndcrTurn_UB 1;
BA_ "GenSigStartValue" SG_ 480 MirrDefrstAtDrvSts_UB 1;
BA_ "GenSigStartValue" SG_ 480 MirrDwnStsAtDrvr_UB 1;
BA_ "GenSigStartValue" SG_ 480 WinPosnStsDrv_UB 1;
BA_ "GenSigStartValue" SG_ 304 CryptoDoorDrvrLockCmdInin_UB 1;
BA_ "SigGroup" SG_ 304 CryptoDoorDrvrLockCmdIninCmdInin "CryptoDoorDrvrLockCmdInin";
BA_ "SystemSignalLongSymbol" SG_ 304 CryptoDoorDrvrLockCmdIninCmdInin "CryptoDoorDrvrLockCmdIninCmdInin1";
BA_ "SigGroup" SG_ 304 CryptoDoorDrvrLockCmdIninCm_0000 "CryptoDoorDrvrLockCmdInin";
BA_ "SystemSignalLongSymbol" SG_ 304 CryptoDoorDrvrLockCmdIninCm_0000 "CryptoDoorDrvrLockCmdIninCmdInin2";
BA_ "SigGroup" SG_ 304 CryptoDoorDrvrLockCmdIninCm_0001 "CryptoDoorDrvrLockCmdInin";
BA_ "SystemSignalLongSymbol" SG_ 304 CryptoDoorDrvrLockCmdIninCm_0001 "CryptoDoorDrvrLockCmdIninCmdInin3";
BA_ "GenSigStartValue" SG_ 304 CryptoDoorDrvrLockReCmdInin_UB 1;
BA_ "SigGroup" SG_ 304 CryptoDoorDrvrLockReCmdIninCmdIn "CryptoDoorDrvrLockReCmdInin";
BA_ "SystemSignalLongSymbol" SG_ 304 CryptoDoorDrvrLockReCmdIninCmdIn "CryptoDoorDrvrLockReCmdIninCmdInin1";
BA_ "SigGroup" SG_ 304 CryptoDoorDrvrLockReCmdInin_0000 "CryptoDoorDrvrLockReCmdInin";
BA_ "SystemSignalLongSymbol" SG_ 304 CryptoDoorDrvrLockReCmdInin_0000 "CryptoDoorDrvrLockReCmdIninCmdInin2";
BA_ "SigGroup" SG_ 304 CryptoDoorDrvrLockReCmdInin_0001 "CryptoDoorDrvrLockReCmdInin";
BA_ "SystemSignalLongSymbol" SG_ 304 CryptoDoorDrvrLockReCmdInin_0001 "CryptoDoorDrvrLockReCmdIninCmdInin3";
BA_ "SigGroup" SG_ 1427 DevRespAtDrvrDoorByte0 "DevRespAtDrvrDoor";
BA_ "GenSigSendType" SG_ 1427 DevRespAtDrvrDoorByte0 3;
BA_ "SigGroup" SG_ 1427 DevRespAtDrvrDoorByte1 "DevRespAtDrvrDoor";
BA_ "GenSigSendType" SG_ 1427 DevRespAtDrvrDoorByte1 3;
BA_ "SigGroup" SG_ 1427 DevRespAtDrvrDoorByte2 "DevRespAtDrvrDoor";
BA_ "GenSigSendType" SG_ 1427 DevRespAtDrvrDoorByte2 3;
BA_ "SigGroup" SG_ 1427 DevRespAtDrvrDoorByte3 "DevRespAtDrvrDoor";
BA_ "GenSigSendType" SG_ 1427 DevRespAtDrvrDoorByte3 3;
BA_ "SigGroup" SG_ 1427 DevRespAtDrvrDoorByte4 "DevRespAtDrvrDoor";
BA_ "GenSigSendType" SG_ 1427 DevRespAtDrvrDoorByte4 3;
BA_ "SigGroup" SG_ 1427 DevRespAtDrvrDoorByte5 "DevRespAtDrvrDoor";
BA_ "GenSigSendType" SG_ 1427 DevRespAtDrvrDoorByte5 3;
BA_ "SigGroup" SG_ 1427 DevRespAtDrvrDoorByte6 "DevRespAtDrvrDoor";
BA_ "GenSigSendType" SG_ 1427 DevRespAtDrvrDoorByte6 3;
BA_ "SigGroup" SG_ 1427 DevRespAtDrvrDoorByte7 "DevRespAtDrvrDoor";
BA_ "GenSigSendType" SG_ 1427 DevRespAtDrvrDoorByte7 3;
BA_ "SigGroup" SG_ 1430 DevRespAtDrvrDoorReByte0 "DevRespAtDrvrDoorRe";
BA_ "GenSigSendType" SG_ 1430 DevRespAtDrvrDoorReByte0 3;
BA_ "SigGroup" SG_ 1430 DevRespAtDrvrDoorReByte1 "DevRespAtDrvrDoorRe";
BA_ "GenSigSendType" SG_ 1430 DevRespAtDrvrDoorReByte1 3;
BA_ "SigGroup" SG_ 1430 DevRespAtDrvrDoorReByte2 "DevRespAtDrvrDoorRe";
BA_ "GenSigSendType" SG_ 1430 DevRespAtDrvrDoorReByte2 3;
BA_ "SigGroup" SG_ 1430 DevRespAtDrvrDoorReByte3 "DevRespAtDrvrDoorRe";
BA_ "GenSigSendType" SG_ 1430 DevRespAtDrvrDoorReByte3 3;
BA_ "SigGroup" SG_ 1430 DevRespAtDrvrDoorReByte4 "DevRespAtDrvrDoorRe";
BA_ "GenSigSendType" SG_ 1430 DevRespAtDrvrDoorReByte4 3;
BA_ "SigGroup" SG_ 1430 DevRespAtDrvrDoorReByte5 "DevRespAtDrvrDoorRe";
BA_ "GenSigSendType" SG_ 1430 DevRespAtDrvrDoorReByte5 3;
BA_ "SigGroup" SG_ 1430 DevRespAtDrvrDoorReByte6 "DevRespAtDrvrDoorRe";
BA_ "GenSigSendType" SG_ 1430 DevRespAtDrvrDoorReByte6 3;
BA_ "SigGroup" SG_ 1430 DevRespAtDrvrDoorReByte7 "DevRespAtDrvrDoorRe";
BA_ "GenSigSendType" SG_ 1430 DevRespAtDrvrDoorReByte7 3;
BA_ "SigGroup" SG_ 1425 DevTx1AtDrvrDoorByte0 "DevTx1AtDrvrDoor";
BA_ "GenSigSendType" SG_ 1425 DevTx1AtDrvrDoorByte0 3;
BA_ "SigGroup" SG_ 1425 DevTx1AtDrvrDoorByte1 "DevTx1AtDrvrDoor";
BA_ "GenSigSendType" SG_ 1425 DevTx1AtDrvrDoorByte1 3;
BA_ "SigGroup" SG_ 1425 DevTx1AtDrvrDoorByte2 "DevTx1AtDrvrDoor";
BA_ "GenSigSendType" SG_ 1425 DevTx1AtDrvrDoorByte2 3;
BA_ "SigGroup" SG_ 1425 DevTx1AtDrvrDoorByte3 "DevTx1AtDrvrDoor";
BA_ "GenSigSendType" SG_ 1425 DevTx1AtDrvrDoorByte3 3;
BA_ "SigGroup" SG_ 1425 DevTx1AtDrvrDoorByte4 "DevTx1AtDrvrDoor";
BA_ "GenSigSendType" SG_ 1425 DevTx1AtDrvrDoorByte4 3;
BA_ "SigGroup" SG_ 1425 DevTx1AtDrvrDoorByte5 "DevTx1AtDrvrDoor";
BA_ "GenSigSendType" SG_ 1425 DevTx1AtDrvrDoorByte5 3;
BA_ "SigGroup" SG_ 1425 DevTx1AtDrvrDoorByte6 "DevTx1AtDrvrDoor";
BA_ "GenSigSendType" SG_ 1425 DevTx1AtDrvrDoorByte6 3;
BA_ "SigGroup" SG_ 1425 DevTx1AtDrvrDoorByte7 "DevTx1AtDrvrDoor";
BA_ "GenSigSendType" SG_ 1425 DevTx1AtDrvrDoorByte7 3;
BA_ "SigGroup" SG_ 1428 DevTx1AtDrvrDoorReByte0 "DevTx1AtDrvrDoorRe";
BA_ "GenSigSendType" SG_ 1428 DevTx1AtDrvrDoorReByte0 3;
BA_ "SigGroup" SG_ 1428 DevTx1AtDrvrDoorReByte1 "DevTx1AtDrvrDoorRe";
BA_ "GenSigSendType" SG_ 1428 DevTx1AtDrvrDoorReByte1 3;
BA_ "SigGroup" SG_ 1428 DevTx1AtDrvrDoorReByte2 "DevTx1AtDrvrDoorRe";
BA_ "GenSigSendType" SG_ 1428 DevTx1AtDrvrDoorReByte2 3;
BA_ "SigGroup" SG_ 1428 DevTx1AtDrvrDoorReByte3 "DevTx1AtDrvrDoorRe";
BA_ "GenSigSendType" SG_ 1428 DevTx1AtDrvrDoorReByte3 3;
BA_ "SigGroup" SG_ 1428 DevTx1AtDrvrDoorReByte4 "DevTx1AtDrvrDoorRe";
BA_ "GenSigSendType" SG_ 1428 DevTx1AtDrvrDoorReByte4 3;
BA_ "SigGroup" SG_ 1428 DevTx1AtDrvrDoorReByte5 "DevTx1AtDrvrDoorRe";
BA_ "GenSigSendType" SG_ 1428 DevTx1AtDrvrDoorReByte5 3;
BA_ "SigGroup" SG_ 1428 DevTx1AtDrvrDoorReByte6 "DevTx1AtDrvrDoorRe";
BA_ "GenSigSendType" SG_ 1428 DevTx1AtDrvrDoorReByte6 3;
BA_ "SigGroup" SG_ 1428 DevTx1AtDrvrDoorReByte7 "DevTx1AtDrvrDoorRe";
BA_ "GenSigSendType" SG_ 1428 DevTx1AtDrvrDoorReByte7 3;
BA_ "SigGroup" SG_ 1426 DevTx2AtDrvrDoorByte0 "DevTx2AtDrvrDoor";
BA_ "GenSigSendType" SG_ 1426 DevTx2AtDrvrDoorByte0 3;
BA_ "SigGroup" SG_ 1426 DevTx2AtDrvrDoorByte1 "DevTx2AtDrvrDoor";
BA_ "GenSigSendType" SG_ 1426 DevTx2AtDrvrDoorByte1 3;
BA_ "SigGroup" SG_ 1426 DevTx2AtDrvrDoorByte2 "DevTx2AtDrvrDoor";
BA_ "GenSigSendType" SG_ 1426 DevTx2AtDrvrDoorByte2 3;
BA_ "SigGroup" SG_ 1426 DevTx2AtDrvrDoorByte3 "DevTx2AtDrvrDoor";
BA_ "GenSigSendType" SG_ 1426 DevTx2AtDrvrDoorByte3 3;
BA_ "SigGroup" SG_ 1426 DevTx2AtDrvrDoorByte4 "DevTx2AtDrvrDoor";
BA_ "GenSigSendType" SG_ 1426 DevTx2AtDrvrDoorByte4 3;
BA_ "SigGroup" SG_ 1426 DevTx2AtDrvrDoorByte5 "DevTx2AtDrvrDoor";
BA_ "GenSigSendType" SG_ 1426 DevTx2AtDrvrDoorByte5 3;
BA_ "SigGroup" SG_ 1426 DevTx2AtDrvrDoorByte6 "DevTx2AtDrvrDoor";
BA_ "GenSigSendType" SG_ 1426 DevTx2AtDrvrDoorByte6 3;
BA_ "SigGroup" SG_ 1426 DevTx2AtDrvrDoorByte7 "DevTx2AtDrvrDoor";
BA_ "GenSigSendType" SG_ 1426 DevTx2AtDrvrDoorByte7 3;
BA_ "SigGroup" SG_ 1429 DevTx2AtDrvrDoorReByte0 "DevTx2AtDrvrDoorRe";
BA_ "GenSigSendType" SG_ 1429 DevTx2AtDrvrDoorReByte0 3;
BA_ "SigGroup" SG_ 1429 DevTx2AtDrvrDoorReByte1 "DevTx2AtDrvrDoorRe";
BA_ "GenSigSendType" SG_ 1429 DevTx2AtDrvrDoorReByte1 3;
BA_ "SigGroup" SG_ 1429 DevTx2AtDrvrDoorReByte2 "DevTx2AtDrvrDoorRe";
BA_ "GenSigSendType" SG_ 1429 DevTx2AtDrvrDoorReByte2 3;
BA_ "SigGroup" SG_ 1429 DevTx2AtDrvrDoorReByte3 "DevTx2AtDrvrDoorRe";
BA_ "GenSigSendType" SG_ 1429 DevTx2AtDrvrDoorReByte3 3;
BA_ "SigGroup" SG_ 1429 DevTx2AtDrvrDoorReByte4 "DevTx2AtDrvrDoorRe";
BA_ "GenSigSendType" SG_ 1429 DevTx2AtDrvrDoorReByte4 3;
BA_ "SigGroup" SG_ 1429 DevTx2AtDrvrDoorReByte5 "DevTx2AtDrvrDoorRe";
BA_ "GenSigSendType" SG_ 1429 DevTx2AtDrvrDoorReByte5 3;
BA_ "SigGroup" SG_ 1429 DevTx2AtDrvrDoorReByte6 "DevTx2AtDrvrDoorRe";
BA_ "GenSigSendType" SG_ 1429 DevTx2AtDrvrDoorReByte6 3;
BA_ "SigGroup" SG_ 1429 DevTx2AtDrvrDoorReByte7 "DevTx2AtDrvrDoorRe";
BA_ "GenSigSendType" SG_ 1429 DevTx2AtDrvrDoorReByte7 3;
BA_ "SigGroup" SG_ 1488 EndOfLineSigCtrlrByte0 "EndOfLineSigCtrlr";
BA_ "GenSigSendType" SG_ 1488 EndOfLineSigCtrlrByte0 3;
BA_ "SigGroup" SG_ 1488 EndOfLineSigCtrlrByte1 "EndOfLineSigCtrlr";
BA_ "GenSigSendType" SG_ 1488 EndOfLineSigCtrlrByte1 3;
BA_ "SigGroup" SG_ 1488 EndOfLineSigCtrlrByte2 "EndOfLineSigCtrlr";
BA_ "GenSigSendType" SG_ 1488 EndOfLineSigCtrlrByte2 3;
BA_ "SigGroup" SG_ 1488 EndOfLineSigCtrlrByte3 "EndOfLineSigCtrlr";
BA_ "GenSigSendType" SG_ 1488 EndOfLineSigCtrlrByte3 3;
BA_ "SigGroup" SG_ 1488 EndOfLineSigCtrlrByte4 "EndOfLineSigCtrlr";
BA_ "GenSigSendType" SG_ 1488 EndOfLineSigCtrlrByte4 3;
BA_ "SigGroup" SG_ 1488 EndOfLineSigCtrlrByte5 "EndOfLineSigCtrlr";
BA_ "GenSigSendType" SG_ 1488 EndOfLineSigCtrlrByte5 3;
BA_ "SigGroup" SG_ 1488 EndOfLineSigCtrlrByte6 "EndOfLineSigCtrlr";
BA_ "GenSigSendType" SG_ 1488 EndOfLineSigCtrlrByte6 3;
BA_ "SigGroup" SG_ 1488 EndOfLineSigCtrlrByte7 "EndOfLineSigCtrlr";
BA_ "GenSigSendType" SG_ 1488 EndOfLineSigCtrlrByte7 3;
BA_ "GenSigSendType" SG_ 1489 EndOfLineSigCtrlrInp 3;
BA_ "GenSigSendType" SG_ 1489 EndOfLineSigCtrlrInp1 3;
BA_ "SigGroup" SG_ 1441 DevReqToDrvrDoorByte0 "DevReqToDrvrDoor";
BA_ "GenSigSendType" SG_ 1441 DevReqToDrvrDoorByte0 3;
BA_ "SigGroup" SG_ 1441 DevReqToDrvrDoorByte1 "DevReqToDrvrDoor";
BA_ "GenSigSendType" SG_ 1441 DevReqToDrvrDoorByte1 3;
BA_ "SigGroup" SG_ 1441 DevReqToDrvrDoorByte2 "DevReqToDrvrDoor";
BA_ "GenSigSendType" SG_ 1441 DevReqToDrvrDoorByte2 3;
BA_ "SigGroup" SG_ 1441 DevReqToDrvrDoorByte3 "DevReqToDrvrDoor";
BA_ "GenSigSendType" SG_ 1441 DevReqToDrvrDoorByte3 3;
BA_ "SigGroup" SG_ 1441 DevReqToDrvrDoorByte4 "DevReqToDrvrDoor";
BA_ "GenSigSendType" SG_ 1441 DevReqToDrvrDoorByte4 3;
BA_ "SigGroup" SG_ 1441 DevReqToDrvrDoorByte5 "DevReqToDrvrDoor";
BA_ "GenSigSendType" SG_ 1441 DevReqToDrvrDoorByte5 3;
BA_ "SigGroup" SG_ 1441 DevReqToDrvrDoorByte6 "DevReqToDrvrDoor";
BA_ "GenSigSendType" SG_ 1441 DevReqToDrvrDoorByte6 3;
BA_ "SigGroup" SG_ 1441 DevReqToDrvrDoorByte7 "DevReqToDrvrDoor";
BA_ "GenSigSendType" SG_ 1441 DevReqToDrvrDoorByte7 3;
BA_ "SigGroup" SG_ 1440 DevReqToDrvrDoorReByte0 "DevReqToDrvrDoorRe";
BA_ "GenSigSendType" SG_ 1440 DevReqToDrvrDoorReByte0 3;
BA_ "SigGroup" SG_ 1440 DevReqToDrvrDoorReByte1 "DevReqToDrvrDoorRe";
BA_ "GenSigSendType" SG_ 1440 DevReqToDrvrDoorReByte1 3;
BA_ "SigGroup" SG_ 1440 DevReqToDrvrDoorReByte2 "DevReqToDrvrDoorRe";
BA_ "GenSigSendType" SG_ 1440 DevReqToDrvrDoorReByte2 3;
BA_ "SigGroup" SG_ 1440 DevReqToDrvrDoorReByte3 "DevReqToDrvrDoorRe";
BA_ "GenSigSendType" SG_ 1440 DevReqToDrvrDoorReByte3 3;
BA_ "SigGroup" SG_ 1440 DevReqToDrvrDoorReByte4 "DevReqToDrvrDoorRe";
BA_ "GenSigSendType" SG_ 1440 DevReqToDrvrDoorReByte4 3;
BA_ "SigGroup" SG_ 1440 DevReqToDrvrDoorReByte5 "DevReqToDrvrDoorRe";
BA_ "GenSigSendType" SG_ 1440 DevReqToDrvrDoorReByte5 3;
BA_ "SigGroup" SG_ 1440 DevReqToDrvrDoorReByte6 "DevReqToDrvrDoorRe";
BA_ "GenSigSendType" SG_ 1440 DevReqToDrvrDoorReByte6 3;
BA_ "SigGroup" SG_ 1440 DevReqToDrvrDoorReByte7 "DevReqToDrvrDoorRe";
BA_ "GenSigSendType" SG_ 1440 DevReqToDrvrDoorReByte7 3;
BA_ "SigGroup" SG_ 1472 ETCBodyDevReqToDrvrSeatByte0 "ETCBodyDevReqToDrvrSeat";
BA_ "GenSigSendType" SG_ 1472 ETCBodyDevReqToDrvrSeatByte0 3;
BA_ "SigGroup" SG_ 1472 ETCBodyDevReqToDrvrSeatByte1 "ETCBodyDevReqToDrvrSeat";
BA_ "GenSigSendType" SG_ 1472 ETCBodyDevReqToDrvrSeatByte1 3;
BA_ "SigGroup" SG_ 1472 ETCBodyDevReqToDrvrSeatByte2 "ETCBodyDevReqToDrvrSeat";
BA_ "GenSigSendType" SG_ 1472 ETCBodyDevReqToDrvrSeatByte2 3;
BA_ "SigGroup" SG_ 1472 ETCBodyDevReqToDrvrSeatByte3 "ETCBodyDevReqToDrvrSeat";
BA_ "GenSigSendType" SG_ 1472 ETCBodyDevReqToDrvrSeatByte3 3;
BA_ "SigGroup" SG_ 1472 ETCBodyDevReqToDrvrSeatByte4 "ETCBodyDevReqToDrvrSeat";
BA_ "GenSigSendType" SG_ 1472 ETCBodyDevReqToDrvrSeatByte4 3;
BA_ "SigGroup" SG_ 1472 ETCBodyDevReqToDrvrSeatByte5 "ETCBodyDevReqToDrvrSeat";
BA_ "GenSigSendType" SG_ 1472 ETCBodyDevReqToDrvrSeatByte5 3;
BA_ "SigGroup" SG_ 1472 ETCBodyDevReqToDrvrSeatByte6 "ETCBodyDevReqToDrvrSeat";
BA_ "GenSigSendType" SG_ 1472 ETCBodyDevReqToDrvrSeatByte6 3;
BA_ "SigGroup" SG_ 1472 ETCBodyDevReqToDrvrSeatByte7 "ETCBodyDevReqToDrvrSeat";
BA_ "GenSigSendType" SG_ 1472 ETCBodyDevReqToDrvrSeatByte7 3;
BA_ "SigGroup" SG_ 1443 DevReqToPassDoorByte0 "DevReqToPassDoor";
BA_ "GenSigSendType" SG_ 1443 DevReqToPassDoorByte0 3;
BA_ "SigGroup" SG_ 1443 DevReqToPassDoorByte1 "DevReqToPassDoor";
BA_ "GenSigSendType" SG_ 1443 DevReqToPassDoorByte1 3;
BA_ "SigGroup" SG_ 1443 DevReqToPassDoorByte2 "DevReqToPassDoor";
BA_ "GenSigSendType" SG_ 1443 DevReqToPassDoorByte2 3;
BA_ "SigGroup" SG_ 1443 DevReqToPassDoorByte3 "DevReqToPassDoor";
BA_ "GenSigSendType" SG_ 1443 DevReqToPassDoorByte3 3;
BA_ "SigGroup" SG_ 1443 DevReqToPassDoorByte4 "DevReqToPassDoor";
BA_ "GenSigSendType" SG_ 1443 DevReqToPassDoorByte4 3;
BA_ "SigGroup" SG_ 1443 DevReqToPassDoorByte5 "DevReqToPassDoor";
BA_ "GenSigSendType" SG_ 1443 DevReqToPassDoorByte5 3;
BA_ "SigGroup" SG_ 1443 DevReqToPassDoorByte6 "DevReqToPassDoor";
BA_ "GenSigSendType" SG_ 1443 DevReqToPassDoorByte6 3;
BA_ "SigGroup" SG_ 1443 DevReqToPassDoorByte7 "DevReqToPassDoor";
BA_ "GenSigSendType" SG_ 1443 DevReqToPassDoorByte7 3;
VAL_ 528 ActvnOfDoorLiGroupActvnOfDoorAmb 0 "ActvnOfDoorSurrndgsLi_Off" 1 "ActvnOfDoorSurrndgsLi_EntryLi" 2 "ActvnOfDoorSurrndgsLi_SurrndgsLi" ;
VAL_ 528 ActvnOfDoorLiGroupActvnOfHndlAnd 0 "Boolean_FALSE" 1 "Boolean_TRUE" ;
VAL_ 528 ActvnOfDoorLiGroupAmbLiInten 0 "IntrLiInten_Off" 1 "IntrLiInten_IntenLo" 2 "IntrLiInten_IntenHi" ;
VAL_ 528 ActvnOfDoorLiGroupAmbLiRedn 0 "SurrndgsLiLvl_LvlFull" 1 "SurrndgsLiLvl_LvlReduced" ;
VAL_ 528 ChrgrSt 0 "ChrgrSts_Idle" 1 "ChrgrSts_PreStrt" 2 "ChrgrSts_Chrgn" 3 "ChrgrSts_Alrm" 4 "ChrgrSts_Srv" 5 "ChrgrSts_Diagc" 6 "ChrgrSts_Boot" 7 "ChrgrSts_Rstrt" ;
VAL_ 528 DrvrSeatDispSpplFct 0 "SeatActvSpplFct1_NotAvl" 1 "SeatActvSpplFct1_LumExtnAndLumHei" 2 "SeatActvSpplFct1_BackBlster" 3 "SeatActvSpplFct1_CushExtn" 4 "SeatActvSpplFct1_HdrestHeiAndHdrestTilt" 5 "SeatActvSpplFct1_MassgFct" ;
VAL_ 528 DstUnit 0 "DstUnit_km" 1 "DstUnit_miles" ;
VAL_ 528 EngCooltInhbFlow 0 "CooltInhb_CoolntFlowReqToEngAllwd" 1 "CooltInhb_CoolntFlowReqToEngNotAllwd" ;
VAL_ 528 EngOilPWarn 0 "EngOilPWarn1_EngOilPOk" 1 "EngOilPWarn1_EngOilPNotOk" ;
VAL_ 528 EngTQf 0 "Qf1_DevOfDataUndefd" 1 "Qf1_DataTmpUndefdAndEvlnInProgs" 2 "Qf1_DevOfDataNotWithinRngAllwd" 3 "Qf1_DataCalcdWithDevDefd" ;
VAL_ 528 HvBattHeatgReq 0 "HeatgLvlReq_Off" 1 "HeatgLvlReq_ReqLvl1" 2 "HeatgLvlReq_ReqLvl2" 3 "HeatgLvlReq_ReqLvl3" ;
VAL_ 528 HvBattHeatrVlvPosn 0 "VlvPosnForHeatg_Posn1" 1 "VlvPosnForHeatg_Posn2" ;
VAL_ 528 HvPwrEgyPrio 0 "HvPwrEgyPrio_Stb" 1 "HvPwrEgyPrio_Chrgn" 2 "HvPwrEgyPrio_ClimaWithAc" 3 "HvPwrEgyPrio_ClimaWoAc" 4 "HvPwrEgyPrio_RemClima" ;
VAL_ 528 OnBdChrgrHndlSts 0 "OnBdChrgrHndlSts_Disconnected" 1 "OnBdChrgrHndlSts_ConnectedWithoutPower" 2 "OnBdChrgrHndlSts_PowerAvailableButNotActivated" 3 "OnBdChrgrHndlSts_ConnectedWithPower" 4 "OnBdChrgrHndlSts_Init" 5 "OnBdChrgrHndlSts_Fault" ;
VAL_ 528 PassSeatSts 0 "PassSeatSts1_Empty" 1 "PassSeatSts1_Fmale" 2 "PassSeatSts1_OccptLrg" 3 "PassSeatSts1_Ukwn" ;
VAL_ 528 SeatDispBtnPsdDrvrSeatDispBtnPsd 0 "Boolean_FALSE" 1 "Boolean_TRUE" ;
VAL_ 528 SeatDispBtnPsdPassSeatDispBtnPsd 0 "Boolean_FALSE" 1 "Boolean_TRUE" ;
VAL_ 528 SteerWhlHeatgDurgClimaEnad 0 "OnOff1_Off" 1 "OnOff1_On" ;
VAL_ 608 ClimaTmrStsRqrd 0 "OnOff1_Off" 1 "OnOff1_On" ;
VAL_ 608 EgySave 0 "OnOff1_Off" 1 "OnOff1_On" ;
VAL_ 608 FuCnsIndcdUnit 0 "FuCnsIndcdUnit_LperHectoKiloM" 1 "FuCnsIndcdUnit_KiloMPerL" 2 "FuCnsIndcdUnit_MilePerGallonEngland" 3 "FuCnsIndcdUnit_MilePerGallonUsa" 4 "FuCnsIndcdUnit_UkwnUnit" ;
VAL_ 608 FuLvlLoIndcn 0 "Trig1_NoTrig" 1 "Trig1_Trig" ;
VAL_ 608 MassgFctActvDrvrMassgFctActv 0 "OnOff1_Off" 1 "OnOff1_On" ;
VAL_ 608 MassgFctActvPassMassgFctActv 0 "OnOff1_Off" 1 "OnOff1_On" ;
VAL_ 608 SeatHeatDurgClimaEnad 0 "SeatHeatDurgClimaEnad_SeatHeatOff" 1 "SeatHeatDurgClimaEnad_SeatDrvOn" 2 "SeatHeatDurgClimaEnad_SeatPassOn" 3 "SeatHeatDurgClimaEnad_SeatDrvrAndPass" ;
VAL_ 640 FuCnsAvgUnit 0 "FuCnsIndcdUnit_LperHectoKiloM" 1 "FuCnsIndcdUnit_KiloMPerL" 2 "FuCnsIndcdUnit_MilePerGallonEngland" 3 "FuCnsIndcdUnit_MilePerGallonUsa" 4 "FuCnsIndcdUnit_UkwnUnit" ;
VAL_ 592 CoolgReqForDispCen 0 "CoolgReqForDisp_NoReq" 1 "CoolgReqForDisp_LoReq" 2 "CoolgReqForDisp_HiReq" ;
VAL_ 592 CoolgReqForDrvrDisp 0 "CoolgReqForDisp_NoReq" 1 "CoolgReqForDisp_LoReq" 2 "CoolgReqForDisp_HiReq" ;
VAL_ 592 FuLvlLoWarn 0 "Trig1_NoTrig" 1 "Trig1_Trig" ;
VAL_ 592 VehSpdAvgUnit 0 "VehSpdIndcdUnit_Kmph" 1 "VehSpdIndcdUnit_Mph" 2 "VehSpdIndcdUnit_UkwnUnit" ;
VAL_ 592 VehSpdIndcdQly 0 "GenQf1_UndefindDataAccur" 1 "GenQf1_TmpUndefdData" 2 "GenQf1_DataAccurNotWithinSpcn" 3 "GenQf1_AccurData" ;
VAL_ 656 SunRoofPosnSts 0 "WinAndRoofAndCurtPosnTyp_PosnUkwn" 1 "WinAndRoofAndCurtPosnTyp_ClsFull" 2 "WinAndRoofAndCurtPosnTyp_PercOpen4" 3 "WinAndRoofAndCurtPosnTyp_PercOpen8" 4 "WinAndRoofAndCurtPosnTyp_PercOpen12" 5 "WinAndRoofAndCurtPosnTyp_PercOpen16" 6 "WinAndRoofAndCurtPosnTyp_PercOpen20" 7 "WinAndRoofAndCurtPosnTyp_PercOpen24" 8 "WinAndRoofAndCurtPosnTyp_PercOpen28" 9 "WinAndRoofAndCurtPosnTyp_PercOpen32" 10 "WinAndRoofAndCurtPosnTyp_PercOpen36" 11 "WinAndRoofAndCurtPosnTyp_PercOpen40" 12 "WinAndRoofAndCurtPosnTyp_PercOpen44" 13 "WinAndRoofAndCurtPosnTyp_PercOpen48" 14 "WinAndRoofAndCurtPosnTyp_PercOpen52" 15 "WinAndRoofAndCurtPosnTyp_PercOpen56" 16 "WinAndRoofAndCurtPosnTyp_PercOpen60" 17 "WinAndRoofAndCurtPosnTyp_PercOpen64" 18 "WinAndRoofAndCurtPosnTyp_PercOpen68" 19 "WinAndRoofAndCurtPosnTyp_PercOpen72" 20 "WinAndRoofAndCurtPosnTyp_PercOpen76" 21 "WinAndRoofAndCurtPosnTyp_PercOpen80" 22 "WinAndRoofAndCurtPosnTyp_PercOpen84" 23 "WinAndRoofAndCurtPosnTyp_PercOpen88" 24 "WinAndRoofAndCurtPosnTyp_PercOpen92" 25 "WinAndRoofAndCurtPosnTyp_PercOpen96" 26 "WinAndRoofAndCurtPosnTyp_OpenFull" 27 "WinAndRoofAndCurtPosnTyp_Resd1" 28 "WinAndRoofAndCurtPosnTyp_Resd2" 29 "WinAndRoofAndCurtPosnTyp_Resd3" 30 "WinAndRoofAndCurtPosnTyp_Resd4" 31 "WinAndRoofAndCurtPosnTyp_Movg" ;
VAL_ 624 AbsWarnIndcnReq 0 "AbsWarnIndcnReq_AbsWarnIndcnOnReq" 1 "AbsWarnIndcnReq_AbsWarnIndcnFlsgReq" 2 "AbsWarnIndcnReq_Resd2" 3 "AbsWarnIndcnReq_AbsWarnIndcnOffReq" ;
VAL_ 624 BrkWarnIndcnReq 0 "OnOff2_On" 1 "OnOff2_Off" ;
VAL_ 624 EngSt1WdSts 0 "EngSt1_Ini" 1 "EngSt1_Awake" 2 "EngSt1_Rdy" 3 "EngSt1_PreStrtg" 4 "EngSt1_StrtgInProgs" 5 "EngSt1_RunngRunng" 6 "EngSt1_RunngStb" 7 "EngSt1_RunngStrtgInProgs" 8 "EngSt1_RunngRemStrtd" 9 "EngSt1_AftRun" ;
VAL_ 624 FuLvlIndcdQly 0 "GenQf1_UndefindDataAccur" 1 "GenQf1_TmpUndefdData" 2 "GenQf1_DataAccurNotWithinSpcn" 3 "GenQf1_AccurData" ;
VAL_ 624 NetHdActvtPrio 0 "PrioHighNormal_PrioNormal" 1 "PrioHighNormal_PrioHigh" ;
VAL_ 624 NotifForEmgyCall 0 "Boolean_FALSE" 1 "Boolean_TRUE" ;
VAL_ 624 PassSeatDispSpplFct 0 "SeatActvSpplFct1_NotAvl" 1 "SeatActvSpplFct1_LumExtnAndLumHei" 2 "SeatActvSpplFct1_BackBlster" 3 "SeatActvSpplFct1_CushExtn" 4 "SeatActvSpplFct1_HdrestHeiAndHdrestTilt" 5 "SeatActvSpplFct1_MassgFct" ;
VAL_ 624 SteerWhlHeatgOnReq 0 "SteerWhlHeatgOnCmdTyp_Off" 1 "SteerWhlHeatgOnCmdTyp_Lo" 2 "SteerWhlHeatgOnCmdTyp_Med" 3 "SteerWhlHeatgOnCmdTyp_Hi" ;
VAL_ 768 DrvModReq 0 "DrvModReqType1_Undefd" 1 "DrvModReqType1_DrvMod1" 2 "DrvModReqType1_DrvMod2" 3 "DrvModReqType1_DrvMod3" 4 "DrvModReqType1_DrvMod4" 5 "DrvModReqType1_DrvMod5" 6 "DrvModReqType1_DrvMod6" 7 "DrvModReqType1_DrvMod7" 8 "DrvModReqType1_DrvMod8" 9 "DrvModReqType1_DrvMod9" 10 "DrvModReqType1_DrvMod10" 11 "DrvModReqType1_DrvMod11" 12 "DrvModReqType1_DrvMod12" 13 "DrvModReqType1_DrvMod13" 14 "DrvModReqType1_DrvMod14" 15 "DrvModReqType1_Err" ;
VAL_ 768 FuLvlRawActvSideQly 0 "GenQf1_UndefindDataAccur" 1 "GenQf1_TmpUndefdData" 2 "GenQf1_DataAccurNotWithinSpcn" 3 "GenQf1_AccurData" ;
VAL_ 784 ClkFmt 0 "ClkFmt_Hr24" 1 "ClkFmt_Hr12" 2 "ClkFmt_UkwnClkFmt" ;
VAL_ 784 DstLong 0 "DstLong_km" 1 "DstLong_miles" 2 "DstLong_UkwnUnit" ;
VAL_ 784 DstSho 0 "DstSho_Mtr" 1 "DstSho_Ft" 2 "DstSho_Yards" 3 "DstSho_UkwnUnit" ;
VAL_ 784 FltIndcrTurnRiFrnt 0 "DevErrSts2_NoFlt" 1 "DevErrSts2_Flt" ;
VAL_ 784 FltIndcrTurnRiRe 0 "DevErrSts2_NoFlt" 1 "DevErrSts2_Flt" ;
VAL_ 784 FuCnsUnit 0 "FuCnsIndcdUnit_LperHectoKiloM" 1 "FuCnsIndcdUnit_KiloMPerL" 2 "FuCnsIndcdUnit_MilePerGallonEngland" 3 "FuCnsIndcdUnit_MilePerGallonUsa" 4 "FuCnsIndcdUnit_UkwnUnit" ;
VAL_ 784 IdPenForUnits 0 "IdPen_ProfUkwn" 1 "IdPen_Prof1" 2 "IdPen_Prof2" 3 "IdPen_Prof3" 4 "IdPen_Prof4" 5 "IdPen_Prof5" 6 "IdPen_Prof6" 7 "IdPen_Prof7" 8 "IdPen_Prof8" 9 "IdPen_Prof9" 10 "IdPen_Prof10" 11 "IdPen_Prof11" 12 "IdPen_Prof12" 13 "IdPen_Prof13" 14 "IdPen_Resd14" 15 "IdPen_ProfAll" ;
VAL_ 784 IndcnUnitDateFmt 0 "DateFmt_DateFmt1" 1 "DateFmt_DateFmt2" 2 "DateFmt_DateFmt3" 3 "DateFmt_UkwnFmt" ;
VAL_ 784 PUnit 0 "PUnit_Pa" 1 "PUnit_Psi" 2 "PUnit_Bar" 3 "PUnit_Atm" 4 "PUnit_UkwnUnit" ;
VAL_ 784 SpdUnit 0 "VehSpdIndcdUnit_Kmph" 1 "VehSpdIndcdUnit_Mph" 2 "VehSpdIndcdUnit_UkwnUnit" ;
VAL_ 784 TUnit 0 "AmbTIndcdUnit_Celsius" 1 "AmbTIndcdUnit_Fahrenheit" 2 "AmbTIndcdUnit_UkwnUnit" ;
VAL_ 784 VolUnit 0 "VolUnit_litre" 1 "VolUnit_gallon1" 2 "VolUnit_gallon2" 3 "VolUnit_UkwnUnit" ;
VAL_ 464 AmbTIndcdQf 0 "GenQf1_UndefindDataAccur" 1 "GenQf1_TmpUndefdData" 2 "GenQf1_DataAccurNotWithinSpcn" 3 "GenQf1_AccurData" ;
VAL_ 464 AmbTIndcdUnit 0 "AmbTIndcdUnit_Celsius" 1 "AmbTIndcdUnit_Fahrenheit" 2 "AmbTIndcdUnit_UkwnUnit" ;
VAL_ 464 AmbTRawQly 0 "GenQf1_UndefindDataAccur" 1 "GenQf1_TmpUndefdData" 2 "GenQf1_DataAccurNotWithinSpcn" 3 "GenQf1_AccurData" ;
VAL_ 464 FltOfBeamLoLe 0 "DevErrSts2_NoFlt" 1 "DevErrSts2_Flt" ;
VAL_ 464 FltOfBrkLiHiMntd 0 "DevErrSts2_NoFlt" 1 "DevErrSts2_Flt" ;
VAL_ 464 FltOfPlateNr 0 "DevErrSts2_NoFlt" 1 "DevErrSts2_Flt" ;
VAL_ 464 FltOfPosnReRi 0 "DevErrSts2_NoFlt" 1 "DevErrSts2_Flt" ;
VAL_ 464 RlyPwrDistbnCmd1WdPreBattSaveCmd 0 "OnOff1_Off" 1 "OnOff1_On" ;
VAL_ 464 VehSpdIndcdUnit 0 "VehSpdIndcdUnit_Kmph" 1 "VehSpdIndcdUnit_Mph" 2 "VehSpdIndcdUnit_UkwnUnit" ;
VAL_ 464 WipgInfoWipgSpdInfo 0 "WipgSpdInfo_Off" 1 "WipgSpdInfo_IntlLo" 2 "WipgSpdInfo_IntlHi" 3 "WipgSpdInfo_WipgSpd4045" 4 "WipgSpdInfo_WipgSpd4650" 5 "WipgSpdInfo_WipgSpd5155" 6 "WipgSpdInfo_WipgSpd5660" 7 "WipgSpdInfo_WiprErr" ;
VAL_ 464 WipgInfoWiprActv 0 "OnOff1_Off" 1 "OnOff1_On" ;
VAL_ 464 WipgInfoWiprInWipgAr 0 "OnOff1_Off" 1 "OnOff1_On" ;
VAL_ 848 ClimaStrtTiSts 0 "OnOff1_Off" 1 "OnOff1_On" ;
VAL_ 848 FltOfPosnReLe 0 "DevErrSts2_NoFlt" 1 "DevErrSts2_Flt" ;
VAL_ 848 TiAndDateVld 0 "NoYes1_No" 1 "NoYes1_Yes" ;
VAL_ 880 ClimaCmd 0 "OkNotOk_NotOk" 1 "OkNotOk_Ok" ;
VAL_ 880 FltFogLiRe 0 "DevErrSts2_NoFlt" 1 "DevErrSts2_Flt" ;
VAL_ 880 FltIndcrTurnLeFrnt 0 "DevErrSts2_NoFlt" 1 "DevErrSts2_Flt" ;
VAL_ 880 FltLiSideMkrFrnt 0 "DevErrSts2_NoFlt" 1 "DevErrSts2_Flt" ;
VAL_ 880 FltOfBeamHiLe 0 "DevErrSts2_NoFlt" 1 "DevErrSts2_Flt" ;
VAL_ 880 FltOfBeamHiRi 0 "DevErrSts2_NoFlt" 1 "DevErrSts2_Flt" ;
VAL_ 880 FltOfBeamLoRi 0 "DevErrSts2_NoFlt" 1 "DevErrSts2_Flt" ;
VAL_ 880 FltOfLiPosnFrntLe 0 "DevErrSts2_NoFlt" 1 "DevErrSts2_Flt" ;
VAL_ 880 PwrSplyErrSts 0 "PwrSplyErrSts1_SysOk" 1 "PwrSplyErrSts1_AltFltMecl" 2 "PwrSplyErrSts1_AltFltElec" 3 "PwrSplyErrSts1_AltFltT" 4 "PwrSplyErrSts1_AltFltCom" 5 "PwrSplyErrSts1_UHiDurgDrvg" 6 "PwrSplyErrSts1_BattSwtFltCom" 7 "PwrSplyErrSts1_BattSwtHwFlt" 8 "PwrSplyErrSts1_ULoDurgDrvg" 9 "PwrSplyErrSts1_BattSnsrFltCom" 10 "PwrSplyErrSts1_BattSnsrHwFlt" 11 "PwrSplyErrSts1_SpprtBattFltChrgn" 12 "PwrSplyErrSts1_FltComDcDc" 13 "PwrSplyErrSts1_FltElecDcDc" 14 "PwrSplyErrSts1_FltTDcDc" ;
VAL_ 880 WshrFldSts 0 "OnOff1_Off" 1 "OnOff1_On" ;
VAL_ 896 AntithftActvnNotif 0 "AntithftActvnNotif1_NotActvd" 1 "AntithftActvnNotif1_Actvd" ;
VAL_ 896 CurtReDirCmd 0 "CurtDirTyp_CurtIdle" 1 "CurtDirTyp_CurtOpenAut" 2 "CurtDirTyp_CurtClsAut" 3 "CurtDirTyp_Spare" ;
VAL_ 896 FltLiDaytiRunngLe 0 "DevErrSts2_NoFlt" 1 "DevErrSts2_Flt" ;
VAL_ 896 FltOfBrkLiLe 0 "DevErrSts2_NoFlt" 1 "DevErrSts2_Flt" ;
VAL_ 896 FltOfLiDaytiRunngRi 0 "DevErrSts2_NoFlt" 1 "DevErrSts2_Flt" ;
VAL_ 896 FltOfLiPosnFrntRi 0 "DevErrSts2_NoFlt" 1 "DevErrSts2_Flt" ;
VAL_ 896 StrtRemSts1WdStrtRemSts 0 "StrtRemSts1_Idle" 1 "StrtRemSts1_Strtg" 2 "StrtRemSts1_Actv" ;
VAL_ 896 TrLockSts 0 "LockSts2_LockStsUkwn" 1 "LockSts2_Unlckd" 2 "LockSts2_Lockd" 3 "LockSts2_SafeLockd" ;
VAL_ 816 FltIndcrTurnLeRe 0 "DevErrSts2_NoFlt" 1 "DevErrSts2_Flt" ;
VAL_ 816 FltOfBrkLiRi 0 "DevErrSts2_NoFlt" 1 "DevErrSts2_Flt" ;
VAL_ 816 FltOfFogLiFrnt 0 "DevErrSts2_NoFlt" 1 "DevErrSts2_Flt" ;
VAL_ 816 ProfPenSts1 0 "IdPen_ProfUkwn" 1 "IdPen_Prof1" 2 "IdPen_Prof2" 3 "IdPen_Prof3" 4 "IdPen_Prof4" 5 "IdPen_Prof5" 6 "IdPen_Prof6" 7 "IdPen_Prof7" 8 "IdPen_Prof8" 9 "IdPen_Prof9" 10 "IdPen_Prof10" 11 "IdPen_Prof11" 12 "IdPen_Prof12" 13 "IdPen_Prof13" 14 "IdPen_Resd14" 15 "IdPen_ProfAll" ;
VAL_ 816 TirePFrntLe 0 "TirePWarn_NoWarn" 1 "TirePWarn_SoftWarn" 2 "TirePWarn_HardWarn" 3 "TirePWarn_ResdWarn" ;
VAL_ 816 TirePFrntRi 0 "TirePWarn_NoWarn" 1 "TirePWarn_SoftWarn" 2 "TirePWarn_HardWarn" 3 "TirePWarn_ResdWarn" ;
VAL_ 816 TirePMonSts 0 "TirePMonSts1_NoWarn" 1 "TirePMonSts1_SysFlt" 2 "TirePMonSts1_FourMiss" 3 "TirePMonSts1_Resd1" 4 "TirePMonSts1_GmnSoftWarn" 5 "TirePMonSts1_GmnHardWarn" 6 "TirePMonSts1_Resd2" 7 "TirePMonSts1_Resd3" 8 "TirePMonSts1_Resd4" 9 "TirePMonSts1_Resd5" ;
VAL_ 816 TirePReLe 0 "TirePWarn_NoWarn" 1 "TirePWarn_SoftWarn" 2 "TirePWarn_HardWarn" 3 "TirePWarn_ResdWarn" ;
VAL_ 816 TirePReRi 0 "TirePWarn_NoWarn" 1 "TirePWarn_SoftWarn" 2 "TirePWarn_HardWarn" 3 "TirePWarn_ResdWarn" ;
VAL_ 816 VehBattUSysUQf 0 "GenQf1_UndefindDataAccur" 1 "GenQf1_TmpUndefdData" 2 "GenQf1_DataAccurNotWithinSpcn" 3 "GenQf1_AccurData" ;
VAL_ 512 CmptmtTFrntQf 0 "CmptmtTFrntQf_SnsrDataUndefd" 1 "CmptmtTFrntQf_FanNotRunning" 2 "CmptmtTFrntQf_SnsrDataNotOk" 3 "CmptmtTFrntQf_SnsrDataOk" ;
VAL_ 512 FanForCmptmtTRunng 0 "Flg1_Rst" 1 "Flg1_Set" ;
VAL_ 50 CryptoDoorDrvrLockCmdLockActvn 0 "LockActvn4_LockActvnOff" 1 "LockActvn4_LockActvnUnlck" 2 "LockActvn4_LockActvnLock" 3 "LockActvn4_LockActvnSafe" 4 "LockActvn4_LockActvnUnlckByCrash" 5 "LockActvn4_LockActvnUnlckPrepn" ;
VAL_ 56 CryptoDoorDrvrLockReCmdLockActvn 0 "LockActvn4_LockActvnOff" 1 "LockActvn4_LockActvnUnlck" 2 "LockActvn4_LockActvnLock" 3 "LockActvn4_LockActvnSafe" 4 "LockActvn4_LockActvnUnlckByCrash" 5 "LockActvn4_LockActvnUnlckPrepn" ;
VAL_ 56 TaxiLockCmd 0 "OnOff1_Off" 1 "OnOff1_On" ;
VAL_ 53 CryptoDoorPassLockCmdLockActvn 0 "LockActvn4_LockActvnOff" 1 "LockActvn4_LockActvnUnlck" 2 "LockActvn4_LockActvnLock" 3 "LockActvn4_LockActvnSafe" 4 "LockActvn4_LockActvnUnlckByCrash" 5 "LockActvn4_LockActvnUnlckPrepn" ;
VAL_ 58 CryptoDoorPassLockReCmdLockActvn 0 "LockActvn4_LockActvnOff" 1 "LockActvn4_LockActvnUnlck" 2 "LockActvn4_LockActvnLock" 3 "LockActvn4_LockActvnSafe" 4 "LockActvn4_LockActvnUnlckByCrash" 5 "LockActvn4_LockActvnUnlckPrepn" ;
VAL_ 567 ClngRqrdFromHmi 0 "OnOffNoReq_NoReq" 1 "OnOffNoReq_On" 2 "OnOffNoReq_Off" ;
VAL_ 567 SecuAlrmMgrToTelmIniSecuAlrmMagr 0 "AuthentIninMsgTyp_NoMsg" 1 "AuthentIninMsgTyp_AuthentIninReq" 2 "AuthentIninMsgTyp_AuthentIninResp" 3 "AuthentIninMsgTyp_AuthentIninAck" ;
VAL_ 533 AirClngReq 0 "OnOffNoReq_NoReq" 1 "OnOffNoReq_On" 2 "OnOffNoReq_Off" ;
VAL_ 533 HmiSeatClimaExtdHmiSeatVentnForR 0 "SeatClimaLvl_Off" 1 "SeatClimaLvl_Lvl1" 2 "SeatClimaLvl_Lvl2" 3 "SeatClimaLvl_Lvl3" ;
VAL_ 533 HmiSeatClimaExtdHmiSeatVent_0000 0 "SeatClimaLvl_Off" 1 "SeatClimaLvl_Lvl1" 2 "SeatClimaLvl_Lvl2" 3 "SeatClimaLvl_Lvl3" ;
VAL_ 566 SecuAntithftActvnNotifSecuAntith 0 "AntithftActvnNotif1_NotActvd" 1 "AntithftActvnNotif1_Actvd" ;
VAL_ 48 ChdLockgProtnFailrStsToHmi 0 "OnOffSafe1_OnOffSafeInvld1" 1 "OnOffSafe1_OnOffSafeOn" 2 "OnOffSafe1_OnOffSafeOff" 3 "OnOffSafe1_OnOffSafeInvld2" ;
VAL_ 48 ChdLockgProtnStsToHmi 0 "OnOffSafe1_OnOffSafeInvld1" 1 "OnOffSafe1_OnOffSafeOn" 2 "OnOffSafe1_OnOffSafeOff" 3 "OnOffSafe1_OnOffSafeInvld2" ;
VAL_ 48 ChdProtnCmd 0 "OnOff1_Off" 1 "OnOff1_On" ;
VAL_ 48 CrashUnlckFailrStsAtDrvrRe 0 "OnOffSafe1_OnOffSafeInvld1" 1 "OnOffSafe1_OnOffSafeOn" 2 "OnOffSafe1_OnOffSafeOff" 3 "OnOffSafe1_OnOffSafeInvld2" ;
VAL_ 48 DoorBtnPsdAtDrvr 0 "Boolean_FALSE" 1 "Boolean_TRUE" ;
VAL_ 48 DoorDrvrLockReSts 0 "LockSts2_LockStsUkwn" 1 "LockSts2_Unlckd" 2 "LockSts2_Lockd" 3 "LockSts2_SafeLockd" ;
VAL_ 48 DoorDrvrLockSts 0 "LockSts2_LockStsUkwn" 1 "LockSts2_Unlckd" 2 "LockSts2_Lockd" 3 "LockSts2_SafeLockd" ;
VAL_ 48 DoorDrvrSwtIntrLockgReq 0 "LockgCenReq2_Idle" 1 "LockgCenReq2_Unlck" 2 "LockgCenReq2_Lock" ;
VAL_ 48 DoorDrvrSwtLockgReSts 0 "PsdNotPsd1_NotPsd" 1 "PsdNotPsd1_Psd" ;
VAL_ 48 LcmaLedStsDrvrSide 0 "OkNotOk1_Ok" 1 "OkNotOk1_NotOk" ;
VAL_ 48 MemBtn1 0 "Boolean_FALSE" 1 "Boolean_TRUE" ;
VAL_ 48 MemBtn2 0 "Boolean_FALSE" 1 "Boolean_TRUE" ;
VAL_ 48 MemBtn3 0 "Boolean_FALSE" 1 "Boolean_TRUE" ;
VAL_ 48 MemBtnM 0 "Boolean_FALSE" 1 "Boolean_TRUE" ;
VAL_ 48 MirrAtDrvrInMovmt 0 "Boolean_FALSE" 1 "Boolean_TRUE" ;
VAL_ 48 MirrBtnPsdAtDrvr 0 "Boolean_FALSE" 1 "Boolean_TRUE" ;
VAL_ 48 MirrCmdAtPassAdj 0 "MirrAdjCmdTyp_Idle" 1 "MirrAdjCmdTyp_Up" 2 "MirrAdjCmdTyp_Dwn" 3 "MirrAdjCmdTyp_Le" 4 "MirrAdjCmdTyp_Ri" ;
VAL_ 48 MirrCmdAtPassDwn 0 "MirrDwnCmdTyp_Idle" 1 "MirrDwnCmdTyp_MirrUp" 2 "MirrDwnCmdTyp_MirrDwn" ;
VAL_ 48 MirrCmdAtPassFold 0 "MirrFoldCmdTyp_Idle" 1 "MirrFoldCmdTyp_FoldIn" 2 "MirrFoldCmdTyp_FoldOut" ;
VAL_ 48 MirrFoldStsAtDrvr 0 "MirrFoldStsTyp_MirrFoldPosnUndefd" 1 "MirrFoldStsTyp_MirrNotFoldPosn" 2 "MirrFoldStsTyp_MirrFoldPosn" 3 "MirrFoldStsTyp_MirrMovgToNotFold" 4 "MirrFoldStsTyp_MirrMovgToFold" ;
VAL_ 48 WinPosnStsAtDrvrRe 0 "WinAndRoofAndCurtPosnTyp_PosnUkwn" 1 "WinAndRoofAndCurtPosnTyp_ClsFull" 2 "WinAndRoofAndCurtPosnTyp_PercOpen4" 3 "WinAndRoofAndCurtPosnTyp_PercOpen8" 4 "WinAndRoofAndCurtPosnTyp_PercOpen12" 5 "WinAndRoofAndCurtPosnTyp_PercOpen16" 6 "WinAndRoofAndCurtPosnTyp_PercOpen20" 7 "WinAndRoofAndCurtPosnTyp_PercOpen24" 8 "WinAndRoofAndCurtPosnTyp_PercOpen28" 9 "WinAndRoofAndCurtPosnTyp_PercOpen32" 10 "WinAndRoofAndCurtPosnTyp_PercOpen36" 11 "WinAndRoofAndCurtPosnTyp_PercOpen40" 12 "WinAndRoofAndCurtPosnTyp_PercOpen44" 13 "WinAndRoofAndCurtPosnTyp_PercOpen48" 14 "WinAndRoofAndCurtPosnTyp_PercOpen52" 15 "WinAndRoofAndCurtPosnTyp_PercOpen56" 16 "WinAndRoofAndCurtPosnTyp_PercOpen60" 17 "WinAndRoofAndCurtPosnTyp_PercOpen64" 18 "WinAndRoofAndCurtPosnTyp_PercOpen68" 19 "WinAndRoofAndCurtPosnTyp_PercOpen72" 20 "WinAndRoofAndCurtPosnTyp_PercOpen76" 21 "WinAndRoofAndCurtPosnTyp_PercOpen80" 22 "WinAndRoofAndCurtPosnTyp_PercOpen84" 23 "WinAndRoofAndCurtPosnTyp_PercOpen88" 24 "WinAndRoofAndCurtPosnTyp_PercOpen92" 25 "WinAndRoofAndCurtPosnTyp_PercOpen96" 26 "WinAndRoofAndCurtPosnTyp_OpenFull" 27 "WinAndRoofAndCurtPosnTyp_Resd1" 28 "WinAndRoofAndCurtPosnTyp_Resd2" 29 "WinAndRoofAndCurtPosnTyp_Resd3" 30 "WinAndRoofAndCurtPosnTyp_Resd4" 31 "WinAndRoofAndCurtPosnTyp_Movg" ;
VAL_ 48 WinSwtReqToPass 0 "WinPosnReq_Idle" 1 "WinPosnReq_UpMan" 2 "WinPosnReq_UpAut" 3 "WinPosnReq_DwnMan" 4 "WinPosnReq_DwnAut" 5 "WinPosnReq_NotDefd" ;
VAL_ 48 WinSwtReqToPassRe 0 "WinPosnReq_Idle" 1 "WinPosnReq_UpMan" 2 "WinPosnReq_UpAut" 3 "WinPosnReq_DwnMan" 4 "WinPosnReq_DwnAut" 5 "WinPosnReq_NotDefd" ;
VAL_ 480 ActvnOfDoorSwtIllmn 0 "Boolean_FALSE" 1 "Boolean_TRUE" ;
VAL_ 480 AmbTQlyAtDrvrSide 0 "GenQf1_UndefindDataAccur" 1 "GenQf1_TmpUndefdData" 2 "GenQf1_DataAccurNotWithinSpcn" 3 "GenQf1_AccurData" ;
VAL_ 480 ChdWinProtnStsAtDrvrRe 0 "OnOff1_Off" 1 "OnOff1_On" ;
VAL_ 480 CrashUnlckFailrStsAtDrvr 0 "OnOffSafe1_OnOffSafeInvld1" 1 "OnOffSafe1_OnOffSafeOn" 2 "OnOffSafe1_OnOffSafeOff" 3 "OnOffSafe1_OnOffSafeInvld2" ;
VAL_ 480 FltOfPuddleLiDrvr 0 "DevErrSts2_NoFlt" 1 "DevErrSts2_Flt" ;
VAL_ 480 LiDrvrFltIndcrTurn 0 "DevErrSts2_NoFlt" 1 "DevErrSts2_Flt" ;
VAL_ 480 MirrDefrstAtDrvSts 0 "OnOff1_Off" 1 "OnOff1_On" ;
VAL_ 480 MirrDwnStsAtDrvr 0 "MirrDwnStsTyp_MirrTiltUndefd" 1 "MirrDwnStsTyp_MirrUpPosn" 2 "MirrDwnStsTyp_MirrTiltPosn" 3 "MirrDwnStsTyp_MirrMovgToUpPosn" 4 "MirrDwnStsTyp_MirrMovgToTiltPosn" ;
VAL_ 480 WinPosnStsDrv 0 "WinAndRoofAndCurtPosnTyp_PosnUkwn" 1 "WinAndRoofAndCurtPosnTyp_ClsFull" 2 "WinAndRoofAndCurtPosnTyp_PercOpen4" 3 "WinAndRoofAndCurtPosnTyp_PercOpen8" 4 "WinAndRoofAndCurtPosnTyp_PercOpen12" 5 "WinAndRoofAndCurtPosnTyp_PercOpen16" 6 "WinAndRoofAndCurtPosnTyp_PercOpen20" 7 "WinAndRoofAndCurtPosnTyp_PercOpen24" 8 "WinAndRoofAndCurtPosnTyp_PercOpen28" 9 "WinAndRoofAndCurtPosnTyp_PercOpen32" 10 "WinAndRoofAndCurtPosnTyp_PercOpen36" 11 "WinAndRoofAndCurtPosnTyp_PercOpen40" 12 "WinAndRoofAndCurtPosnTyp_PercOpen44" 13 "WinAndRoofAndCurtPosnTyp_PercOpen48" 14 "WinAndRoofAndCurtPosnTyp_PercOpen52" 15 "WinAndRoofAndCurtPosnTyp_PercOpen56" 16 "WinAndRoofAndCurtPosnTyp_PercOpen60" 17 "WinAndRoofAndCurtPosnTyp_PercOpen64" 18 "WinAndRoofAndCurtPosnTyp_PercOpen68" 19 "WinAndRoofAndCurtPosnTyp_PercOpen72" 20 "WinAndRoofAndCurtPosnTyp_PercOpen76" 21 "WinAndRoofAndCurtPosnTyp_PercOpen80" 22 "WinAndRoofAndCurtPosnTyp_PercOpen84" 23 "WinAndRoofAndCurtPosnTyp_PercOpen88" 24 "WinAndRoofAndCurtPosnTyp_PercOpen92" 25 "WinAndRoofAndCurtPosnTyp_PercOpen96" 26 "WinAndRoofAndCurtPosnTyp_OpenFull" 27 "WinAndRoofAndCurtPosnTyp_Resd1" 28 "WinAndRoofAndCurtPosnTyp_Resd2" 29 "WinAndRoofAndCurtPosnTyp_Resd3" 30 "WinAndRoofAndCurtPosnTyp_Resd4" 31 "WinAndRoofAndCurtPosnTyp_Movg" ;
SIG_GROUP_ 528 ActvnOfDoorLiGroup 1 : ActvnOfDoorLiGroupActvnOfDoorAmb ActvnOfDoorLiGroupActvnOfHndlAnd ActvnOfDoorLiGroupAmbLiInten ActvnOfDoorLiGroupAmbLiRedn;
SIG_GROUP_ 528 DstToEmptyIndcd 1 : DstToEmpty DstUnit;
SIG_GROUP_ 528 EngTGrp 1 : EngT EngTQf;
SIG_GROUP_ 528 SeatDispBtnPsd 1 : SeatDispBtnPsdDrvrSeatDispBtnPsd SeatDispBtnPsdPassSeatDispBtnPsd;
SIG_GROUP_ 544 UkwnCptReqToTelm 1 : UkwnCptReqToTelmByte0 UkwnCptReqToTelmByte1 UkwnCptReqToTelmByte2 UkwnCptReqToTelmByte3 UkwnCptReqToTelmByte4 UkwnCptReqToTelmByte5 UkwnCptReqToTelmByte6 UkwnCptReqToTelmByte7;
SIG_GROUP_ 608 FuCnsIndcd 1 : FuCnsIndcdUnit FuCnsIndcdVal;
SIG_GROUP_ 608 MassgFctActv 1 : MassgFctActvDrvrMassgFctActv MassgFctActvPassMassgFctActv;
SIG_GROUP_ 640 FuCnsAvgIndcd 1 : FuCnsAvg FuCnsAvgUnit;
SIG_GROUP_ 592 VehSpdAvgIndcd 1 : VehSpdAvg VehSpdAvgUnit;
SIG_GROUP_ 624 BrkAndAbsWarnIndcnReqGroup 1 : AbsWarnIndcnReq BrkAndAbsWarnIndcnReqChks BrkAndAbsWarnIndcnReqCntr BrkWarnIndcnReq;
SIG_GROUP_ 624 FuLvlIndcd 1 : FuLvlIndcdQly FuLvlIndcdVal;
SIG_GROUP_ 624 NetHdActvt 1 : NetHdActvtPrio NetHdActvtResourceGroup;
SIG_GROUP_ 768 EngNSafe 1 : EngN EngNChks EngNCntr EngNSafeEngNGrdt;
SIG_GROUP_ 768 FuLvlRawActvSide 1 : FuLvlRawActvSideQly FuLvlRawActvSideVal;
SIG_GROUP_ 784 IndcnUnit 1 : ClkFmt DstLong DstSho FuCnsUnit IdPenForUnits IndcnUnitDateFmt PUnit SpdUnit TUnit VolUnit;
SIG_GROUP_ 464 AmbTIndcdWithUnit 1 : AmbTIndcd AmbTIndcdQf AmbTIndcdUnit;
SIG_GROUP_ 464 AmbTRaw 1 : AmbTRawQly AmbTRawVal;
SIG_GROUP_ 464 VehSpdIndcd 1 : VehSpdIndcdUnit VehSpdIndcdVal;
SIG_GROUP_ 464 WipgInfo 1 : WipgInfoWipgSpdInfo WipgInfoWiprActv WipgInfoWiprInWipgAr;
SIG_GROUP_ 848 TiAndDateIndcn 1 : Day Hr Mins Mth Sec TiAndDateVld Yr;
SIG_GROUP_ 864 Vin 1 : VinBlk VinPosn1 VinPosn2 VinPosn3 VinPosn4 VinPosn5 VinPosn6 VinPosn7;
SIG_GROUP_ 896 IndcrPatCmd1WdCmd 1 : IndcrPatCmd1WdTiOff IndcrPatCmd1WdTiOn;
SIG_GROUP_ 816 TirePMonData 1 : TirePFrntLe TirePFrntRi TirePMonSts TirePReLe TirePReRi;
SIG_GROUP_ 816 VehBattUGroup 1 : VehBattUSysU VehBattUSysUQf;
SIG_GROUP_ 832 VehCfgPrm 1 : VehCfgPrmBlk VehCfgPrmVal1 VehCfgPrmVal2 VehCfgPrmVal3 VehCfgPrmVal4 VehCfgPrmVal5 VehCfgPrmVal6 VehCfgPrmVal7;
SIG_GROUP_ 512 CmptmtTFrntGroup 1 : CmptmtTFrnt CmptmtTFrntQf FanForCmptmtTRunng;
SIG_GROUP_ 50 CryptoDoorDrvrLockCmd 1 : CryptoDoorDrvrLockCmdAuthentCod1 CryptoDoorDrvrLockCmdAuthentCod2 CryptoDoorDrvrLockCmdCntr CryptoDoorDrvrLockCmdLockActvn;
SIG_GROUP_ 56 CryptoDoorDrvrLockReCmd 1 : CryptoDoorDrvrLockReCmdAuthentCo CryptoDoorDrvrLockReCmdAuth_0000 CryptoDoorDrvrLockReCmdCntr CryptoDoorDrvrLockReCmdLockActvn;
SIG_GROUP_ 53 CryptoDoorPassLockCmd 1 : CryptoDoorPassLockCmdAuthentCod1 CryptoDoorPassLockCmdAuthentCod2 CryptoDoorPassLockCmdCntr CryptoDoorPassLockCmdLockActvn;
SIG_GROUP_ 58 CryptoDoorPassLockReCmd 1 : CryptoDoorPassLockReCmdAuthentCo CryptoDoorPassLockReCmdAuth_0000 CryptoDoorPassLockReCmdCntr CryptoDoorPassLockReCmdLockActvn;
SIG_GROUP_ 567 SecuAlrmMgrToTelmIni 1 : SecuAlrmMgrToTelmIniMsgAuthentCo SecuAlrmMgrToTelmIniMsgAuth_0000 SecuAlrmMgrToTelmIniSecuAlrmMagr SecuAlrmMgrToTelmIniSecuIniNrRnd SecuAlrmMgrToTelmIniSecuIni_0000 SecuAlrmMgrToTelmIniSecuIni_0001;
SIG_GROUP_ 533 HmiSeatClimaExtd 1 : HmiSeatClimaExtdHmiSeatVentnForR HmiSeatClimaExtdHmiSeatVent_0000;
SIG_GROUP_ 566 SecuAntithftActvnNotif 1 : SecuAntithftActvnNotifSecuAntith SecuAntithftActvnNotifSecuA_0000 SecuAntithftActvnNotifSecuA_0001;
SIG_GROUP_ 1452 TirePMonForDevData 1 : TirePMonForDevDataByte0 TirePMonForDevDataByte1 TirePMonForDevDataByte2 TirePMonForDevDataByte3 TirePMonForDevDataByte4 TirePMonForDevDataByte5 TirePMonForDevDataByte6 TirePMonForDevDataByte7;
SIG_GROUP_ 48 MemBtnPsd 1 : MemBtn1 MemBtn2 MemBtn3 MemBtnM;
SIG_GROUP_ 48 MirrCmdAtPassGroup 1 : MirrCmdAtPassAdj MirrCmdAtPassDwn MirrCmdAtPassFold;
SIG_GROUP_ 480 AmbTRawAtDrvrSide 1 : AmbTQlyAtDrvrSide AmbTValAtDrvrSide;
SIG_GROUP_ 304 CryptoDoorDrvrLockCmdInin 1 : CryptoDoorDrvrLockCmdIninCmdInin CryptoDoorDrvrLockCmdIninCm_0000 CryptoDoorDrvrLockCmdIninCm_0001;
SIG_GROUP_ 304 CryptoDoorDrvrLockReCmdInin 1 : CryptoDoorDrvrLockReCmdIninCmdIn CryptoDoorDrvrLockReCmdInin_0000 CryptoDoorDrvrLockReCmdInin_0001;
SIG_GROUP_ 1427 DevRespAtDrvrDoor 1 : DevRespAtDrvrDoorByte0 DevRespAtDrvrDoorByte1 DevRespAtDrvrDoorByte2 DevRespAtDrvrDoorByte3 DevRespAtDrvrDoorByte4 DevRespAtDrvrDoorByte5 DevRespAtDrvrDoorByte6 DevRespAtDrvrDoorByte7;
SIG_GROUP_ 1430 DevRespAtDrvrDoorRe 1 : DevRespAtDrvrDoorReByte0 DevRespAtDrvrDoorReByte1 DevRespAtDrvrDoorReByte2 DevRespAtDrvrDoorReByte3 DevRespAtDrvrDoorReByte4 DevRespAtDrvrDoorReByte5 DevRespAtDrvrDoorReByte6 DevRespAtDrvrDoorReByte7;
SIG_GROUP_ 1425 DevTx1AtDrvrDoor 1 : DevTx1AtDrvrDoorByte0 DevTx1AtDrvrDoorByte1 DevTx1AtDrvrDoorByte2 DevTx1AtDrvrDoorByte3 DevTx1AtDrvrDoorByte4 DevTx1AtDrvrDoorByte5 DevTx1AtDrvrDoorByte6 DevTx1AtDrvrDoorByte7;
SIG_GROUP_ 1428 DevTx1AtDrvrDoorRe 1 : DevTx1AtDrvrDoorReByte0 DevTx1AtDrvrDoorReByte1 DevTx1AtDrvrDoorReByte2 DevTx1AtDrvrDoorReByte3 DevTx1AtDrvrDoorReByte4 DevTx1AtDrvrDoorReByte5 DevTx1AtDrvrDoorReByte6 DevTx1AtDrvrDoorReByte7;
SIG_GROUP_ 1426 DevTx2AtDrvrDoor 1 : DevTx2AtDrvrDoorByte0 DevTx2AtDrvrDoorByte1 DevTx2AtDrvrDoorByte2 DevTx2AtDrvrDoorByte3 DevTx2AtDrvrDoorByte4 DevTx2AtDrvrDoorByte5 DevTx2AtDrvrDoorByte6 DevTx2AtDrvrDoorByte7;
SIG_GROUP_ 1429 DevTx2AtDrvrDoorRe 1 : DevTx2AtDrvrDoorReByte0 DevTx2AtDrvrDoorReByte1 DevTx2AtDrvrDoorReByte2 DevTx2AtDrvrDoorReByte3 DevTx2AtDrvrDoorReByte4 DevTx2AtDrvrDoorReByte5 DevTx2AtDrvrDoorReByte6 DevTx2AtDrvrDoorReByte7;
SIG_GROUP_ 1488 EndOfLineSigCtrlr 1 : EndOfLineSigCtrlrByte0 EndOfLineSigCtrlrByte1 EndOfLineSigCtrlrByte2 EndOfLineSigCtrlrByte3 EndOfLineSigCtrlrByte4 EndOfLineSigCtrlrByte5 EndOfLineSigCtrlrByte6 EndOfLineSigCtrlrByte7;
SIG_GROUP_ 1441 DevReqToDrvrDoor 1 : DevReqToDrvrDoorByte0 DevReqToDrvrDoorByte1 DevReqToDrvrDoorByte2 DevReqToDrvrDoorByte3 DevReqToDrvrDoorByte4 DevReqToDrvrDoorByte5 DevReqToDrvrDoorByte6 DevReqToDrvrDoorByte7;
SIG_GROUP_ 1440 DevReqToDrvrDoorRe 1 : DevReqToDrvrDoorReByte0 DevReqToDrvrDoorReByte1 DevReqToDrvrDoorReByte2 DevReqToDrvrDoorReByte3 DevReqToDrvrDoorReByte4 DevReqToDrvrDoorReByte5 DevReqToDrvrDoorReByte6 DevReqToDrvrDoorReByte7;
SIG_GROUP_ 1472 ETCBodyDevReqToDrvrSeat 1 : ETCBodyDevReqToDrvrSeatByte0 ETCBodyDevReqToDrvrSeatByte1 ETCBodyDevReqToDrvrSeatByte2 ETCBodyDevReqToDrvrSeatByte3 ETCBodyDevReqToDrvrSeatByte4 ETCBodyDevReqToDrvrSeatByte5 ETCBodyDevReqToDrvrSeatByte6 ETCBodyDevReqToDrvrSeatByte7;
SIG_GROUP_ 1443 DevReqToPassDoor 1 : DevReqToPassDoorByte0 DevReqToPassDoorByte1 DevReqToPassDoorByte2 DevReqToPassDoorByte3 DevReqToPassDoorByte4 DevReqToPassDoorByte5 DevReqToPassDoorByte6 DevReqToPassDoorByte7;
